VERSION "HNNBNNNYNNNNNNNNNNNNNNNNNNNNNNNNNNNNNNNNNN/4/%%%/4/'%**4NNN///"

NS_ :

BS_:

BU_: ADR_PAG_X2 BAP_Tester GW_App_PAG_PF GW_Routing_PAG_PF Klima_PAG_PF Klimakomp_Dash_PAG_PF Kombi_PAG_PF Miko_PAG_X2 OCU_PAG_PF RDK_High_PAG_PF

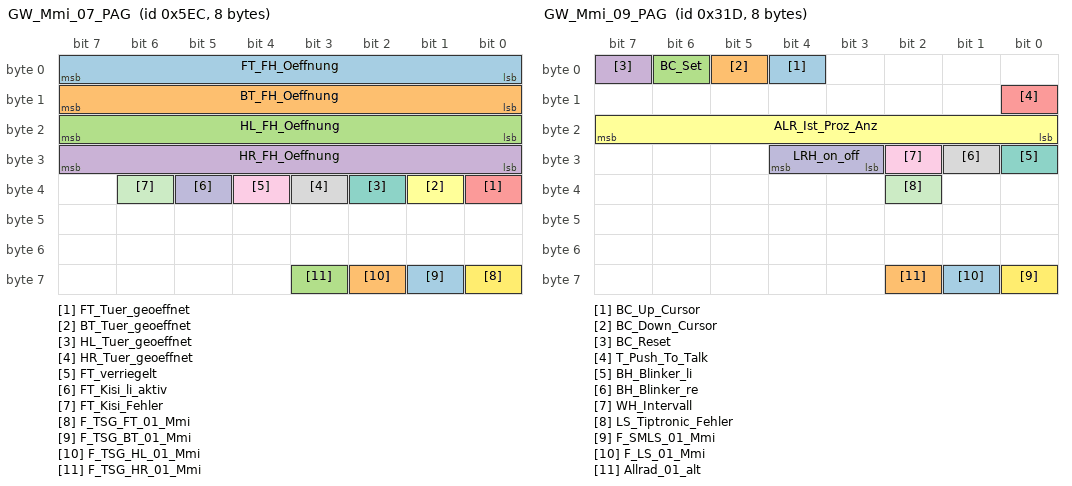
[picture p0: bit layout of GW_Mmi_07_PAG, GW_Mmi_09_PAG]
BO_ 1516 GW_Mmi_07_PAG: 8 GW_Routing_PAG_PF
 SG_ FT_FH_Oeffnung : 0|8@1+ (0.5,0) [0|100] "Unit_PerCent"  Klima_PAG_PF,OCU_PAG_PF
 SG_ BT_FH_Oeffnung : 8|8@1+ (0.5,0) [0|100] "Unit_PerCent"  Klima_PAG_PF,OCU_PAG_PF
 SG_ HL_FH_Oeffnung : 16|8@1+ (0.5,0) [0|100] "Unit_PerCent" Vector__XXX
 SG_ HR_FH_Oeffnung : 24|8@1+ (0.5,0) [0|100] "Unit_PerCent" Vector__XXX
 SG_ FT_Tuer_geoeffnet : 32|1@1+ (1,0) [0|1] ""  ADR_PAG_X2,Klima_PAG_PF,Kombi_PAG_PF
 SG_ BT_Tuer_geoeffnet : 33|1@1+ (1,0) [0|1] ""  Klima_PAG_PF,Kombi_PAG_PF
 SG_ HL_Tuer_geoeffnet : 34|1@1+ (1,0) [0|1] "" Vector__XXX
 SG_ HR_Tuer_geoeffnet : 35|1@1+ (1,0) [0|1] "" Vector__XXX
 SG_ FT_verriegelt : 36|1@1+ (1,0) [0|1] ""  Kombi_PAG_PF
 SG_ FT_Kisi_li_aktiv : 37|1@1+ (1,0) [0|1] ""  Klima_PAG_PF
 SG_ FT_Kisi_Fehler : 38|1@1+ (1,0) [0|1] "" Vector__XXX
 SG_ F_TSG_FT_01_Mmi : 56|1@1+ (1,0) [0|1] ""  ADR_PAG_X2,Klima_PAG_PF,Kombi_PAG_PF,OCU_PAG_PF
 SG_ F_TSG_BT_01_Mmi : 57|1@1+ (1,0) [0|1] ""  Klima_PAG_PF,Kombi_PAG_PF,OCU_PAG_PF
 SG_ F_TSG_HL_01_Mmi : 58|1@1+ (1,0) [0|1] "" Vector__XXX
 SG_ F_TSG_HR_01_Mmi : 59|1@1+ (1,0) [0|1] "" Vector__XXX

BO_ 797 GW_Mmi_09_PAG: 8 GW_Routing_PAG_PF
 SG_ BC_Up_Cursor : 4|1@1+ (1,0) [0|1] ""  Kombi_PAG_PF
 SG_ BC_Down_Cursor : 5|1@1+ (1,0) [0|1] ""  Kombi_PAG_PF
 SG_ BC_Set : 6|1@1+ (1,0) [0|1] ""  Kombi_PAG_PF
 SG_ BC_Reset : 7|1@1+ (1,0) [0|1] ""  Kombi_PAG_PF
 SG_ T_Push_To_Talk : 8|1@1+ (1,0) [0|1] "" Vector__XXX
 SG_ ALR_Ist_Proz_Anz : 16|8@1+ (0.4,0) [0|100] "Unit_PerCent" Vector__XXX
 SG_ BH_Blinker_li : 24|1@1+ (1,0) [0|1] "" Vector__XXX
 SG_ BH_Blinker_re : 25|1@1+ (1,0) [0|1] "" Vector__XXX
 SG_ WH_Intervall : 26|1@1+ (1,0) [0|1] ""  Klima_PAG_PF
 SG_ LRH_on_off : 27|2@1+ (1,0) [0|3] "" Vector__XXX
 SG_ LS_Tiptronic_Fehler : 34|1@1+ (1,0) [0|1] "" Vector__XXX
 SG_ F_SMLS_01_Mmi : 56|1@1+ (1,0) [0|1] ""  Klima_PAG_PF,Kombi_PAG_PF
 SG_ F_LS_01_Mmi : 57|1@1+ (1,0) [0|1] ""  Kombi_PAG_PF
 SG_ Allrad_01_alt : 58|1@1+ (1,0) [0|1] "" Vector__XXX

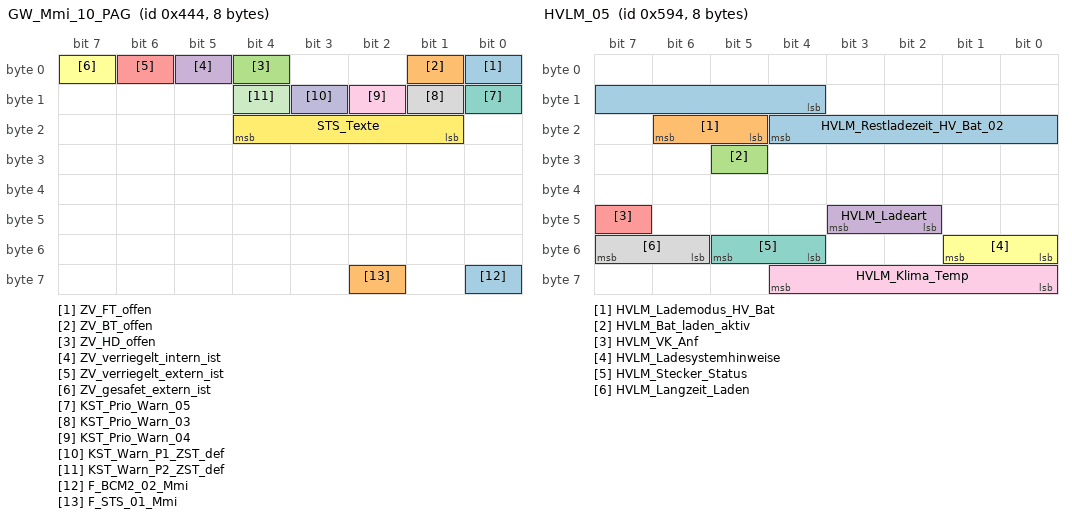
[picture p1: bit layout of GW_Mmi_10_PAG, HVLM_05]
BO_ 1092 GW_Mmi_10_PAG: 8 GW_Routing_PAG_PF
 SG_ ZV_FT_offen : 0|1@1+ (1,0) [0|1] "" Vector__XXX
 SG_ ZV_BT_offen : 1|1@1+ (1,0) [0|1] "" Vector__XXX
 SG_ ZV_HD_offen : 4|1@1+ (1,0) [0|1] ""  Kombi_PAG_PF
 SG_ ZV_verriegelt_intern_ist : 5|1@1+ (1,0) [0|1] ""  Klima_PAG_PF
 SG_ ZV_verriegelt_extern_ist : 6|1@1+ (1,0) [0|1] ""  ADR_PAG_X2
 SG_ ZV_gesafet_extern_ist : 7|1@1+ (1,0) [0|1] "" Vector__XXX
 SG_ KST_Prio_Warn_05 : 8|1@1+ (1,0) [0|1] ""  Kombi_PAG_PF
 SG_ KST_Prio_Warn_03 : 9|1@1+ (1,0) [0|1] ""  Kombi_PAG_PF
 SG_ KST_Prio_Warn_04 : 10|1@1+ (1,0) [0|1] ""  Kombi_PAG_PF
 SG_ KST_Warn_P1_ZST_def : 11|1@1+ (1,0) [0|1] ""  Kombi_PAG_PF
 SG_ KST_Warn_P2_ZST_def : 12|1@1+ (1,0) [0|1] ""  Kombi_PAG_PF
 SG_ STS_Texte : 17|4@1+ (1,0) [0|15] ""  Kombi_PAG_PF
 SG_ F_BCM2_02_Mmi : 56|1@1+ (1,0) [0|1] ""  ADR_PAG_X2,Klima_PAG_PF,Kombi_PAG_PF
 SG_ F_STS_01_Mmi : 58|1@1+ (1,0) [0|1] ""  Kombi_PAG_PF

BO_ 1315 GW_SVB_PAG: 8 GW_App_PAG_PF
 SG_ SVB_MEM_FS : 0|1@1+ (1,0) [0|1] "" Vector__XXX
 SG_ SVB_MEM_BFS : 1|1@1+ (1,0) [0|1] "" Vector__XXX
 SG_ SVB_SMLS : 2|1@1+ (1,0) [0|1] ""  Kombi_PAG_PF
 SG_ SVB_HDSG : 3|1@1+ (1,0) [0|1] "" Vector__XXX
 SG_ SVB_Lift : 4|1@1+ (1,0) [0|1] ""  Kombi_PAG_PF
 SG_ SVB_AAG : 5|1@1+ (1,0) [0|1] "" Vector__XXX
 SG_ SVB_TSG_FT : 6|1@1+ (1,0) [0|1] ""  Kombi_PAG_PF
 SG_ SVB_TSG_BT : 7|1@1+ (1,0) [0|1] ""  Kombi_PAG_PF
 SG_ SVB_RDK : 8|1@1+ (1,0) [0|1] ""  Kombi_PAG_PF
 SG_ SVB_BCM1 : 9|1@1+ (1,0) [0|1] ""  Kombi_PAG_PF
 SG_ SVB_BCM2 : 10|1@1+ (1,0) [0|1] ""  Kombi_PAG_PF
 SG_ SVB_TSG_HL : 11|1@1+ (1,0) [0|1] "" Vector__XXX
 SG_ SVB_TSG_HR : 12|1@1+ (1,0) [0|1] "" Vector__XXX
 SG_ SVB_VSG : 13|1@1+ (1,0) [0|1] "" Vector__XXX
 SG_ SVB_Topview : 14|1@1+ (1,0) [0|1] "" Vector__XXX
 SG_ SVB_Kombi : 16|1@1+ (1,0) [0|1] "" Vector__XXX
 SG_ SVB_BKE : 17|1@1+ (1,0) [0|1] ""  Kombi_PAG_PF
 SG_ SVB_PDC : 18|1@1+ (1,0) [0|1] "" Vector__XXX
 SG_ SVB_STH : 19|1@1+ (1,0) [0|1] "" Vector__XXX
 SG_ SVB_RearView : 20|1@1+ (1,0) [0|1] "" Vector__XXX
 SG_ SVB_Stoppuhr : 21|1@1+ (1,0) [0|1] "" Vector__XXX
 SG_ SVB_PCM : 22|1@1+ (1,0) [0|1] ""  Kombi_PAG_PF
 SG_ SVB_CDR : 23|1@1+ (1,0) [0|1] "" Vector__XXX
 SG_ SVB_Kompass : 24|1@1+ (1,0) [0|1] "" Vector__XXX
 SG_ SVB_ComBox : 25|1@1+ (1,0) [0|1] "" Vector__XXX
 SG_ SVB_LEH_VA : 26|1@1+ (1,0) [0|1] "" Vector__XXX
 SG_ SVB_Ladegeraet : 27|1@1+ (1,0) [0|1] "" Vector__XXX
 SG_ SVB_Motor : 28|1@1+ (1,0) [0|1] ""  Kombi_PAG_PF
 SG_ SVB_QSP : 29|1@1+ (1,0) [0|1] ""  Kombi_PAG_PF
 SG_ SVB_Getriebe : 30|1@1+ (1,0) [0|1] ""  Kombi_PAG_PF
 SG_ SVB_WHL : 31|1@1+ (1,0) [0|1] "" Vector__XXX
 SG_ SVB_Airbag : 32|1@1+ (1,0) [0|1] ""  Kombi_PAG_PF
 SG_ SVB_PSM_Ant : 33|1@1+ (1,0) [0|1] "" Vector__XXX
 SG_ SVB_PSM_Fwk : 34|1@1+ (1,0) [0|1] ""  Kombi_PAG_PF
 SG_ SVB_BMS : 35|1@1+ (1,0) [0|1] "" Vector__XXX
 SG_ SVB_LEH : 36|1@1+ (1,0) [0|1] "" Vector__XXX
 SG_ SVB_SCR : 37|1@1+ (1,0) [0|1] "" Vector__XXX
 SG_ SVB_EPB : 38|1@1+ (1,0) [0|1] ""  Kombi_PAG_PF
 SG_ SVB_SSC : 39|1@1+ (1,0) [0|1] "" Vector__XXX
 SG_ SVB_PDCC : 40|1@1+ (1,0) [0|1] ""  Kombi_PAG_PF
 SG_ SVB_LWS : 41|1@1+ (1,0) [0|1] "" Vector__XXX
 SG_ SVB_PASM_NRA : 42|1@1+ (1,0) [0|1] ""  Kombi_PAG_PF
 SG_ SVB_Allrad : 43|1@1+ (1,0) [0|1] "" Vector__XXX
 SG_ SVB_EPS : 44|1@1+ (1,0) [0|1] ""  Kombi_PAG_PF
 SG_ SVB_HAL : 45|1@1+ (1,0) [0|1] ""  Kombi_PAG_PF
 SG_ SVB_EBKV : 46|1@1+ (1,0) [0|1] "" Vector__XXX
 SG_ SVB_AFS : 47|1@1+ (1,0) [0|1] ""  Kombi_PAG_PF
 SG_ SVB_SWL : 48|1@1+ (1,0) [0|1] "" Vector__XXX
 SG_ SVB_SWR : 49|1@1+ (1,0) [0|1] "" Vector__XXX
 SG_ SVB_ACC : 50|1@1+ (1,0) [0|1] "" Vector__XXX
 SG_ SVB_SWA : 51|1@1+ (1,0) [0|1] "" Vector__XXX
 SG_ SVB_EHPS : 53|1@1+ (1,0) [0|1] "" Vector__XXX
 SG_ SVB_EKK : 54|1@1+ (1,0) [0|1] "" Vector__XXX
 SG_ SVB_Kamera : 55|1@1+ (1,0) [0|1] "" Vector__XXX
 SG_ SVB_AMP : 57|1@1+ (1,0) [0|1] "" Vector__XXX
 SG_ SVB_TV : 58|1@1+ (1,0) [0|1] "" Vector__XXX

BO_ 1428 HVLM_05: 8 GW_Routing_PAG_PF
 SG_ HVLM_Restladezeit_HV_Bat_02 : 12|9@1+ (5,0) [0|2545] "Unit_Minut"  ADR_PAG_X2,Kombi_PAG_PF
 SG_ HVLM_Lademodus_HV_Bat : 21|2@1+ (1,0) [0|3] ""  ADR_PAG_X2,Kombi_PAG_PF
 SG_ HVLM_Bat_laden_aktiv : 29|1@1+ (1,0) [0|1] ""  ADR_PAG_X2,Kombi_PAG_PF
 SG_ HVLM_Ladeart : 42|2@1+ (1,0) [0|3] ""  ADR_PAG_X2,Kombi_PAG_PF
 SG_ HVLM_VK_Anf : 47|1@1+ (1,0) [0|1] ""  Klima_PAG_PF
 SG_ HVLM_Ladesystemhinweise : 48|2@1+ (1,0) [0|3] ""  Kombi_PAG_PF
 SG_ HVLM_Stecker_Status : 52|2@1+ (1,0) [0|3] ""  ADR_PAG_X2,Kombi_PAG_PF
 SG_ HVLM_Langzeit_Laden : 54|2@1+ (1,0) [0|3] "" Vector__XXX
 SG_ HVLM_Klima_Temp : 56|5@1+ (0.5,15.5) [15.5|29.5] "Unit_DegreCelsi" Vector__XXX

BO_ 1397 HVLM_07_PAG: 8 GW_Routing_PAG_PF
 SG_ HVLM_Status_Timer_MUX M : 0|3@1+ (1,0) [0|7] ""  ADR_PAG_X2
 SG_ HVLM_Status_Timer_1_Jahr m1 : 3|7@1+ (1,2000) [2000|2125] "Unit_Year"  ADR_PAG_X2
 SG_ HVLM_Status_Timer_2_Jahr m2 : 3|7@1+ (1,2000) [2000|2125] "Unit_Year"  ADR_PAG_X2
 SG_ HVLM_Status_Timer_3_Jahr m3 : 3|7@1+ (1,2000) [2000|2125] "Unit_Year"  ADR_PAG_X2
 SG_ HVLM_Status_Timer_4_Jahr m4 : 3|7@1+ (1,2000) [2000|2125] "Unit_Year"  ADR_PAG_X2
 SG_ HVLM_Status_Timer_7_Jahr m7 : 3|7@1+ (1,2000) [2000|2125] "Unit_Year"  ADR_PAG_X2
 SG_ HVLM_Status_Timer_1_Minute m1 : 10|6@1+ (1,0) [0|59] "Unit_Minut"  ADR_PAG_X2
 SG_ HVLM_Status_Timer_2_Minute m2 : 10|6@1+ (1,0) [0|59] "Unit_Minut"  ADR_PAG_X2
 SG_ HVLM_Status_Timer_3_Minute m3 : 10|6@1+ (1,0) [0|59] "Unit_Minut"  ADR_PAG_X2
 SG_ HVLM_Status_Timer_4_Minute m4 : 10|6@1+ (1,0) [0|59] "Unit_Minut"  ADR_PAG_X2
 SG_ HVLM_Status_Timer_7_Minute m7 : 10|6@1+ (1,0) [0|59] "Unit_Minut"  ADR_PAG_X2
 SG_ HVLM_Status_Timer_1_Monat m1 : 16|4@1+ (1,0) [1|12] "Unit_Month"  ADR_PAG_X2
 SG_ HVLM_Status_Timer_2_Monat m2 : 16|4@1+ (1,0) [1|12] "Unit_Month"  ADR_PAG_X2
 SG_ HVLM_Status_Timer_3_Monat m3 : 16|4@1+ (1,0) [1|12] "Unit_Month"  ADR_PAG_X2
 SG_ HVLM_Status_Timer_4_Monat m4 : 16|4@1+ (1,0) [1|12] "Unit_Month"  ADR_PAG_X2
 SG_ HVLM_Status_Timer_7_Monat m7 : 16|4@1+ (1,0) [1|12] "Unit_Month"  ADR_PAG_X2
 SG_ HVLM_Status_Timer_1_Stunde m1 : 20|5@1+ (1,0) [0|23] "Unit_Hours"  ADR_PAG_X2
 SG_ HVLM_Status_Timer_2_Stunde m2 : 20|5@1+ (1,0) [0|23] "Unit_Hours"  ADR_PAG_X2
 SG_ HVLM_Status_Timer_3_Stunde m3 : 20|5@1+ (1,0) [0|23] "Unit_Hours"  ADR_PAG_X2
 SG_ HVLM_Status_Timer_4_Stunde m4 : 20|5@1+ (1,0) [0|23] "Unit_Hours"  ADR_PAG_X2
 SG_ HVLM_Status_Timer_7_Stunde m7 : 20|5@1+ (1,0) [0|23] "Unit_Hours"  ADR_PAG_X2
 SG_ HVLM_Status_Timer_1_Tag m1 : 25|5@1+ (1,0) [1|31] "Unit_Day"  ADR_PAG_X2
 SG_ HVLM_Status_Timer_2_Tag m2 : 25|5@1+ (1,0) [1|31] "Unit_Day"  ADR_PAG_X2
 SG_ HVLM_Status_Timer_3_Tag m3 : 25|5@1+ (1,0) [1|31] "Unit_Day"  ADR_PAG_X2
 SG_ HVLM_Status_Timer_4_Tag m4 : 25|5@1+ (1,0) [1|31] "Unit_Day"  ADR_PAG_X2
 SG_ HVLM_Status_Timer_7_Tag m7 : 25|5@1+ (1,0) [1|31] "Unit_Day"  ADR_PAG_X2
 SG_ HVLM_Status_Timer_1_Laden m1 : 30|1@1+ (1,0) [0|1] ""  ADR_PAG_X2
 SG_ HVLM_Status_Timer_2_Laden m2 : 30|1@1+ (1,0) [0|1] ""  ADR_PAG_X2
 SG_ HVLM_Status_Timer_3_Laden m3 : 30|1@1+ (1,0) [0|1] ""  ADR_PAG_X2
 SG_ HVLM_Status_Timer_4_Laden m4 : 30|1@1+ (1,0) [0|1] ""  ADR_PAG_X2
 SG_ HVLM_Status_Timer_1_Vorklima m1 : 31|1@1+ (1,0) [0|1] ""  ADR_PAG_X2
 SG_ HVLM_Status_Timer_2_Vorklima m2 : 31|1@1+ (1,0) [0|1] ""  ADR_PAG_X2
 SG_ HVLM_Status_Timer_3_Vorklima m3 : 31|1@1+ (1,0) [0|1] ""  ADR_PAG_X2
 SG_ HVLM_Status_Timer_4_Vorklima m4 : 31|1@1+ (1,0) [0|1] ""  ADR_PAG_X2
 SG_ HVLM_Status_Timer_1_Zyklus_Mo m1 : 32|1@1+ (1,0) [0|1] ""  ADR_PAG_X2
 SG_ HVLM_Status_Timer_2_Zyklus_Mo m2 : 32|1@1+ (1,0) [0|1] ""  ADR_PAG_X2
 SG_ HVLM_Status_Timer_3_Zyklus_Mo m3 : 32|1@1+ (1,0) [0|1] ""  ADR_PAG_X2
 SG_ HVLM_Status_Timer_4_Zyklus_Mo m4 : 32|1@1+ (1,0) [0|1] ""  ADR_PAG_X2
 SG_ HVLM_Status_Timer_1_Zyklus_Di m1 : 33|1@1+ (1,0) [0|1] ""  ADR_PAG_X2
 SG_ HVLM_Status_Timer_2_Zyklus_Di m2 : 33|1@1+ (1,0) [0|1] ""  ADR_PAG_X2
 SG_ HVLM_Status_Timer_3_Zyklus_Di m3 : 33|1@1+ (1,0) [0|1] ""  ADR_PAG_X2
 SG_ HVLM_Status_Timer_4_Zyklus_Di m4 : 33|1@1+ (1,0) [0|1] ""  ADR_PAG_X2
 SG_ HVLM_Status_Timer_1_Zyklus_Mi m1 : 34|1@1+ (1,0) [0|1] ""  ADR_PAG_X2
 SG_ HVLM_Status_Timer_2_Zyklus_Mi m2 : 34|1@1+ (1,0) [0|1] ""  ADR_PAG_X2
 SG_ HVLM_Status_Timer_3_Zyklus_Mi m3 : 34|1@1+ (1,0) [0|1] ""  ADR_PAG_X2
 SG_ HVLM_Status_Timer_4_Zyklus_Mi m4 : 34|1@1+ (1,0) [0|1] ""  ADR_PAG_X2
 SG_ HVLM_Status_Timer_1_Zyklus_Do m1 : 35|1@1+ (1,0) [0|1] ""  ADR_PAG_X2
 SG_ HVLM_Status_Timer_2_Zyklus_Do m2 : 35|1@1+ (1,0) [0|1] ""  ADR_PAG_X2
 SG_ HVLM_Status_Timer_3_Zyklus_Do m3 : 35|1@1+ (1,0) [0|1] ""  ADR_PAG_X2
 SG_ HVLM_Status_Timer_4_Zyklus_Do m4 : 35|1@1+ (1,0) [0|1] ""  ADR_PAG_X2
 SG_ HVLM_Status_Timer_1_Zyklus_Fr m1 : 36|1@1+ (1,0) [0|1] ""  ADR_PAG_X2
 SG_ HVLM_Status_Timer_2_Zyklus_Fr m2 : 36|1@1+ (1,0) [0|1] ""  ADR_PAG_X2
 SG_ HVLM_Status_Timer_3_Zyklus_Fr m3 : 36|1@1+ (1,0) [0|1] ""  ADR_PAG_X2
 SG_ HVLM_Status_Timer_4_Zyklus_Fr m4 : 36|1@1+ (1,0) [0|1] ""  ADR_PAG_X2
 SG_ HVLM_Status_Timer_1_Zyklus_Sa m1 : 37|1@1+ (1,0) [0|1] ""  ADR_PAG_X2
 SG_ HVLM_Status_Timer_2_Zyklus_Sa m2 : 37|1@1+ (1,0) [0|1] ""  ADR_PAG_X2
 SG_ HVLM_Status_Timer_3_Zyklus_Sa m3 : 37|1@1+ (1,0) [0|1] ""  ADR_PAG_X2
 SG_ HVLM_Status_Timer_4_Zyklus_Sa m4 : 37|1@1+ (1,0) [0|1] ""  ADR_PAG_X2
 SG_ HVLM_Status_Timer_1_Zyklus_So m1 : 38|1@1+ (1,0) [0|1] ""  ADR_PAG_X2
 SG_ HVLM_Status_Timer_2_Zyklus_So m2 : 38|1@1+ (1,0) [0|1] ""  ADR_PAG_X2
 SG_ HVLM_Status_Timer_3_Zyklus_So m3 : 38|1@1+ (1,0) [0|1] ""  ADR_PAG_X2
 SG_ HVLM_Status_Timer_4_Zyklus_So m4 : 38|1@1+ (1,0) [0|1] ""  ADR_PAG_X2
 SG_ HVLM_Status_Timer_1_Zyklus_WH m1 : 39|1@1+ (1,0) [0|1] ""  ADR_PAG_X2
 SG_ HVLM_Status_Timer_2_Zyklus_WH m2 : 39|1@1+ (1,0) [0|1] ""  ADR_PAG_X2
 SG_ HVLM_Status_Timer_3_Zyklus_WH m3 : 39|1@1+ (1,0) [0|1] ""  ADR_PAG_X2
 SG_ HVLM_Status_Timer_4_Zyklus_WH m4 : 39|1@1+ (1,0) [0|1] ""  ADR_PAG_X2
 SG_ HVLM_Status_Nachtstrom_X_Std_Anf : 40|6@1+ (0.5,0) [0|23.5] "Unit_Hours" Vector__XXX
 SG_ HVLM_Status_Nachtstrom_Prof : 46|2@1+ (1,0) [0|3] "" Vector__XXX
 SG_ HVLM_Status_Nachtstrom_X_Std_End : 48|6@1+ (0.5,0) [0|23.5] "Unit_Hours" Vector__XXX
 SG_ HVLM_Status_Nachtstrom_Akt_Prof : 54|2@1+ (1,0) [0|3] "" Vector__XXX
 SG_ HVLM_Status_Laden : 56|3@1+ (1,0) [0|7] "" Vector__XXX

BO_ 1895 ISO_eCall_Req: 8 GW_Routing_PAG_PF
 SG_ ISO_eCall_Req_Data : 0|64@1+ (1,0) [0|1.84467440737096E+019] ""  OCU_PAG_PF

BO_ 2001 ISO_eCall_Resp: 8 OCU_PAG_PF
 SG_ ISO_eCall_Resp_Data : 0|64@1+ (1,0) [0|1.84467440737096E+019] ""  GW_Routing_PAG_PF

BO_ 1792 ISO_Funktionaler_Req_All: 8 GW_Routing_PAG_PF
 SG_ ISO_ALL_01_Req_Data : 0|64@1+ (1,0) [0|1.84467440737096E+019] ""  ADR_PAG_X2,Klima_PAG_PF,Klimakomp_Dash_PAG_PF,Kombi_PAG_PF,Miko_PAG_X2,OCU_PAG_PF,RDK_High_PAG_PF

BO_ 1907 ISO_Info_El_Req: 8 GW_Routing_PAG_PF
 SG_ ISO_Info_El_Req_Data : 0|64@1+ (1,0) [0|1.84467440737096E+019] ""  ADR_PAG_X2

BO_ 2013 ISO_Info_El_Resp: 8 ADR_PAG_X2
 SG_ ISO_Info_El_Resp_Data : 0|64@1+ (1,0) [0|1.84467440737096E+019] ""  GW_Routing_PAG_PF

BO_ 1862 ISO_Klima_Req: 8 GW_Routing_PAG_PF
 SG_ ISO_Klima_Req_Data : 0|64@1+ (1,0) [0|1.84467440737096E+019] ""  Klima_PAG_PF

BO_ 1968 ISO_Klima_Resp: 8 Klima_PAG_PF
 SG_ ISO_Klima_Resp_Data : 0|64@1+ (1,0) [0|1.84467440737096E+019] ""  GW_Routing_PAG_PF

BO_ 1817 ISO_Klimakomp_Req: 8 GW_Routing_PAG_PF
 SG_ ISO_Klimakomp_Req_Data : 0|64@1+ (1,0) [0|1.84467440737096E+019] ""  Klimakomp_Dash_PAG_PF

BO_ 1923 ISO_Klimakomp_Resp: 8 Klimakomp_Dash_PAG_PF
 SG_ ISO_Klimakomp_Resp_Data : 0|64@1+ (1,0) [0|1.84467440737096E+019] ""  GW_Routing_PAG_PF

BO_ 1812 ISO_Kombi_Req: 8 GW_Routing_PAG_PF
 SG_ ISO_Kombi_Req_Data : 0|64@1+ (1,0) [0|1.84467440737096E+019] ""  Kombi_PAG_PF

BO_ 1918 ISO_Kombi_Resp: 8 Kombi_PAG_PF
 SG_ ISO_Kombi_Resp_Data : 0|64@1+ (1,0) [0|1.84467440737096E+019] ""  GW_Routing_PAG_PF

BO_ 1846 ISO_Miko_Req: 8 GW_Routing_PAG_PF
 SG_ ISO_Miko_Req_Data : 0|64@1+ (1,0) [0|1.84467440737096E+019] ""  Miko_PAG_X2

BO_ 1952 ISO_Miko_Resp: 8 Miko_PAG_X2
 SG_ ISO_Miko_Resp_Data : 0|64@1+ (1,0) [0|1.84467440737096E+019] ""  GW_Routing_PAG_PF

BO_ 1803 ISO_RDK_Req: 8 GW_Routing_PAG_PF
 SG_ ISO_RDK_Req_Data : 0|64@1+ (1,0) [0|1.84467440737096E+019] ""  RDK_High_PAG_PF

BO_ 1909 ISO_RDK_Resp: 8 RDK_High_PAG_PF
 SG_ ISO_RDK_Resp_Data : 0|64@1+ (1,0) [0|1.84467440737096E+019] ""  GW_Routing_PAG_PF

BO_ 1424 Kessy_02: 8 GW_Routing_PAG_PF
 SG_ KY_Funkschl_Nr : 0|4@1+ (1,0) [0|15] ""  Klima_PAG_PF,Kombi_PAG_PF
 SG_ KY_ID_Geb_autorisiert : 4|1@1+ (1,0) [0|1] "" Vector__XXX
 SG_ KY_ID_Geb_steckt : 5|1@1+ (1,0) [0|1] "" Vector__XXX
 SG_ KY_FFB_Frequenz : 6|2@1+ (1,0) [0|3] "" Vector__XXX
 SG_ KY_HF_Aktiv : 8|1@1+ (1,0) [0|1] "" Vector__XXX
 SG_ KY_LF_Aktiv : 9|1@1+ (1,0) [0|1] "" Vector__XXX
 SG_ KY_ELV_verr : 10|1@1+ (1,0) [0|1] "" Vector__XXX
 SG_ KY_ELV_entr : 11|1@1+ (1,0) [0|1] "" Vector__XXX
 SG_ KY_ELV_enable_Anforderung : 12|1@1+ (1,0) [0|1] "" Vector__XXX
 SG_ KY_Valet_Parking : 14|1@1+ (1,0) [0|1] "" Vector__XXX
 SG_ KY_Keyless_Verbau : 15|1@1+ (1,0) [0|1] "" Vector__XXX
 SG_ KY_FBS_Fahrer_Hinweise : 16|3@1+ (1,0) [0|7] "" Vector__XXX
 SG_ FBS_Warn_Lenkung_def : 19|1@1+ (1,0) [0|1] ""  Kombi_PAG_PF
 SG_ FBS_Warn_LenkVerriegelung_def : 20|1@1+ (1,0) [0|1] ""  Kombi_PAG_PF
 SG_ FBS_Warn_Schluessel_Batt : 21|1@1+ (1,0) [0|1] ""  Kombi_PAG_PF
 SG_ FBS_Prio_Warn_04 : 22|1@1+ (1,0) [0|1] ""  Kombi_PAG_PF
 SG_ FBS_Prio_Warn_05 : 23|1@1+ (1,0) [0|1] ""  Kombi_PAG_PF
 SG_ KY_KYL_Fahrer_Hinweise : 24|3@1+ (1,0) [0|7] "" Vector__XXX
 SG_ KYL_Warn_kein_Schluessel : 27|1@1+ (1,0) [0|1] "" Vector__XXX
 SG_ KYL_Warn_Kessy_defekt : 28|1@1+ (1,0) [0|1] "" Vector__XXX
 SG_ KY_KYL_Prio_Warn_03 : 29|1@1+ (1,0) [0|1] "" Vector__XXX
 SG_ KY_KYL_Prio_Warn_04 : 30|1@1+ (1,0) [0|1] "" Vector__XXX
 SG_ KY_KYL_Prio_Warn_05 : 31|1@1+ (1,0) [0|1] "" Vector__XXX
 SG_ KY_Schluessel_Soll : 32|4@1+ (1,0) [0|15] ""  Kombi_PAG_PF
 SG_ KY_Schluessel_Ist : 36|4@1+ (1,0) [0|15] ""  Kombi_PAG_PF
 SG_ KY_WFS_Safe : 40|1@1+ (1,0) [0|1] ""  Kombi_PAG_PF
 SG_ KY_WFS_LZ : 41|2@1+ (1,0) [0|3] ""  Kombi_PAG_PF
 SG_ KY_StartStopp_Info : 43|2@1+ (1,0) [0|3] "" Vector__XXX
 SG_ KYL_Notzuendschloss : 45|1@1+ (1,0) [0|1] "" Vector__XXX
 SG_ KYL_Warn_Notzuendschloss : 46|1@1+ (1,0) [0|1] "" Vector__XXX
 SG_ FBS_KD_Fehler : 47|1@1+ (1,0) [0|1] "" Vector__XXX
 SG_ SK_Anf_DTC_Abfrage : 48|1@1+ (1,0) [0|1] "" Vector__XXX
 SG_ SK_Anf_DTC_Abfrage_sofort : 49|1@1+ (1,0) [0|1] "" Vector__XXX

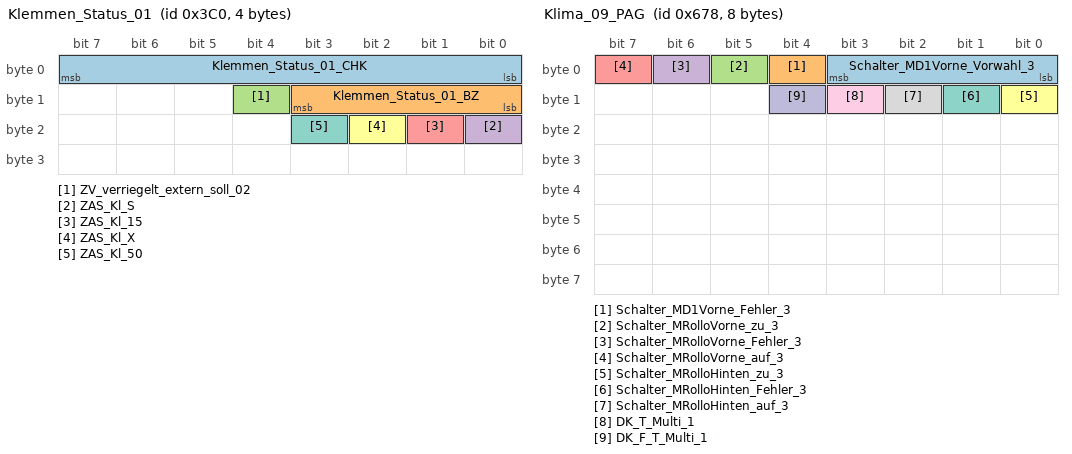
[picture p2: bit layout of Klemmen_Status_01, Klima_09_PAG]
BO_ 960 Klemmen_Status_01: 4 GW_Routing_PAG_PF
 SG_ Klemmen_Status_01_CHK : 0|8@1+ (1,0) [0|255] "" Vector__XXX
 SG_ Klemmen_Status_01_BZ : 8|4@1+ (1,0) [0|15] "" Vector__XXX
 SG_ ZV_verriegelt_extern_soll_02 : 12|1@1+ (1,0) [0|1] "" Vector__XXX
 SG_ ZAS_Kl_S : 16|1@1+ (1,0) [0|1] ""  ADR_PAG_X2,Kombi_PAG_PF,OCU_PAG_PF,RDK_High_PAG_PF
 SG_ ZAS_Kl_15 : 17|1@1+ (1,0) [0|1] ""  ADR_PAG_X2,Klima_PAG_PF,Kombi_PAG_PF,Miko_PAG_X2,OCU_PAG_PF,RDK_High_PAG_PF
 SG_ ZAS_Kl_X : 18|1@1+ (1,0) [0|1] ""  OCU_PAG_PF
 SG_ ZAS_Kl_50 : 19|1@1+ (1,0) [0|1] ""  Klima_PAG_PF,Kombi_PAG_PF,Miko_PAG_X2,RDK_High_PAG_PF

BO_ 959 Klima_01: 8 Klima_PAG_PF
 SG_ KL_Drehz_Anh : 0|1@1+ (1,0) [0|1] ""  GW_Routing_PAG_PF
 SG_ KL_Vorwarn_Komp_ein : 1|1@1+ (1,0) [0|1] ""  GW_Routing_PAG_PF
 SG_ KL_Handshake_BEM : 2|1@1+ (1,0) [0|1] ""  GW_App_PAG_PF,GW_Routing_PAG_PF
 SG_ KL_Komp_Moment_alt : 3|1@1+ (1,0) [0|1] ""  GW_Routing_PAG_PF
 SG_ KL_Vorwarn_HHS_ein : 4|1@1+ (1,0) [0|1] ""  GW_Routing_PAG_PF
 SG_ KL_Vorwarn_HFS_ein : 5|1@1+ (1,0) [0|1] ""  GW_Routing_PAG_PF
 SG_ KL_Vorwarn_Zuheizer_ein : 6|1@1+ (1,0) [0|1] ""  GW_Routing_PAG_PF
 SG_ KL_KD_Fehler : 7|1@1+ (1,0) [0|1] ""  GW_App_PAG_PF,GW_Routing_PAG_PF
 SG_ KL_Comp_rev_rq : 8|8@1+ (50,0) [0|8600] "Unit_MinutInver"  GW_Routing_PAG_PF,Klimakomp_Dash_PAG_PF
 SG_ KL_Charisma_FahrPr : 16|3@1+ (1,0) [0|7] ""  GW_Routing_PAG_PF
 SG_ KL_Charisma_Status : 19|2@1+ (1,0) [0|3] ""  GW_Routing_PAG_PF
 SG_ KL_Charisma_Umschaltung : 21|2@1+ (1,0) [0|3] ""  GW_Routing_PAG_PF
 SG_ KL_Last_Kompr : 24|8@1+ (0.25,0) [0|63.5] "Unit_NewtoMeter"  GW_Routing_PAG_PF
 SG_ KL_Leistung_Hzg_Soll : 32|8@1+ (11,0) [0|2805] "Unit_Watt"  GW_Routing_PAG_PF
 SG_ KL_Anf_KL : 40|8@1+ (0.4,0) [0|101.6] "Unit_PerCent"  GW_Routing_PAG_PF
 SG_ KL_4_Zonen : 48|1@1+ (1,0) [0|1] ""  GW_Routing_PAG_PF
 SG_ KL_AC_Schalter : 49|1@1+ (1,0) [0|1] ""  GW_Routing_PAG_PF
 SG_ KL_Zustand : 50|1@1+ (1,0) [0|1] ""  GW_Routing_PAG_PF
 SG_ KL_Thermomanagement : 51|2@1+ (1,0) [0|3] ""  GW_Routing_PAG_PF
 SG_ KL_Comp_enable : 53|1@1+ (1,0) [0|1] ""  GW_Routing_PAG_PF,Klimakomp_Dash_PAG_PF
 SG_ KL_StartStopp_Info : 54|2@1+ (1,0) [0|3] ""  GW_Routing_PAG_PF
 SG_ KL_el_Zuheizer_Stufe : 56|3@1+ (1,0) [0|7] ""  GW_Routing_PAG_PF
 SG_ KL_Diag_Absperrvent : 59|4@1+ (1,0) [0|15] ""  GW_Routing_PAG_PF

BO_ 1636 Klima_02: 8 Klima_PAG_PF
 SG_ KL_Stromsparmodus : 0|1@1+ (1,0) [0|1] ""  GW_Routing_PAG_PF
 SG_ KL_Spg_Hzg_aus : 1|1@1+ (1,0) [0|1] ""  GW_Routing_PAG_PF
 SG_ KL_AQS_Empfindlichkeit : 2|3@1+ (1,0) [0|7] ""  GW_Routing_PAG_PF
 SG_ KL_SIH_Soll_li : 8|3@1+ (1,0) [0|7] ""  GW_Routing_PAG_PF
 SG_ KL_SIH_Takt_li : 11|1@1+ (1,0) [0|1] ""  GW_Routing_PAG_PF
 SG_ KL_SIL_Soll_li : 12|3@1+ (1,0) [0|7] ""  GW_Routing_PAG_PF
 SG_ KL_LRH_aus : 15|1@1+ (1,0) [0|1] ""  GW_Routing_PAG_PF
 SG_ KL_SIH_Soll_re : 16|3@1+ (1,0) [0|7] ""  GW_Routing_PAG_PF
 SG_ KL_SIH_Takt_re : 19|1@1+ (1,0) [0|1] ""  GW_Routing_PAG_PF
 SG_ KL_SIL_Soll_re : 20|3@1+ (1,0) [0|7] ""  GW_Routing_PAG_PF
 SG_ KL_Beschlagsgefahr : 23|1@1+ (1,0) [0|1] ""  GW_App_PAG_PF,GW_Routing_PAG_PF
 SG_ KL_HSH_ein_Soll : 24|1@1+ (1,0) [0|1] ""  GW_Routing_PAG_PF
 SG_ KL_HSH_Taktung : 25|1@1+ (1,0) [0|1] ""  GW_Routing_PAG_PF
 SG_ KL_Zuheizer_Freigabe : 26|1@1+ (1,0) [0|1] ""  GW_Routing_PAG_PF
 SG_ KL_ZHE_Status : 27|1@1+ (1,0) [0|1] ""  GW_Routing_PAG_PF
 SG_ KL_FSH_Status : 28|2@1+ (1,0) [0|3] ""  GW_Routing_PAG_PF
 SG_ KL_LRH_on_off : 30|1@1+ (1,0) [0|1] ""  GW_Routing_PAG_PF
 SG_ KL_Umluftklappe_Status : 32|4@1+ (1,0) [0|15] ""  GW_Routing_PAG_PF
 SG_ KL_Geblaese_Status : 36|4@1+ (1,0) [0|15] ""  ADR_PAG_X2,GW_App_PAG_PF,GW_Routing_PAG_PF,Kombi_PAG_PF
 SG_ KL_I_Geblaese : 40|8@1+ (0.25,0) [0|63.5] "Unit_Amper"  GW_App_PAG_PF,GW_Routing_PAG_PF
 SG_ KL_Kompressorstrom_soll : 48|10@1+ (1,0) [0|1021] ""  GW_Routing_PAG_PF
 SG_ KL_FSH_P_Soll : 58|6@1+ (20,0) [0|1240] "Unit_Watt"  GW_Routing_PAG_PF

BO_ 1646 Klima_03: 7 Klima_PAG_PF
 SG_ KL_STL_aktiv : 0|1@1+ (1,0) [0|1] ""  GW_Routing_PAG_PF
 SG_ KL_STH_aktiv : 1|1@1+ (1,0) [0|1] ""  GW_Routing_PAG_PF
 SG_ KL_Solarluefter_aktiv : 2|1@1+ (1,0) [0|1] ""  GW_Routing_PAG_PF
 SG_ KL_Umluft_Taste : 3|1@1+ (1,0) [0|1] ""  GW_Routing_PAG_PF
 SG_ KL_Geblaese_Fond_Status : 4|4@1+ (1,0) [0|15] ""  GW_Routing_PAG_PF
 SG_ KL_STH_Ansteuerung : 8|2@1+ (1,0) [0|3] ""  GW_Routing_PAG_PF
 SG_ KL_STH_Betriebsdauer : 10|6@1+ (1,0) [0|60] "Unit_Minut"  GW_Routing_PAG_PF
 SG_ KL_Magnetventil : 16|1@1+ (1,0) [0|1] ""  GW_Routing_PAG_PF
 SG_ KL_WaPu : 17|1@1+ (1,0) [0|1] ""  GW_Routing_PAG_PF
 SG_ KL_Freigabe_KRH_li : 18|3@1+ (1,0) [0|7] ""  GW_Routing_PAG_PF
 SG_ KL_Freigabe_KRH_re : 21|3@1+ (1,0) [0|7] ""  GW_Routing_PAG_PF
 SG_ KL_BCmE_Livetip_Freigabe : 24|1@1+ (1,0) [0|1] ""  GW_Routing_PAG_PF
 SG_ KL_HYB_ASV_hinten_schliessen_Anf : 25|1@1+ (1,0) [0|1] ""  GW_Routing_PAG_PF
 SG_ KL_HYB_ASV_vorne_schliessen_Anf : 26|1@1+ (1,0) [0|1] ""  GW_Routing_PAG_PF
 SG_ KL_HYB_Spuelbetrieb_Freigabe : 27|1@1+ (1,0) [0|1] ""  GW_Routing_PAG_PF
 SG_ KL_Fehler_ElWaPu : 28|1@1+ (1,0) [0|1] ""  GW_Routing_PAG_PF
 SG_ KL_Innen_Temp : 32|8@1+ (0.5,-50) [-50|76] "Unit_DegreCelsi"  GW_Routing_PAG_PF,OCU_PAG_PF
 SG_ KL_Sonnenintensitaet : 40|8@1+ (10,0) [0|1000] "Unit_WattPerMeterSquar"  ADR_PAG_X2,GW_Routing_PAG_PF,Miko_PAG_X2
 SG_ KL_AussenTemp_WK : 48|8@1+ (0.5,-50) [-50|76] "Unit_DegreCelsi"  GW_Routing_PAG_PF

BO_ 1655 Klima_08_PAG: 8 Klima_PAG_PF
 SG_ KL_T_PSM_off : 0|1@1+ (1,0) [0|1] ""  GW_Routing_PAG_PF
 SG_ KL_T_HSpoiler : 1|1@1+ (1,0) [0|1] ""  GW_Routing_PAG_PF
 SG_ KL_T_PASM_1 : 2|1@1+ (1,0) [0|1] ""  GW_Routing_PAG_PF
 SG_ KL_T_PASM_2 : 3|1@1+ (1,0) [0|1] ""  GW_Routing_PAG_PF
 SG_ KL_T_FSH : 4|1@1+ (1,0) [0|1] ""  GW_Routing_PAG_PF
 SG_ KL_T_ZV : 6|1@1+ (1,0) [0|1] ""  GW_Routing_PAG_PF
 SG_ KL_T_Abgasklappe : 7|1@1+ (1,0) [0|1] ""  GW_Routing_PAG_PF
 SG_ KL_T_Rollo_kurz : 8|1@1+ (1,0) [0|1] ""  GW_Routing_PAG_PF
 SG_ KL_T_Rollo_lang : 9|1@1+ (1,0) [0|1] ""  GW_Routing_PAG_PF
 SG_ KL_T_STH : 11|1@1+ (1,0) [0|1] ""  GW_App_PAG_PF,GW_Routing_PAG_PF
 SG_ KL_Sportmodus : 13|3@1+ (1,0) [0|7] ""  GW_Routing_PAG_PF
 SG_ KL_T_TC_off : 16|1@1+ (1,0) [0|1] ""  GW_Routing_PAG_PF
 SG_ KL_T_LeVerstFond : 17|2@1+ (1,0) [0|3] ""  GW_Routing_PAG_PF
 SG_ KL_T_SitzLVerstFond : 19|2@1+ (1,0) [0|3] ""  GW_Routing_PAG_PF
 SG_ KL_Charisma_Anzeige : 21|3@1+ (1,0) [0|7] ""  GW_App_PAG_PF,GW_Routing_PAG_PF,Kombi_PAG_PF
 SG_ KL_Charisma_Anzeige_Umschaltung : 24|1@1+ (1,0) [0|1] ""  GW_Routing_PAG_PF,Kombi_PAG_PF
 SG_ KL_Segeln_Anf_deaktivieren : 25|1@1+ (1,0) [0|1] ""  GW_Routing_PAG_PF
 SG_ KL_T_HDC : 26|1@1+ (1,0) [0|1] ""  GW_Routing_PAG_PF
 SG_ HYB_Anf_E_Mode : 27|1@1+ (1,0) [0|1] ""  GW_Routing_PAG_PF
 SG_ FSM_Status : 28|1@1+ (1,0) [0|1] ""  GW_Routing_PAG_PF
 SG_ KL_Niv_up : 29|1@1+ (1,0) [0|1] ""  GW_Routing_PAG_PF
 SG_ KL_Niv_down : 30|1@1+ (1,0) [0|1] ""  GW_Routing_PAG_PF
 SG_ KL_T_PASM_3 : 31|1@1+ (1,0) [0|1] ""  GW_Routing_PAG_PF
 SG_ KL_T_VD : 36|2@1+ (1,0) [0|3] ""  GW_Routing_PAG_PF
 SG_ KL_T_Windschott : 38|2@1+ (1,0) [0|3] ""  GW_Routing_PAG_PF
 SG_ KL_St_Atemp : 40|3@1+ (1,0) [0|7] ""  GW_Routing_PAG_PF
 SG_ Statusbit_Offroad_aktiv : 43|1@1+ (1,0) [0|1] ""  GW_Routing_PAG_PF
 SG_ KL_T_StSt_deaktiv : 45|1@1+ (1,0) [0|1] ""  GW_Routing_PAG_PF
 SG_ KL_T_LDW : 46|1@1+ (1,0) [0|1] ""  GW_Routing_PAG_PF
 SG_ KL_Atemp_ungef : 48|8@1+ (0.5,-49.5) [-49.5|77] "Unit_DegreCelsi"  GW_Routing_PAG_PF,Kombi_PAG_PF

BO_ 1656 Klima_09_PAG: 8 Klima_PAG_PF
 SG_ Schalter_MD1Vorne_Vorwahl_3 : 0|4@1+ (1,0) [0|15] ""  GW_Routing_PAG_PF
 SG_ Schalter_MD1Vorne_Fehler_3 : 4|1@1+ (1,0) [0|1] ""  GW_Routing_PAG_PF
 SG_ Schalter_MRolloVorne_zu_3 : 5|1@1+ (1,0) [0|1] ""  GW_Routing_PAG_PF
 SG_ Schalter_MRolloVorne_Fehler_3 : 6|1@1+ (1,0) [0|1] ""  GW_Routing_PAG_PF
 SG_ Schalter_MRolloVorne_auf_3 : 7|1@1+ (1,0) [0|1] ""  GW_Routing_PAG_PF
 SG_ Schalter_MRolloHinten_zu_3 : 8|1@1+ (1,0) [0|1] ""  GW_Routing_PAG_PF
 SG_ Schalter_MRolloHinten_Fehler_3 : 9|1@1+ (1,0) [0|1] ""  GW_Routing_PAG_PF
 SG_ Schalter_MRolloHinten_auf_3 : 10|1@1+ (1,0) [0|1] ""  GW_Routing_PAG_PF
 SG_ DK_T_Multi_1 : 11|1@1+ (1,0) [0|1] ""  GW_Routing_PAG_PF
 SG_ DK_F_T_Multi_1 : 12|1@1+ (1,0) [0|1] ""  GW_Routing_PAG_PF

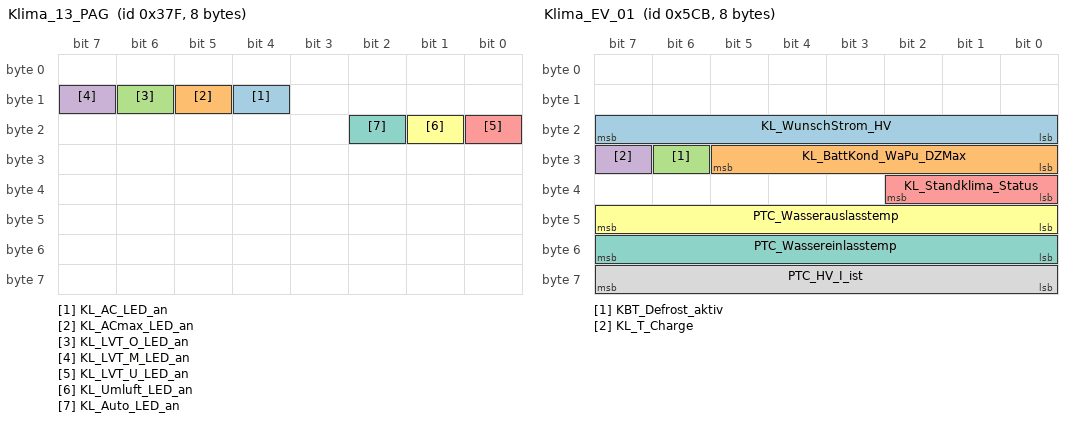
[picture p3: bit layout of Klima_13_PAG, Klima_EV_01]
BO_ 895 Klima_13_PAG: 8 Klima_PAG_PF
 SG_ KL_AC_LED_an : 12|1@1+ (1,0) [0|1] ""  Miko_PAG_X2
 SG_ KL_ACmax_LED_an : 13|1@1+ (1,0) [0|1] ""  Miko_PAG_X2
 SG_ KL_LVT_O_LED_an : 14|1@1+ (1,0) [0|1] ""  ADR_PAG_X2
 SG_ KL_LVT_M_LED_an : 15|1@1+ (1,0) [0|1] ""  ADR_PAG_X2
 SG_ KL_LVT_U_LED_an : 16|1@1+ (1,0) [0|1] ""  ADR_PAG_X2
 SG_ KL_Umluft_LED_an : 17|1@1+ (1,0) [0|1] ""  Miko_PAG_X2
 SG_ KL_Auto_LED_an : 18|1@1+ (1,0) [0|1] ""  Miko_PAG_X2

BO_ 1483 Klima_EV_01: 8 Klima_PAG_PF
 SG_ KL_WunschStrom_HV : 16|8@1+ (0.25,0) [0|63.25] "Unit_Amper"  GW_App_PAG_PF,GW_Routing_PAG_PF
 SG_ KL_BattKond_WaPu_DZMax : 24|6@1+ (2,0) [0|100] "Unit_PerCent"  GW_Routing_PAG_PF
 SG_ KBT_Defrost_aktiv : 30|1@1+ (1,0) [0|1] ""  GW_App_PAG_PF,GW_Routing_PAG_PF,Miko_PAG_X2
 SG_ KL_T_Charge : 31|1@1+ (1,0) [0|1] ""  GW_Routing_PAG_PF
 SG_ KL_Standklima_Status : 32|3@1+ (1,0) [0|7] ""  GW_App_PAG_PF,GW_Routing_PAG_PF
 SG_ PTC_Wasserauslasstemp : 40|8@1+ (1,-50) [-50|203] "Unit_DegreCelsi"  GW_Routing_PAG_PF
 SG_ PTC_Wassereinlasstemp : 48|8@1+ (1,-50) [-50|203] "Unit_DegreCelsi"  GW_Routing_PAG_PF
 SG_ PTC_HV_I_ist : 56|8@1+ (0.25,0) [0|63.25] "Unit_Amper"  GW_App_PAG_PF,GW_Routing_PAG_PF

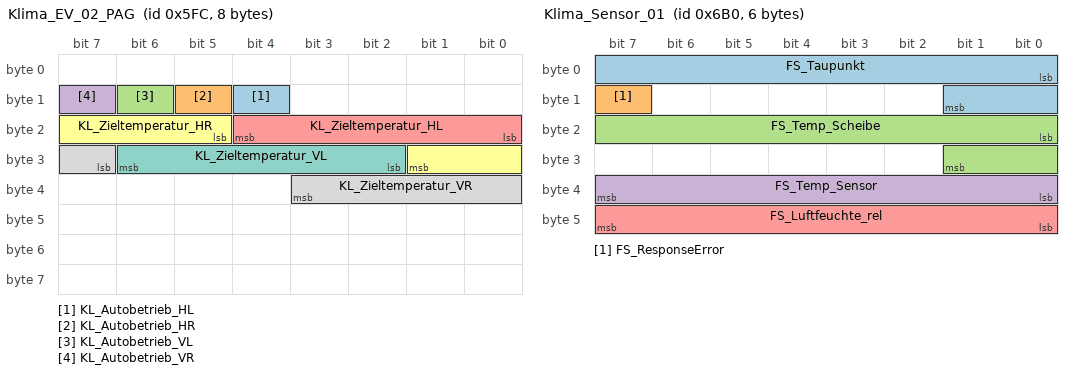
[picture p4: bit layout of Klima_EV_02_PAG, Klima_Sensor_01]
BO_ 1532 Klima_EV_02_PAG: 8 Klima_PAG_PF
 SG_ KL_Autobetrieb_HL : 12|1@1+ (1,0) [0|1] ""  GW_Routing_PAG_PF
 SG_ KL_Autobetrieb_HR : 13|1@1+ (1,0) [0|1] ""  GW_Routing_PAG_PF
 SG_ KL_Autobetrieb_VL : 14|1@1+ (1,0) [0|1] ""  GW_Routing_PAG_PF
 SG_ KL_Autobetrieb_VR : 15|1@1+ (1,0) [0|1] ""  GW_Routing_PAG_PF
 SG_ KL_Zieltemperatur_HL : 16|5@1+ (0.5,15.5) [16|29.5] "Unit_DegreCelsi"  GW_Routing_PAG_PF
 SG_ KL_Zieltemperatur_HR : 21|5@1+ (0.5,15.5) [16|29.5] "Unit_DegreCelsi"  GW_Routing_PAG_PF
 SG_ KL_Zieltemperatur_VL : 26|5@1+ (0.5,15.5) [16|29.5] "Unit_DegreCelsi"  GW_Routing_PAG_PF
 SG_ KL_Zieltemperatur_VR : 31|5@1+ (0.5,15.5) [16|29.5] "Unit_DegreCelsi"  GW_Routing_PAG_PF

BO_ 1712 Klima_Sensor_01: 6 GW_Routing_PAG_PF
 SG_ FS_Taupunkt : 0|10@1+ (0.1,-39.6) [-39.5|60.4] "Unit_DegreCelsi"  Klima_PAG_PF
 SG_ FS_ResponseError : 15|1@1+ (1,0) [0|1] "" Vector__XXX
 SG_ FS_Temp_Scheibe : 16|10@1+ (0.1,-39.6) [-39.5|60.4] "Unit_DegreCelsi"  Klima_PAG_PF
 SG_ FS_Temp_Sensor : 32|8@1+ (0.5,-40) [-39.5|87] "Unit_DegreCelsi"  Klima_PAG_PF
 SG_ FS_Luftfeuchte_rel : 40|8@1+ (0.5,-0.5) [0|100] "Unit_PerCent"  Klima_PAG_PF

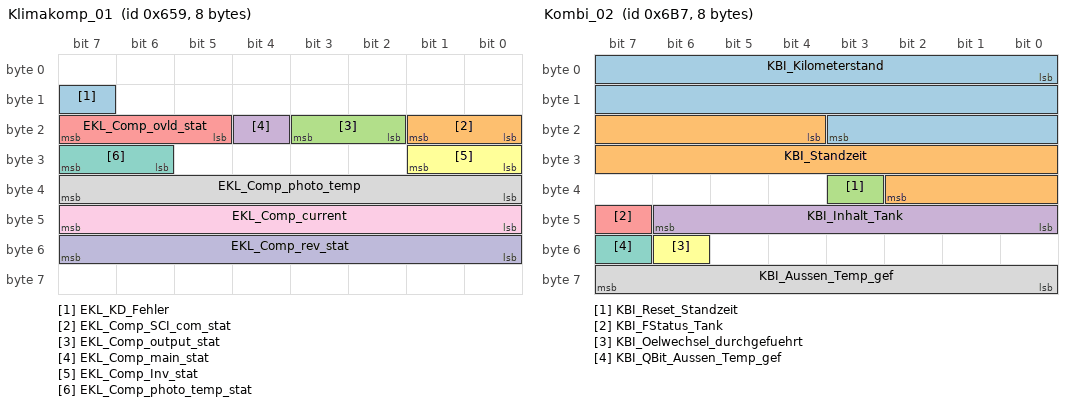
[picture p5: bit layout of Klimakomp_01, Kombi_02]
BO_ 1625 Klimakomp_01: 8 Klimakomp_Dash_PAG_PF
 SG_ EKL_KD_Fehler : 15|1@1+ (1,0) [0|1] ""  GW_Routing_PAG_PF,Klima_PAG_PF
 SG_ EKL_Comp_SCI_com_stat : 16|2@1+ (1,0) [0|3] ""  GW_Routing_PAG_PF,Klima_PAG_PF
 SG_ EKL_Comp_output_stat : 18|2@1+ (1,0) [0|3] ""  GW_Routing_PAG_PF,Klima_PAG_PF
 SG_ EKL_Comp_main_stat : 20|1@1+ (1,0) [0|1] ""  GW_Routing_PAG_PF,Klima_PAG_PF
 SG_ EKL_Comp_ovld_stat : 21|3@1+ (1,0) [0|7] ""  GW_Routing_PAG_PF,Klima_PAG_PF
 SG_ EKL_Comp_Inv_stat : 24|2@1+ (1,0) [0|3] ""  GW_Routing_PAG_PF,Klima_PAG_PF
 SG_ EKL_Comp_photo_temp_stat : 30|2@1+ (1,0) [0|3] ""  GW_Routing_PAG_PF,Klima_PAG_PF
 SG_ EKL_Comp_photo_temp : 32|8@1+ (1,0) [0|254] "Unit_DegreCelsi"  GW_Routing_PAG_PF,Klima_PAG_PF
 SG_ EKL_Comp_current : 40|8@1+ (0.1,0) [0|25.4] "Unit_Amper"  GW_App_PAG_PF,GW_Routing_PAG_PF,Klima_PAG_PF
 SG_ EKL_Comp_rev_stat : 48|8@1+ (50,0) [0|8600] "Unit_MinutInver"  GW_Routing_PAG_PF,Klima_PAG_PF

BO_ 779 Kombi_01: 8 Kombi_PAG_PF
 SG_ KBI_ABS_Lampe : 0|1@1+ (1,0) [0|1] ""  GW_Routing_PAG_PF
 SG_ KBI_ESP_Lampe : 1|1@1+ (1,0) [0|1] ""  GW_Routing_PAG_PF
 SG_ KBI_BKL_Lampe : 2|1@1+ (1,0) [0|1] ""  GW_Routing_PAG_PF
 SG_ KBI_Airbag_Lampe : 3|1@1+ (1,0) [0|1] ""  GW_Routing_PAG_PF
 SG_ KBI_SILA_gueltig : 4|1@1+ (1,0) [0|1] ""  GW_Routing_PAG_PF
 SG_ KBI_Lenkung_Lampe : 5|1@1+ (1,0) [0|1] ""  GW_Routing_PAG_PF
 SG_ KBI_Vorglueh_System_Lampe : 6|1@1+ (1,0) [0|1] ""  GW_Routing_PAG_PF
 SG_ KBI_NV_in_Anzeige : 7|1@1+ (1,0) [0|1] ""  GW_Routing_PAG_PF
 SG_ Kombi_01_BZ : 8|4@1+ (1,0) [0|15] ""  GW_Routing_PAG_PF
 SG_ KBI_Anzeigestatus_ACC : 12|1@1+ (1,0) [0|1] ""  GW_Routing_PAG_PF
 SG_ KBI_Oeldruck_Schalter : 15|1@1+ (1,0) [0|1] ""  GW_Routing_PAG_PF
 SG_ KBI_Tankwarnung : 16|1@1+ (1,0) [0|1] ""  GW_Routing_PAG_PF
 SG_ KBI_MFA_v_Einheit_01 : 17|1@1+ (1,0) [0|1] ""  GW_Routing_PAG_PF,OCU_PAG_PF,RDK_High_PAG_PF
 SG_ KBI_im_Stellgliedtest : 18|1@1+ (1,0) [0|1] ""  GW_Routing_PAG_PF
 SG_ KBI_Anzeigefehler_LDW : 19|2@1+ (1,0) [0|3] ""  GW_Routing_PAG_PF
 SG_ KBI_Variante_USA : 21|1@1+ (1,0) [0|1] ""  GW_Routing_PAG_PF
 SG_ KBI_Oeldruckwarnung : 22|1@1+ (1,0) [0|1] ""  GW_Routing_PAG_PF
 SG_ KBI_Handbremse : 23|1@1+ (1,0) [0|1] ""  GW_Routing_PAG_PF
 SG_ KBI_V_Digital : 24|9@1+ (1,0) [0|511] ""  GW_Routing_PAG_PF,RDK_High_PAG_PF
 SG_ KBI_PLA_in_Anzeige : 33|1@1+ (1,0) [0|1] ""  GW_Routing_PAG_PF
 SG_ KBI_Anzeigefehler_NV : 34|1@1+ (1,0) [0|1] ""  GW_Routing_PAG_PF
 SG_ KBI_angez_Geschw : 48|10@1+ (0.32,0) [0|325.12] "Unit_KiloMeterPerHour"  GW_Routing_PAG_PF
 SG_ KBI_Einheit_Tacho : 58|1@1+ (1,0) [0|1] ""  GW_Routing_PAG_PF,OCU_PAG_PF
 SG_ KBI_Konsistenz_ACC : 59|1@1+ (1,0) [0|1] ""  GW_Routing_PAG_PF
 SG_ KBI_Fehler_Anzeige_ACC : 60|1@1+ (1,0) [0|1] ""  GW_Routing_PAG_PF
 SG_ KBI_Anzeigefehler_SWA : 61|2@1+ (1,0) [0|3] ""  GW_Routing_PAG_PF
 SG_ KBI_KD_Fehler : 63|1@1+ (1,0) [0|1] ""  GW_App_PAG_PF,GW_Routing_PAG_PF

BO_ 1719 Kombi_02: 8 Kombi_PAG_PF
 SG_ KBI_Kilometerstand : 0|20@1+ (1,0) [0|1048573] "Unit_KiloMeter"  GW_App_PAG_PF,GW_Routing_PAG_PF,OCU_PAG_PF
 SG_ KBI_Standzeit : 20|15@1+ (4,0) [0|131068] "Unit_Secon"  GW_Routing_PAG_PF,Klima_PAG_PF
 SG_ KBI_Reset_Standzeit : 35|1@1+ (1,0) [0|1] ""  GW_Routing_PAG_PF
 SG_ KBI_Inhalt_Tank : 40|7@1+ (1,0) [0|126] "Unit_Liter"  GW_Routing_PAG_PF,OCU_PAG_PF
 SG_ KBI_FStatus_Tank : 47|1@1+ (1,0) [0|1] ""  GW_Routing_PAG_PF
 SG_ KBI_Oelwechsel_durchgefuehrt : 54|1@1+ (1,0) [0|1] ""  GW_Routing_PAG_PF
 SG_ KBI_QBit_Aussen_Temp_gef : 55|1@1+ (1,0) [0|1] ""  GW_Routing_PAG_PF
 SG_ KBI_Aussen_Temp_gef : 56|8@1+ (0.5,-50) [-50|75] "Unit_DegreCelsi"  ADR_PAG_X2,GW_App_PAG_PF,GW_Routing_PAG_PF,Klima_PAG_PF,OCU_PAG_PF

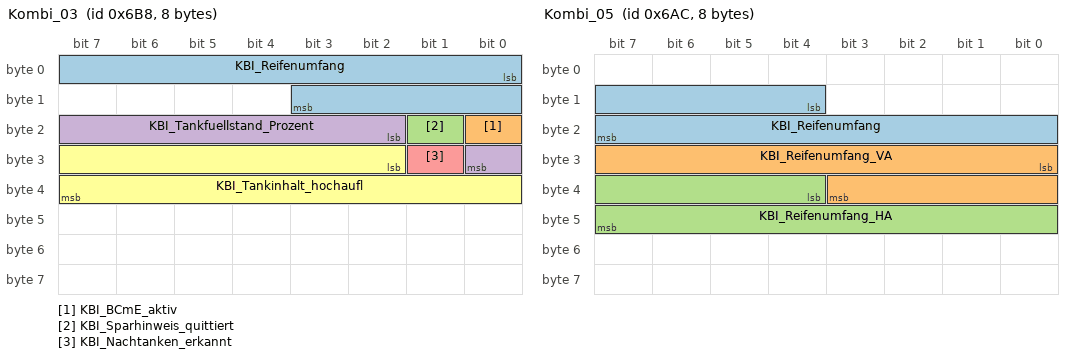
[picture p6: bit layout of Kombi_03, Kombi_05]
BO_ 1720 Kombi_03: 8 Kombi_PAG_PF
 SG_ KBI_Reifenumfang : 0|12@1+ (1,0) [0|4095] "Unit_MilliMeter"  GW_Routing_PAG_PF
 SG_ KBI_BCmE_aktiv : 16|1@1+ (1,0) [0|1] ""  GW_Routing_PAG_PF
 SG_ KBI_Sparhinweis_quittiert : 17|1@1+ (1,0) [0|1] ""  GW_Routing_PAG_PF
 SG_ KBI_Tankfuellstand_Prozent : 18|7@1+ (1,0) [0|100] "Unit_PerCent"  GW_Routing_PAG_PF
 SG_ KBI_Nachtanken_erkannt : 25|1@1+ (1,0) [0|1] ""  GW_Routing_PAG_PF
 SG_ KBI_Tankinhalt_hochaufl : 26|14@1+ (0.01,0) [0|163.81] "Unit_Liter"  GW_Routing_PAG_PF

BO_ 1708 Kombi_05: 8 Kombi_PAG_PF
 SG_ KBI_Reifenumfang : 12|12@1+ (1,0) [0|4095] "Unit_MilliMeter"  GW_Routing_PAG_PF
 SG_ KBI_Reifenumfang_VA : 24|12@1+ (1,0) [0|4095] "Unit_MilliMeter"  GW_Routing_PAG_PF
 SG_ KBI_Reifenumfang_HA : 36|12@1+ (1,0) [0|4095] "Unit_MilliMeter"  GW_Routing_PAG_PF

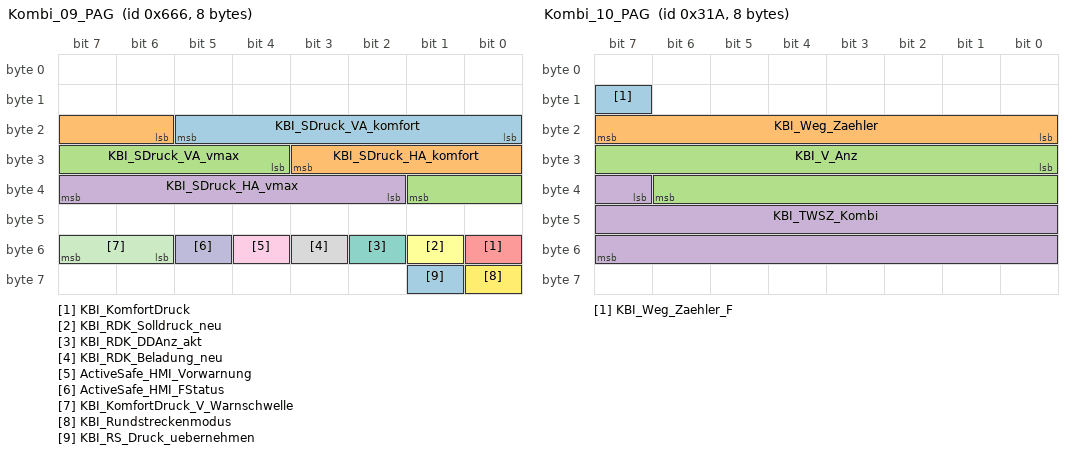
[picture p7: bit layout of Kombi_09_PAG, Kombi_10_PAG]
BO_ 1638 Kombi_09_PAG: 8 ADR_PAG_X2
 SG_ KBI_SDruck_VA_komfort : 16|6@1+ (0.1,0) [0|6.3] "Unit_Bar"  RDK_High_PAG_PF
 SG_ KBI_SDruck_HA_komfort : 22|6@1+ (0.1,0) [0|6.3] ""  RDK_High_PAG_PF
 SG_ KBI_SDruck_VA_vmax : 28|6@1+ (0.1,0) [0|6.3] ""  RDK_High_PAG_PF
 SG_ KBI_SDruck_HA_vmax : 34|6@1+ (0.1,0) [0|6.3] ""  RDK_High_PAG_PF
 SG_ KBI_KomfortDruck : 48|1@1+ (1,0) [0|1] ""  RDK_High_PAG_PF
 SG_ KBI_RDK_Solldruck_neu : 49|1@1+ (1,0) [0|1] ""  RDK_High_PAG_PF
 SG_ KBI_RDK_DDAnz_akt : 50|1@1+ (1,0) [0|1] ""  RDK_High_PAG_PF
 SG_ KBI_RDK_Beladung_neu : 51|1@1+ (1,0) [0|1] ""  RDK_High_PAG_PF
 SG_ ActiveSafe_HMI_Vorwarnung : 52|1@1+ (1,0) [0|1] "" Vector__XXX
 SG_ ActiveSafe_HMI_FStatus : 53|1@1+ (1,0) [0|1] "" Vector__XXX
 SG_ KBI_KomfortDruck_V_Warnschwelle : 54|2@1+ (1,0) [0|3] ""  RDK_High_PAG_PF
 SG_ KBI_Rundstreckenmodus : 56|1@1+ (1,0) [0|1] ""  RDK_High_PAG_PF
 SG_ KBI_RS_Druck_uebernehmen : 57|1@1+ (1,0) [0|1] ""  RDK_High_PAG_PF

BO_ 794 Kombi_10_PAG: 8 Kombi_PAG_PF
 SG_ KBI_Weg_Zaehler_F : 15|1@1+ (1,0) [0|1] "" Vector__XXX
 SG_ KBI_Weg_Zaehler : 16|8@1+ (10,0) [0|2550] "Unit_Meter" Vector__XXX
 SG_ KBI_V_Anz : 24|15@1+ (0.02,0) [0|655.32] "Unit_KiloMeterPerHour"  ADR_PAG_X2
 SG_ KBI_TWSZ_Kombi : 39|17@1+ (0.1,0) [0|9999.9] "Unit_KiloMeter" Vector__XXX

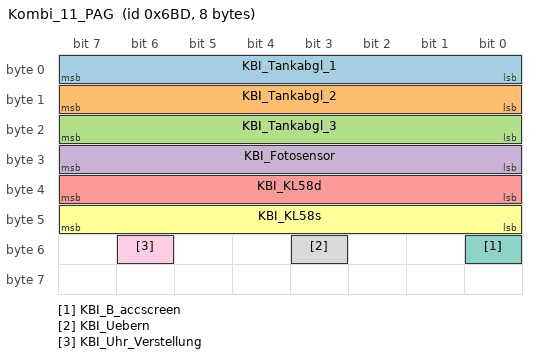
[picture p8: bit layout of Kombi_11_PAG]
BO_ 1725 Kombi_11_PAG: 8 Kombi_PAG_PF
 SG_ KBI_Tankabgl_1 : 0|8@1+ (1,0) [0|255] ""  GW_Routing_PAG_PF
 SG_ KBI_Tankabgl_2 : 8|8@1+ (1,0) [0|255] ""  GW_Routing_PAG_PF
 SG_ KBI_Tankabgl_3 : 16|8@1+ (1,0) [0|255] ""  GW_Routing_PAG_PF
 SG_ KBI_Fotosensor : 24|8@1+ (0.1,0) [0|25.3] "Unit_WattPerMeterSquar"  ADR_PAG_X2,GW_Routing_PAG_PF,Klima_PAG_PF,Miko_PAG_X2
 SG_ KBI_KL58d : 32|8@1+ (0.4,0) [0|100] "Unit_PerCent"  GW_Routing_PAG_PF,Klima_PAG_PF,Miko_PAG_X2
 SG_ KBI_KL58s : 40|8@1+ (1,0) [0|100] "Unit_PerCent"  ADR_PAG_X2,GW_Routing_PAG_PF,Klima_PAG_PF,Miko_PAG_X2
 SG_ KBI_B_accscreen : 48|1@1+ (1,0) [0|1] ""  GW_Routing_PAG_PF
 SG_ KBI_Uebern : 51|1@1+ (1,0) [0|1] ""  GW_App_PAG_PF,GW_Routing_PAG_PF
 SG_ KBI_Uhr_Verstellung : 54|1@1+ (1,0) [0|1] ""  GW_App_PAG_PF,GW_Routing_PAG_PF

CM_ SG_ 1516 FT_FH_Oeffnung "Gibt den Fensteröffnungswert in % an.";
CM_ SG_ 1516 BT_FH_Oeffnung "Gibt den Fensteröffnungswert in % an.";
CM_ SG_ 1516 HL_FH_Oeffnung "Gibt den Fensteröffnungswert in % an.";
CM_ SG_ 1516 HR_FH_Oeffnung "Gibt den Fensteröffnungswert in % an.";
CM_ SG_ 1516 BT_Tuer_geoeffnet "
";
CM_ SG_ 1516 FT_Kisi_li_aktiv "Aktivierungsstatus der Kindersicherung links";
CM_ SG_ 1516 FT_Kisi_Fehler "Fehlerstatus Kindersicherungsfunktion";
CM_ SG_ 1516 F_TSG_FT_01_Mmi "Ungueltige Signale: FT_Tuer_geoeffnet, FT_FH_Oeffnung, FT_verriegelt, FT_Kisi_li_aktiv
";
CM_ SG_ 1516 F_TSG_BT_01_Mmi "Ungueltige Signale: BT_FH_Oeffnung,BT_Tuer_geoeffnet";
CM_ SG_ 1516 F_TSG_HL_01_Mmi "Ungueltige Signale: HL_FH_Oeffnung,HL_Tuer_geoeffnet";
CM_ SG_ 1516 F_TSG_HR_01_Mmi "Ungueltige Signale: HR_FH_Oeffnung,HR_Tuer_geoeffnet";
CM_ SG_ 797 BC_Up_Cursor "Betaetigung Bordcomputer up Taste 
";
CM_ SG_ 797 BC_Down_Cursor "Betaetigung Bordcomputer down Taste ";
CM_ SG_ 797 BC_Set "Bordcomputer Set";
CM_ SG_ 797 BC_Reset "Betaetigung Bordcomputer Reset Taste 
";
CM_ SG_ 797 T_Push_To_Talk "Bedienung Taste 'Push-to-Talk'";
CM_ SG_ 797 ALR_Ist_Proz_Anz "Istsperrgrad der Laengssperre für die Anzeige im Kombiinstrumen";
CM_ SG_ 797 BH_Blinker_li "Blinkerhebel Richtung links
";
CM_ SG_ 797 BH_Blinker_re "Blinkerhebel Richtung rechts
";
CM_ SG_ 797 WH_Intervall "Wischerhebel: Stellung Intervall
";
CM_ SG_ 797 LRH_on_off "Status Lenkradheizung";
CM_ SG_ 797 F_SMLS_01_Mmi "Ungueltige Signale: BC_Down_Cursor, BC_Up_Cursor, BC_Reset,BH_Blinker_li,BH_Blinker_re,WH_Intervall,  LRH_on_off, BC_Set, T_Push_to_Talk

";
CM_ SG_ 797 F_LS_01_Mmi "Ungueltige Signale: LS_Tiptronic_Fehler
";
CM_ SG_ 797 Allrad_01_alt "Veraltet-Bit für das Signal:
ALR_Ist_Proz_Anz";
CM_ SG_ 1092 ZV_FT_offen "gespiegeltes Bit FT_Tuer_geoeffnet TSG_FT_1 Botschaft";
CM_ SG_ 1092 ZV_BT_offen "gespiegeltes Bit BT_Tuer_geoeffnet TSG_BT_1 Botschaft";
CM_ SG_ 1092 ZV_HD_offen "Status Heckdeckel
";
CM_ SG_ 1092 ZV_verriegelt_intern_ist "Istzustand: Verriegelung Fahrzeug innen
";
CM_ SG_ 1092 ZV_verriegelt_extern_ist "Istzustand: Verriegelung Fahrzeug aussen
";
CM_ SG_ 1092 ZV_gesafet_extern_ist "Istzustand: Fahrzeug aussen gesafet
";
CM_ SG_ 1092 KST_Prio_Warn_05 "Kombi Prio Warnung Klemmensteuerung 5";
CM_ SG_ 1092 KST_Prio_Warn_03 "Kombi Prio Warnung";
CM_ SG_ 1092 KST_Prio_Warn_04 "Kombi Prio Warnung ";
CM_ SG_ 1092 KST_Warn_P1_ZST_def "Kombi Prio Warnung Klemmensteuerung 
Zündschloß defekt, Service aufsuchen!";
CM_ SG_ 1092 KST_Warn_P2_ZST_def "Kombi Prio Warnung Klemmensteuerung
Zündschloß defekt!
";
CM_ SG_ 1092 STS_Texte "Nummer des Textes die im Kombi angezeigt werden soll";
CM_ SG_ 1092 F_BCM2_02_Mmi "Ungueltige Signale: KST_Fahrer_Hinweise,KST_Prio_Warn_05,KST_Warn_P1_ZST_def,KST_Warn_P2_ZST_def, ZV_verriegelt_intern_ist,ZV_verriegelt_extern_ist,ZV_gesafet_extern_ist";
CM_ SG_ 1092 F_STS_01_Mmi "Ungueltige Signale: STS_Texte";
CM_ SG_ 1315 SVB_MEM_FS "Sollverbau Sitz Fahrer
";
CM_ SG_ 1315 SVB_MEM_BFS "Sollverbau Sitz Beifahrer
";
CM_ SG_ 1315 SVB_SMLS "Sollverbau Kombilenksaeulenmodul
";
CM_ SG_ 1315 SVB_HDSG "Sollverbau Powerliftgate
";
CM_ SG_ 1315 SVB_Lift "Sollverbau Lift SG
";
CM_ SG_ 1315 SVB_AAG "Sollverbau Anhänger SG
";
CM_ SG_ 1315 SVB_TSG_FT "Sollverbau Tuersteuergeraet Fahrerseite
 ";
CM_ SG_ 1315 SVB_TSG_BT "Sollverbau Tuersteuergeraet Beifahrerseite
";
CM_ SG_ 1315 SVB_RDK "Sollverbau RDK (Reifendruckkontrolle)
";
CM_ SG_ 1315 SVB_BCM1 "Sollverbau BCM vorne
";
CM_ SG_ 1315 SVB_BCM2 "Sollverbau BCM hinten
";
CM_ SG_ 1315 SVB_TSG_HL "Sollverbau Tuersteuergeraet hinten links
";
CM_ SG_ 1315 SVB_TSG_HR "Sollverbau Tuersteuergeraet hinten rechts

";
CM_ SG_ 1315 SVB_VSG "Sollverbau Verdeck SG
";
CM_ SG_ 1315 SVB_Topview "Sollverbau TopView";
CM_ SG_ 1315 SVB_Kombi "Sollverbau Kombiinstrument
";
CM_ SG_ 1315 SVB_BKE "Sollverbau BKE
";
CM_ SG_ 1315 SVB_PDC "Sollverbau Parkassistent (4-Kanal oder 10-Kanal)
";
CM_ SG_ 1315 SVB_STH "Sollverbau Standheizung
";
CM_ SG_ 1315 SVB_RearView "Sollverbau Rückfahrkamera
";
CM_ SG_ 1315 SVB_Stoppuhr "Sollverbau Stoppuhr";
CM_ SG_ 1315 SVB_PCM "Sollverbau Porsche Communication Manager (PCM)
";
CM_ SG_ 1315 SVB_CDR "Sollverbau CD Radio
";
CM_ SG_ 1315 SVB_Kompass "Sollverbau Kompass


";
CM_ SG_ 1315 SVB_ComBox "Sollverbau ComBox
";
CM_ SG_ 1315 SVB_LEH_VA "Sollverbau LEH_VA
";
CM_ SG_ 1315 SVB_Ladegeraet "Sollverbau Ladegerät";
CM_ SG_ 1315 SVB_Motor "Sollverbau Motor SG";
CM_ SG_ 1315 SVB_QSP "Sollverbau Quersperre

";
CM_ SG_ 1315 SVB_Getriebe "Sollverbau Getriebe (PDK oder Wandlerautomat)
";
CM_ SG_ 1315 SVB_WHL "Sollverbau Waehlhebel
";
CM_ SG_ 1315 SVB_Airbag "Sollverbau Airbag
";
CM_ SG_ 1315 SVB_PSM_Ant "Sollverbau PSM
";
CM_ SG_ 1315 SVB_PSM_Fwk "Sollverbau PSM Fahrwerk (Porsche Stability Management)
";
CM_ SG_ 1315 SVB_BMS "Sollverbau Batteriemanagementsystem

";
CM_ SG_ 1315 SVB_LEH "Sollverbau Leistungselektronik

";
CM_ SG_ 1315 SVB_SCR "Sollverbau SCR";
CM_ SG_ 1315 SVB_EPB "Sollverbau Elektrische Parkbremse
";
CM_ SG_ 1315 SVB_SSC "Sollverbau SSC (Sensorcluster)
";
CM_ SG_ 1315 SVB_PDCC "Sollverbau Porsche Dynamic Chassis Control, AAK
";
CM_ SG_ 1315 SVB_LWS "Sollverbau Kombilenksaeulenmodul
";
CM_ SG_ 1315 SVB_PASM_NRA "Sollverbau PASM_Niveauregulierung (Porsche Active Suspension Management)
";
CM_ SG_ 1315 SVB_Allrad "Sollverbau Allrad SG
";
CM_ SG_ 1315 SVB_EPS "Sollverbau EPS

";
CM_ SG_ 1315 SVB_HAL "Sollverbau HAL
";
CM_ SG_ 1315 SVB_EBKV "Sollverbau EBKV";
CM_ SG_ 1315 SVB_AFS "Sollverbau AFS
";
CM_ SG_ 1315 SVB_SWL "Sollverbau Scheinwerfersteuergeraet links
";
CM_ SG_ 1315 SVB_SWR "Sollverbau Scheinwerfersteuergeraet rechts
";
CM_ SG_ 1315 SVB_ACC "Sollverbau Adaptive Cruise Control
";
CM_ SG_ 1315 SVB_SWA "Sollverbau Spurwechselassistent

";
CM_ SG_ 1315 SVB_EHPS "Sollverbau Elektrohydraulische Servolenkung


";
CM_ SG_ 1315 SVB_EKK "Sollverbau elektrischer Klimakompressor



";
CM_ SG_ 1315 SVB_Kamera "Sollverbau Kamerasystem";
CM_ SG_ 1315 SVB_AMP "Sollverbau Verstaerker
";
CM_ SG_ 1315 SVB_TV "Sollverbau TV-Tuner
";
CM_ SG_ 1428 HVLM_Restladezeit_HV_Bat_02 "Zeit, bis HV-Batterie vollständig geladen ist. Angabe in 5 Minuten Schritten. Maximum 42h 25Min";
CM_ SG_ 1428 HVLM_Lademodus_HV_Bat "Gibt den aktuell eingestellten Lademodus an.";
CM_ SG_ 1428 HVLM_Bat_laden_aktiv "Anzeige ob die HV-Batterie geladen wird.";
CM_ SG_ 1428 HVLM_Ladeart "Anzeige, ob Strom in das Fzg. fließt und wofür er verwendet wird.";
CM_ SG_ 1428 HVLM_VK_Anf "Anforderung des Konditionierungsmanagers (im Lademanager) zur Aktivierung der Vorkonditionierung Innenraum";
CM_ SG_ 1428 HVLM_Ladesystemhinweise "Anzeigen von Hinweisen zum Ladesystem.
Anzeigen, dass das Ladesystem defekt ist.";
CM_ SG_ 1428 HVLM_Stecker_Status "Status der Steckererkennung unabhängig vom Lademodus (AC oder DC)";
CM_ SG_ 1428 HVLM_Langzeit_Laden "Anforderung den Ladezustand der HV-Batterie bis langen Standzeiten zu reduzieren";
CM_ SG_ 1428 HVLM_Klima_Temp "MLBevo: Gewünschte Innenraumtemperatur, auf die bei der Standklimatisierung geregelt werden soll.
MQB: Temperatur die vom Nutzer vorgewählt wurde (VW: low=15,5 °C/ high=30,0°C)";
CM_ BO_ 1397 "nur für PAG - Mobile Online Dienste";
CM_ SG_ 1397 HVLM_Status_Timer_MUX "Multiplexor zur Anzeige des aktuell übertragenden Timer-Status (0x1-0x3) und Wecktimer (0x7)";
CM_ SG_ 1397 HVLM_Status_Timer_1_Jahr "Status Timer 1 gesetztes Datum -> Jahr";
CM_ SG_ 1397 HVLM_Status_Timer_2_Jahr "Status Timer 2 gesetztes Datum -> Jahr";
CM_ SG_ 1397 HVLM_Status_Timer_3_Jahr "Status Timer 3 gesetztes Datum -> Jahr";
CM_ SG_ 1397 HVLM_Status_Timer_4_Jahr "Status Timer 4 gesetztes Datum -> Jahr";
CM_ SG_ 1397 HVLM_Status_Timer_7_Jahr "Status Timer 7 gesetztes Datum -> Jahr";
CM_ SG_ 1397 HVLM_Status_Timer_1_Minute "Status Timer 1 gesetztes Datum -> Minute";
CM_ SG_ 1397 HVLM_Status_Timer_2_Minute "Status Timer 2 gesetztes Datum -> Minute";
CM_ SG_ 1397 HVLM_Status_Timer_3_Minute "Status Timer 3 gesetztes Datum -> Minute";
CM_ SG_ 1397 HVLM_Status_Timer_4_Minute "Status Timer 4 gesetztes Datum -> Minute";
CM_ SG_ 1397 HVLM_Status_Timer_7_Minute "Status Timer 7 gesetztes Datum -> Minute";
CM_ SG_ 1397 HVLM_Status_Timer_1_Monat "Status Timer 1 gesetztes Datum -> Monat";
CM_ SG_ 1397 HVLM_Status_Timer_2_Monat "Status Timer 2 gesetztes Datum -> Monat";
CM_ SG_ 1397 HVLM_Status_Timer_3_Monat "Status Timer 3 gesetztes Datum -> Monat";
CM_ SG_ 1397 HVLM_Status_Timer_4_Monat "Status Timer 4 gesetztes Datum -> Monat";
CM_ SG_ 1397 HVLM_Status_Timer_7_Monat "Status Timer 7 gesetztes Datum -> Monat";
CM_ SG_ 1397 HVLM_Status_Timer_1_Stunde "Status Timer 1 gesetztes Datum -> Stunde";
CM_ SG_ 1397 HVLM_Status_Timer_2_Stunde "Status Timer 2 gesetztes Datum -> Stunde";
CM_ SG_ 1397 HVLM_Status_Timer_3_Stunde "Status Timer 3 gesetztes Datum -> Stunde";
CM_ SG_ 1397 HVLM_Status_Timer_4_Stunde "Status Timer 4 gesetztes Datum -> Stunde";
CM_ SG_ 1397 HVLM_Status_Timer_7_Stunde "Status Timer 7 gesetztes Datum -> Stunde";
CM_ SG_ 1397 HVLM_Status_Timer_1_Tag "Status Timer 1 gesetztes Datum -> Tag";
CM_ SG_ 1397 HVLM_Status_Timer_2_Tag "Status Timer 2 gesetztes Datum -> Tag";
CM_ SG_ 1397 HVLM_Status_Timer_3_Tag "Status Timer 3 gesetztes Datum -> Tag";
CM_ SG_ 1397 HVLM_Status_Timer_4_Tag "Status Timer 4 gesetztes Datum -> Tag";
CM_ SG_ 1397 HVLM_Status_Timer_7_Tag "Status Timer 1 gesetztes Datum -> Tag";
CM_ SG_ 1397 HVLM_Status_Timer_1_Laden "Status des Ladetimers 1";
CM_ SG_ 1397 HVLM_Status_Timer_2_Laden "Status des Ladetimers 2";
CM_ SG_ 1397 HVLM_Status_Timer_3_Laden "Status des Ladetimers 3";
CM_ SG_ 1397 HVLM_Status_Timer_4_Laden "Status des Ladetimers 4";
CM_ SG_ 1397 HVLM_Status_Timer_1_Vorklima "Status des Vorklimatisierungs-Timers 1";
CM_ SG_ 1397 HVLM_Status_Timer_2_Vorklima "Status des Vorklimatisierungs-Timers 2";
CM_ SG_ 1397 HVLM_Status_Timer_3_Vorklima "Status des Vorklimatisierungs-Timers 3";
CM_ SG_ 1397 HVLM_Status_Timer_4_Vorklima "Status des Vorklimatisierungs-Timers 4";
CM_ SG_ 1397 HVLM_Status_Timer_1_Zyklus_Mo "Timer 1 für Wochentag gesetzt";
CM_ SG_ 1397 HVLM_Status_Timer_2_Zyklus_Mo "Timer 2 für Wochentag gesetzt";
CM_ SG_ 1397 HVLM_Status_Timer_3_Zyklus_Mo "Timer 3 für Wochentag gesetzt";
CM_ SG_ 1397 HVLM_Status_Timer_4_Zyklus_Mo "Timer 4 für Wochentag gesetzt";
CM_ SG_ 1397 HVLM_Status_Timer_1_Zyklus_Di "Timer 1 für Wochentag gesetzt";
CM_ SG_ 1397 HVLM_Status_Timer_2_Zyklus_Di "Timer 2 für Wochentag gesetzt";
CM_ SG_ 1397 HVLM_Status_Timer_3_Zyklus_Di "Timer 3 für Wochentag gesetzt";
CM_ SG_ 1397 HVLM_Status_Timer_4_Zyklus_Di "Timer 4 für Wochentag gesetzt";
CM_ SG_ 1397 HVLM_Status_Timer_1_Zyklus_Mi "Timer 1 für Wochentag gesetzt";
CM_ SG_ 1397 HVLM_Status_Timer_2_Zyklus_Mi "Timer 2 für Wochentag gesetzt";
CM_ SG_ 1397 HVLM_Status_Timer_3_Zyklus_Mi "Timer 3 für Wochentag gesetzt";
CM_ SG_ 1397 HVLM_Status_Timer_4_Zyklus_Mi "Timer 4 für Wochentag gesetzt";
CM_ SG_ 1397 HVLM_Status_Timer_1_Zyklus_Do "Timer 1 für Wochentag gesetzt";
CM_ SG_ 1397 HVLM_Status_Timer_2_Zyklus_Do "Timer 2 für Wochentag gesetzt";
CM_ SG_ 1397 HVLM_Status_Timer_3_Zyklus_Do "Timer 3 für Wochentag gesetzt";
CM_ SG_ 1397 HVLM_Status_Timer_4_Zyklus_Do "Timer 4 für Wochentag gesetzt";
CM_ SG_ 1397 HVLM_Status_Timer_1_Zyklus_Fr "Timer 1 für Wochentag gesetzt";
CM_ SG_ 1397 HVLM_Status_Timer_2_Zyklus_Fr "Timer 2 für Wochentag gesetzt";
CM_ SG_ 1397 HVLM_Status_Timer_3_Zyklus_Fr "Timer 3 für Wochentag gesetzt";
CM_ SG_ 1397 HVLM_Status_Timer_4_Zyklus_Fr "Timer 4 für Wochentag gesetzt";
CM_ SG_ 1397 HVLM_Status_Timer_1_Zyklus_Sa "Timer 1 für Wochentag gesetzt";
CM_ SG_ 1397 HVLM_Status_Timer_2_Zyklus_Sa "Timer 2 für Wochentag gesetzt";
CM_ SG_ 1397 HVLM_Status_Timer_3_Zyklus_Sa "Timer 3 für Wochentag gesetzt";
CM_ SG_ 1397 HVLM_Status_Timer_4_Zyklus_Sa "Timer 4 für Wochentag gesetzt";
CM_ SG_ 1397 HVLM_Status_Timer_1_Zyklus_So "Timer 1 für Wochentag gesetzt";
CM_ SG_ 1397 HVLM_Status_Timer_2_Zyklus_So "Timer 2 für Wochentag gesetzt";
CM_ SG_ 1397 HVLM_Status_Timer_3_Zyklus_So "Timer 3 für Wochentag gesetzt";
CM_ SG_ 1397 HVLM_Status_Timer_4_Zyklus_So "Timer 4 für Wochentag gesetzt";
CM_ SG_ 1397 HVLM_Status_Timer_1_Zyklus_WH "Timer 1 ist zur einmaligen Auslösung gestezt oder wiederholt sich";
CM_ SG_ 1397 HVLM_Status_Timer_2_Zyklus_WH "Timer 2 ist zur einmaligen Auslösung gestezt oder wiederholt sich";
CM_ SG_ 1397 HVLM_Status_Timer_3_Zyklus_WH "Timer 3 ist zur einmaligen Auslösung gestezt oder wiederholt sich";
CM_ SG_ 1397 HVLM_Status_Timer_4_Zyklus_WH "Timer 4 ist zur einmaligen Auslösung gestezt oder wiederholt sich";
CM_ SG_ 1397 HVLM_Status_Nachtstrom_X_Std_Anf "Anfangszeit für Setzen der Nachtstromtabelle im Profil X - gibt die volle halbe Stunde an
(Aktuell zu setzendes Profil wird im Signal HVLM_Status_Nachtstrom_Profil angezeigt)";
CM_ SG_ 1397 HVLM_Status_Nachtstrom_Prof "Zusammenfassung Zeitraum 1..3 zu einem Profil für Setzen der Nachtstromtabelle";
CM_ SG_ 1397 HVLM_Status_Nachtstrom_X_Std_End "Endezeit für Setzen der Nachtstromtabelle im Profil X - gibt die volle halbe Stunde an
(Aktuell zu setzendes Profil wird im Signal HVLM_Status_Nachtstrom_Profil angezeigt)";
CM_ SG_ 1397 HVLM_Status_Nachtstrom_Akt_Prof "Status: aktuell eingestelltes Nachtstrom-Profil";
CM_ SG_ 1397 HVLM_Status_Laden "aktueller Status des Ladevorgangs";
CM_ SG_ 1424 KY_Funkschl_Nr "Funkschlüsselnummer gültig für die Fahrerberechtigung
";
CM_ SG_ 1424 KY_ID_Geb_autorisiert "Authorisierung Schluessel (ID-Geber)
";
CM_ SG_ 1424 KY_ID_Geb_steckt "Schluessel (ID-Geber) im Zuendschloss
";
CM_ SG_ 1424 KY_FFB_Frequenz "Frequenz FFB
";
CM_ SG_ 1424 KY_HF_Aktiv "HF Funkempfang
";
CM_ SG_ 1424 KY_LF_Aktiv "LF Schluesselkommunikation
";
CM_ SG_ 1424 KY_ELV_verr "Verriegelungsstatus ELV

";
CM_ SG_ 1424 KY_ELV_entr "Entriegelungsstatus ELV
";
CM_ SG_ 1424 KY_ELV_enable_Anforderung "Anforderung ELV-Freigabe
";
CM_ SG_ 1424 KY_Valet_Parking "Erkennung Schluessel für Valet Parking
";
CM_ SG_ 1424 KY_Keyless_Verbau "Verbauinfo Keyless 
";
CM_ SG_ 1424 KY_FBS_Fahrer_Hinweise "Kombi Fahrer Hinweise FBS
Audi/VW
0x01 Bitte Lenkung entlasten";
CM_ SG_ 1424 FBS_Warn_Lenkung_def "Kombi Prio Warnung Lenkung defekt
'Fahrzeug abstellen, Lenkung defekt!'
";
CM_ SG_ 1424 FBS_Warn_LenkVerriegelung_def "Kombi Prio Warnung Lenkungsverriegelung defekt
'Lenkungsverriegelung, Werkstatt aufsuchen!'";
CM_ SG_ 1424 FBS_Warn_Schluessel_Batt "Kombi Prio Warnung Schluessel Batterie
'Bitte Schlüsselbatterie wechseln!'";
CM_ SG_ 1424 FBS_Prio_Warn_04 "Kombi Prio Warnung FBS 4";
CM_ SG_ 1424 FBS_Prio_Warn_05 "Kombi Prio Warnung FBS 5";
CM_ SG_ 1424 KY_KYL_Fahrer_Hinweise "Kombi Fahrer Hinweise Keyless
Audi/VW
0x04 Kein Schlüssel erkannt";
CM_ SG_ 1424 KYL_Warn_kein_Schluessel "Kombi Prio Warnung Keyless 
'Schlüssel nicht im Fahrzeug!'
";
CM_ SG_ 1424 KYL_Warn_Kessy_defekt "Kombi Prio Warnung Keyless
'Keyless Go defekt, Zündschloß benutzen'";
CM_ SG_ 1424 KY_KYL_Prio_Warn_03 "Kombi Prio Warnung Keyless 3";
CM_ SG_ 1424 KY_KYL_Prio_Warn_04 "Kombi Prio Warnung Keyless 4";
CM_ SG_ 1424 KY_KYL_Prio_Warn_05 "Kombi Prio Warnung Keyless 5";
CM_ SG_ 1424 KY_Schluessel_Soll "Sollwert der zu lernenden Schluessel";
CM_ SG_ 1424 KY_Schluessel_Ist "Istwert der gelernten Schluessel";
CM_ SG_ 1424 KY_WFS_Safe "Status WFS
";
CM_ SG_ 1424 KY_WFS_LZ "Anforderung aus Lastenheft WFS V
";
CM_ SG_ 1424 KY_StartStopp_Info "Stopp-Freigabe und Start-Anforderung an den Start-Stopp-Koordinator";
CM_ SG_ 1424 KYL_Notzuendschloss "Kessy mit Notzuendschloss verbaut
";
CM_ SG_ 1424 KYL_Warn_Notzuendschloss "Aufforderung an den Benutzer, den Schlüsssel an die Notspule zu halten, wenn Kessy den Schlüssel nicht finden kann
'Keyless Go defekt. Zum Starten den Schlüssel vor das Symbol halten!'";
CM_ SG_ 1424 FBS_KD_Fehler "Kundendienstfehlerspeicher FBS
";
CM_ SG_ 1424 SK_Anf_DTC_Abfrage "Anforderung des Service Key Master an den Datensammler Fehlerspeicherteinträge aus den SG's zu lesen
Für die ersten 10 Botschaften nach CAN-Wakeup muss der Initwert gesendet werden. Grund: Flankenerkennung durch den Datensammler

GW führt bei Flankenwe";
CM_ SG_ 1424 SK_Anf_DTC_Abfrage_sofort "Anforderung des Service Key Master an den Datensammler Fehlerspeicherteinträge aus den SG's zu lesen.
Bei dieser Anforderung wird eine positive Authentifikationsrunde des Komponentenschutz durchgeführt. Eine gerade aktive KS Runde wird abgebrochen. Nach ";
CM_ BO_ 960 "B8/D4/C7";
CM_ SG_ 960 Klemmen_Status_01_CHK "Berechnung siehe Lastenheft 'Kommunikationsabsicherung für FlexRay und CAN'
Endwerte siehe 'Kommunikationsabsicherung für FlexRay und CAN / Anhang C: Tabelle S-PDU Kennungen'";
CM_ SG_ 960 Klemmen_Status_01_BZ "4bit Botschaftszaehler; wird in jeder Sendebotschaft inkrementiert";
CM_ SG_ 960 ZV_verriegelt_extern_soll_02 "Sollzustand: Verriegelung Fahrzeug aussen

_02 für senden in der Klemmenstatusbotschaft
";
CM_ SG_ 960 ZAS_Kl_S "Klemme S: S-Kontakt (Schluessel steckt)
";
CM_ SG_ 960 ZAS_Kl_15 "Klemme 15: Zuendung (SW-Kl.15)
";
CM_ SG_ 960 ZAS_Kl_X "Klemme 75
";
CM_ SG_ 960 ZAS_Kl_50 "Klemme 50: Startwunsch Fahrer
";
CM_ SG_ 959 KL_Drehz_Anh "Drehzahlanhebung vom Motor angefordert

";
CM_ SG_ 959 KL_Vorwarn_Komp_ein "Vorwarnung Kompressor ein; 140ms vorher; Information für Motor zum Aufbau Momentenreserve";
CM_ SG_ 959 KL_Handshake_BEM "Handshake Klima / BEM (Heizleistungsänderung)
";
CM_ SG_ 959 KL_Komp_Moment_alt "Veraltet-Bit für Kompressor-Moment
";
CM_ SG_ 959 KL_Vorwarn_HHS_ein "Vorwarnung Heckscheibenheizung ein; Information für Motor zum Aufbau Momentenreserve";
CM_ SG_ 959 KL_Vorwarn_HFS_ein "Vorwarnung Frontscheibenheizung ein (Info für Motor zum Aufbau Momentenreserve), aktuell keine HFS für B8 geplant
";
CM_ SG_ 959 KL_Vorwarn_Zuheizer_ein "Vorwarnung Zuheizerbetrieb
";
CM_ SG_ 959 KL_KD_Fehler "Status Kundendienstfehlerspeichereinträge

";
CM_ SG_ 959 KL_Comp_rev_rq "Requested compressor revolution
over 8600 rpm = compressor stop";
CM_ SG_ 959 KL_Charisma_FahrPr "Aktuelles Fahrprogramm des Charisma-Teilnehmers
";
CM_ SG_ 959 KL_Charisma_Status "Charisma Systemstatus des Charisma-Teilnehmers

Wert 0x3 ist nur für Fahrzeuge ab MQB relevant";
CM_ SG_ 959 KL_Charisma_Umschaltung "Erkennung  Umschaltaufforderung des Charisma-Teilnehmers";
CM_ SG_ 959 KL_Last_Kompr "Aktuelles Verlustmoment der Klimaanlage bezogen auf die Kurbelwelle. Wird der Klimakompressor nicht angesteuert, ist das Schleppmoment bezogen auf die Kurbelwelle zu senden.";
CM_ SG_ 959 KL_Leistung_Hzg_Soll "Ansteuerung intelligentes 1600 W PTC oder Schnellheizung

Nur für D4 relevant
";
CM_ SG_ 959 KL_Anf_KL "Anforderung Kühlerlüfter der Klimaanlage in Prozent

";
CM_ SG_ 959 KL_4_Zonen "Vorhalt für D4:
Information, ob 4-Zonen-Klimaanlage verbaut

";
CM_ SG_ 959 KL_AC_Schalter "AC Schalter
";
CM_ SG_ 959 KL_Zustand "Betrieb Klimaanlage
";
CM_ SG_ 959 KL_Thermomanagement "Stufen des Thermomanagements";
CM_ SG_ 959 KL_Comp_enable "Enable to start for compressor
After 1 second when High-voltage becomes available, turn on '1'";
CM_ SG_ 959 KL_StartStopp_Info "Stopp-Freigabe und Start-Anforderung an den Start-Stopp-Koordinator";
CM_ SG_ 959 KL_el_Zuheizer_Stufe "Vorgabe für Motorsteuergeraet PTC-Stufe; im MLB-B8 und MQB nur Stufe 0...3

";
CM_ SG_ 959 KL_Diag_Absperrvent "Das Klimabedienteil führt eine elektrische Diagnose des  EUVs durch, durch das das Heizungsabsperrventil angesteuert wird. Es übermittelt das Ergebnis an das MSG (Standard-4Bit-Status, nicht alle Zustände müssen genutzt werden; so sind z.B. die Out of Ran";
CM_ SG_ 1636 KL_Stromsparmodus "Stromsparmodus (durch BEM)
";
CM_ SG_ 1636 KL_Spg_Hzg_aus "Anforderung: Spiegelheizung ausschalten
";
CM_ SG_ 1636 KL_AQS_Empfindlichkeit "Vorgabe der Empfinglichkeitsstufe für AQS
";
CM_ SG_ 1636 KL_SIH_Soll_li "Einstellung Sitzheizung Fahrer (0...6)";
CM_ SG_ 1636 KL_SIH_Takt_li "Ein-Aus Taktung Sitzheizung Fahrer";
CM_ SG_ 1636 KL_SIL_Soll_li "Einstellung Sitzlüftung Fahrer (0...6)";
CM_ SG_ 1636 KL_LRH_aus "Heizleistungsfreigabe für Lenkradheizung";
CM_ SG_ 1636 KL_SIH_Soll_re "Einstellung Sitzheizung Beifahrer (0...6)";
CM_ SG_ 1636 KL_SIH_Takt_re "Ein-Aus Taktung Sitzheizung Beifahrer
";
CM_ SG_ 1636 KL_SIL_Soll_re "Einstellung Sitzlüftung Beifahrer (0...6)";
CM_ SG_ 1636 KL_Beschlagsgefahr "Beschlagsgefahr auf der Frontscheibe im Bereich des Spiegelfusses. Dient zur präventiven Ansteuerung der  Kamera-Scheibenheizung, um Kamera-Blindheit zu vermeiden
PHEV: volle Leistungsfreigabe 
HV Heizer und HV EKK bei Scheibenbeschlag ";
CM_ SG_ 1636 KL_HSH_ein_Soll "Fahrerwunsch (Anforderung) Heckscheibenheizung
";
CM_ SG_ 1636 KL_HSH_Taktung "Ein-Aus Taktung der Heckscheibenheizung ";
CM_ SG_ 1636 KL_Zuheizer_Freigabe "Freigabe Zuheizer
";
CM_ SG_ 1636 KL_ZHE_Status "Status elektrischer Zuheizer
";
CM_ SG_ 1636 KL_FSH_Status "Status Frontscheibenheizung
";
CM_ SG_ 1636 KL_LRH_on_off "Das Signal soll den Kundenwunsch zur Aktivierung / Deaktivierung der Lenkradheizung übertragen.

Derzeit nur bei VW verwendet";
CM_ SG_ 1636 KL_Umluftklappe_Status "Status Umluftklappe

";
CM_ SG_ 1636 KL_Geblaese_Status "Status Geblaese









";
CM_ SG_ 1636 KL_I_Geblaese "Stromaufnahme Gebläse";
CM_ SG_ 1636 KL_Kompressorstrom_soll "Sollvorgabe Klima-Kompressorstrom
";
CM_ SG_ 1636 KL_FSH_P_Soll "Sollleistung Frontscheibenheizung";
CM_ SG_ 1646 KL_STL_aktiv "Betriebsstatus Standlueftung
";
CM_ SG_ 1646 KL_STH_aktiv "Betriebsstatus Standheizung
";
CM_ SG_ 1646 KL_Solarluefter_aktiv "Betriebsstatus Solarluefter
";
CM_ SG_ 1646 KL_Umluft_Taste "Betaetigung Umlufttaste
";
CM_ SG_ 1646 KL_Geblaese_Fond_Status "Status Geblaese









";
CM_ SG_ 1646 KL_STH_Ansteuerung "Ansteuerung STH

";
CM_ SG_ 1646 KL_STH_Betriebsdauer "Betriebsdauer STH";
CM_ SG_ 1646 KL_Magnetventil "Anforderung des Bypassventils.";
CM_ SG_ 1646 KL_WaPu "Ansteuerung der Standheizungswasserpumpe";
CM_ SG_ 1646 KL_Freigabe_KRH_li "Freigabe Kopfraumheizung links
(0 wird gesendet bei Motor aus und während des Lastabwurfes, die Stufen 1-3 werden gesendet, wenn KRH-Stufen angefordert werden und das dynamische Energiemanagement genügend Leistung bereitstellt)";
CM_ SG_ 1646 KL_Freigabe_KRH_re "Freigabe Kopfraumheizung rechts
(0 wird gesendet bei Motor aus und während des Lastabwurfes, die Stufen 1-3 werden gesendet, wenn KRH-Stufen angefordert werden und das dynamische Energiemanagement genügend Leistung bereitstellt)";
CM_ SG_ 1646 KL_BCmE_Livetip_Freigabe "Status der Klimaanlage. 
Zeigt an, ob der Livetip 'Fenster schließen wegen Ineffizienz Klimaanlage' sinvollerweise angezeigt werden soll

MQB: nur Audi relevant";
CM_ SG_ 1646 KL_HYB_ASV_hinten_schliessen_Anf "Anforderung der Klima an das BMS, das Absperrventil des Kältemittelkreislaufs zur Batteriekühlung zu schliessen";
CM_ SG_ 1646 KL_HYB_ASV_vorne_schliessen_Anf "Anforderung der Klima an das BMS, das Absperrventil des Kältemittelkreislaufs der Klimaanlage zu schliessen";
CM_ SG_ 1646 KL_HYB_Spuelbetrieb_Freigabe "Status der Klimaanlage. Zeigt dem BMS an, ob der Spülbetrieb möglich ist";
CM_ SG_ 1646 KL_Fehler_ElWaPu "Bei der Diagnose der Heizungspumpe wurde ein Fehler festgestellt.";
CM_ SG_ 1646 KL_Innen_Temp "Innentemperatur

";
CM_ SG_ 1646 KL_Sonnenintensitaet "gemittelte eingestrahlte Leistung in W/m2";
CM_ SG_ 1646 KL_AussenTemp_WK "Aussentemperatur (Vorhalt VW, Nicht im Audi B8/D4/C7)
";
CM_ SG_ 1655 KL_T_PSM_off "PSM-Off Taster (Anforderung ESP passiv schalten)
";
CM_ SG_ 1655 KL_T_HSpoiler "Heckspoiler Taste in der BKE
";
CM_ SG_ 1655 KL_T_PASM_1 "PASM Taste, Dämpfereinstellung 'Normal'";
CM_ SG_ 1655 KL_T_PASM_2 "PASM Taste, Dämpfereinstellung 'Komfort'
";
CM_ SG_ 1655 KL_T_FSH "Nur E2: Frontscheibenheizung";
CM_ SG_ 1655 KL_T_ZV "Taster Zentralverriegelung";
CM_ SG_ 1655 KL_T_Abgasklappe "Taster Sportabgasklappenanlage
";
CM_ SG_ 1655 KL_T_Rollo_kurz "Taster Heckrollo öffnen/schliessen
";
CM_ SG_ 1655 KL_T_Rollo_lang "Taster Heckrollo+Seitenrollo öffnen/schließen
";
CM_ SG_ 1655 KL_T_STH "Taster Standheizung (Wasserzusatzheizung)
";
CM_ SG_ 1655 KL_Sportmodus "Wird nur im G1 befüllt.

";
CM_ SG_ 1655 KL_T_TC_off "Übermittlung Tasterzustand ESC / TC Off (nur Rennsport)
";
CM_ SG_ 1655 KL_T_LeVerstFond "Beifaherersitz Lehnenverstellung (aus dem Fondbereich) 'vor'
";
CM_ SG_ 1655 KL_T_SitzLVerstFond "Beifahrersitz Sitzlaengsverstellung (aus dem Fondbereich)
";
CM_ SG_ 1655 KL_Charisma_Anzeige "Steuerung der Anzeigetexte für Sport, Sport Chrono und Offroad";
CM_ SG_ 1655 KL_Charisma_Anzeige_Umschaltung "Steuerung der Anzeigetexte für Sport, Sport Chrono und Offroad
Umschaltung der Anzeigentabelle in KL_Charisma_Anzeige (siehe Spezifikation PAG-SportChrono)";
CM_ SG_ 1655 KL_Segeln_Anf_deaktivieren "Anforderung das Segeln zu deaktvieren";
CM_ SG_ 1655 KL_T_HDC "Nur E2: Taster HDC (Bergabfahrassistent) ";
CM_ SG_ 1655 HYB_Anf_E_Mode "Zustand des E-Mode Tasters bei Hybrid-Fhz. Es wird der entprellte Betätigungszustand übertragen (betätigt/ nicht betätigt). Die Umwandlung des Tastersignals in ein statisches Schaltersignal erfolgt im MSG.";
CM_ SG_ 1655 FSM_Status "Statusbit Fahrwerkschaltermodul";
CM_ SG_ 1655 KL_Niv_up "Taste für Aufregeln; Verstellung Fahrwerk nach oben
";
CM_ SG_ 1655 KL_Niv_down "Taste für Abregeln; Verstellung Fahrwerk nach unten ";
CM_ SG_ 1655 KL_T_PASM_3 "PASM Taste, Dämpfereinstellung 'Sport' 
";
CM_ SG_ 1655 KL_T_VD "zum Verdeck öffnen oder schließen";
CM_ SG_ 1655 KL_T_Windschott "zum Windschott öffnen oder schließen";
CM_ SG_ 1655 KL_St_Atemp "Status Aussentemperatursensor erfolgt durch elektrische Diagnose des Sensors (OBD1-Prüfung), Übergabe an die DME zur Fehlerplausibilisierung
";
CM_ SG_ 1655 Statusbit_Offroad_aktiv "Anzeige im PAG Kombi 'Geschwindigkeit zu hoch -> Offorad deaktiviert'";
CM_ SG_ 1655 KL_T_StSt_deaktiv "Taster Start/Stopp (Taster aus: Start/Stopp aktiviert, Taster ein: Start/Stopp deaktiviert)
";
CM_ SG_ 1655 KL_T_LDW "Status Taster Lane Departure Warning
";
CM_ SG_ 1655 KL_Atemp_ungef "Aussentemp. ungefiltert (Achtung bei Übernehme SG: der Initialwert der BKE unterscheidet sich vom BCM1-Signal)
";
CM_ SG_ 1656 Schalter_MD1Vorne_Vorwahl_3 "  | Mit Drehschalter:       | Ohne Drehschalter:
  | Schiebeausstelldach MD1 | Schiebeausstelldach MD1   | MD3
-------------------------------------------------------------------------
0 | zu                      | nicht_betaetigt           | nicht_bet";
CM_ SG_ 1656 DK_T_Multi_1 "In Abhängigkeit der Fahrzeugfunktion belegbares Tastensignal.
PAG 918s - Deckelöffnung";
CM_ SG_ 1656 DK_F_T_Multi_1 "Fehler Tastensignal ('Tasterklemmer')";
CM_ BO_ 895 "Verwendung nur im 918";
CM_ SG_ 895 KL_AC_LED_an "Status AC";
CM_ SG_ 895 KL_ACmax_LED_an "Status Acmax";
CM_ SG_ 895 KL_LVT_O_LED_an "Status Luftverteilung oben";
CM_ SG_ 895 KL_LVT_M_LED_an "Status Luftverteilung Mitte";
CM_ SG_ 895 KL_LVT_U_LED_an "Status Luftverteilung unten";
CM_ SG_ 895 KL_Umluft_LED_an "Status Umluft-Funktion";
CM_ SG_ 895 KL_Auto_LED_an "Status Auto LED";
CM_ SG_ 1483 KL_WunschStrom_HV "Von Klima gewünschter HV-Strom, der dann nach Freigabe des HV-eEM auf HV-EKK und HV-PTC aufgeteilt wird";
CM_ SG_ 1483 KL_BattKond_WaPu_DZMax "Maximal-Drehzahl der Wasserpumpe im Batteriekühlkreislauf als Vorgabe für BMS";
CM_ SG_ 1483 KBT_Defrost_aktiv "Defrostmodus im KBT aktiv";
CM_ SG_ 1483 KL_T_Charge "Signal für Tastenbetätigung Charge-Taste (SOC Increasing)";
CM_ SG_ 1483 KL_Standklima_Status "Info, dass Standklimatisierung nicht gestartet werden konnte oder abgebrochen wurde.";
CM_ SG_ 1483 PTC_Wasserauslasstemp "Gemessene Wasserauslasstemperatur";
CM_ SG_ 1483 PTC_Wassereinlasstemp "Gemessene Wassereinlasstemperatur";
CM_ SG_ 1483 PTC_HV_I_ist "PTC Stromverbrauch (max. 120A)";
CM_ SG_ 1532 KL_Autobetrieb_HL "Status, ob Klimatisierung in Autobetrieb in Klimazone hinten links";
CM_ SG_ 1532 KL_Autobetrieb_HR "Status, ob Klimatisierung in Autobetrieb in Klimazone hinten rechts";
CM_ SG_ 1532 KL_Autobetrieb_VL "Status, ob Klimatisierung in Autobetrieb in Klimazone vorne links";
CM_ SG_ 1532 KL_Autobetrieb_VR "Status, ob Klimatisierung in Autobetrieb in Klimazone vorne rechts";
CM_ SG_ 1532 KL_Zieltemperatur_HL "einzuregelnde (d.h. die interne berechnete, nicht die an der BKE eingestellte) Zieltemperatur für die Klimazone hinten links";
CM_ SG_ 1532 KL_Zieltemperatur_HR "einzuregelnde (d.h. die interne berechnete, nicht die an der BKE eingestellte) Zieltemperatur für die Klimazone hinten rechts";
CM_ SG_ 1532 KL_Zieltemperatur_VL "einzuregelnde (d.h. die interne berechnete, nicht die an der BKE eingestellte) Zieltemperatur für die Klimazone vorne links";
CM_ SG_ 1532 KL_Zieltemperatur_VR "einzuregelnde (d.h. die interne berechnete, nicht die an der BKE eingestellte) Zieltemperatur für die Klimazone vorne rechts";
CM_ BO_ 1712 "D4 und B8-PA

1:1 LIN-CAN Botschaft, nur bei Kl.15 EIN gesendet";
CM_ SG_ 1712 FS_ResponseError "siehe LIN2.0-Specification
(Darf nicht über ein Fehlergueltigkeitsbit abgesichtert werden!)";
CM_ SG_ 1625 EKL_KD_Fehler "Bei gesetztem Bit ist mindestens ein Kundendienstfehler eingetragen";
CM_ SG_ 1625 EKL_Comp_SCI_com_stat "'00' normal
'x1' CAN_error (abnormal)
'1x' Inverter_error";
CM_ SG_ 1625 EKL_Comp_output_stat "Diagnosis series 1 'Output'
'0' normal
'1' output line short
'2' output line cut out
'3' abnormal current detection";
CM_ SG_ 1625 EKL_Comp_main_stat "Real compressor status not CAN board status";
CM_ SG_ 1625 EKL_Comp_ovld_stat "Diagnosis series 1 'Over load'
0 normal
1 voltage restriction
2 current restriction
3 software over current
4 over load
6 over input current";
CM_ SG_ 1625 EKL_Comp_Inv_stat "Diagnosis series 2 'Startability'
'0' normal
'1' start fail
'2' temperature protection
'3' system abnormal stop";
CM_ SG_ 1625 EKL_Comp_photo_temp_stat "Diagnosis series 2 'Inverter temp.'
'0' normal
'1' over heat L
'2' over heat S
'3' sermister abnormal";
CM_ SG_ 1625 EKL_Comp_photo_temp "IGBT temp. measured by inverter.
Photo coupler temp. is not  measured in compressor temp. of IGBT (same as EK1_Comp_Inv_temp) will be sent";
CM_ SG_ 1625 EKL_Comp_current "Compressor input current";
CM_ SG_ 1625 EKL_Comp_rev_stat "compressor real revolution
0-8624 rpm is outputted
'output = (actual speed + 25) / 50'   speed over 8625rpm: '172'";
CM_ BO_ 779 "MLB";
CM_ SG_ 779 KBI_ABS_Lampe "ABS-Sicherheits-Lampe wurde eingeschaltet.";
CM_ SG_ 779 KBI_ESP_Lampe "ESP-Sicherheits-Lampe wurde eingeschaltet ";
CM_ SG_ 779 KBI_BKL_Lampe "Sicherheits-Lampe Bremskontrolle wurde eingeschaltet;
";
CM_ SG_ 779 KBI_Airbag_Lampe "Airbag Sicherheits-Lampe wurde eingeschaltet ";
CM_ SG_ 779 KBI_SILA_gueltig "Rückmeldeinformation (Bit 1-6) ist gültig";
CM_ SG_ 779 KBI_Lenkung_Lampe "Sicherheits-Lampe der Lenkung (Lenkhilfe EPS, Audi-Dynamic-Steering ...) wurde eingeschaltet.

0x0 = Lenkungs-Lampe aus
0x1 = Lenkungs-Lampe ein";
CM_ SG_ 779 KBI_Vorglueh_System_Lampe "Rückmeldung der Vorglühlampe bzw. Motor Systemlampe (MO_Systemlampe) an den Motor (bei Diesel und Otto!). Hardwaremässig gleiche LED im Kombi (EPC- oder Glühwendel), Unterscheidung nur über Ziffernblatt.";
CM_ SG_ 779 KBI_NV_in_Anzeige "Das Bit gibt dem NV die Information, ob NV-Bild im Kombi in der Anzeige ist. (Information ist notwendig um Kontrasverstellungen nur dann zuzulassen, wenn der Fahrer das Feedback über das  Kombidisplay bekommt.)";
CM_ SG_ 779 KBI_Anzeigestatus_ACC "Status der ACC-Anzeige im nicht permanenten Displaybereich";
CM_ SG_ 779 KBI_Oeldruck_Schalter "Das Signal bildet den Status des Öldrucks über den am Kombi angeschlossenen Öldruckschalter ab.";
CM_ SG_ 779 KBI_Tankwarnung "Fahrer wird gewarnt, dass er den Reservebereich erreicht hat. Fzg.spezifische Warnschwelle";
CM_ SG_ 779 KBI_MFA_v_Einheit_01 "Einheit der Geschwindigkeit, die vom Fahrer im Car-Menü gewählt wurde. Veränderliche Grösse, im Gegensatz zur Einheit des Tachokranzes.";
CM_ SG_ 779 KBI_im_Stellgliedtest "Kombi im Stellgliedtest, Signal muss eingelesen werden, um Fehlfunktion aufgrund der Bewegung der Stellglieder (Drehzahlmesser, Tacho) des Kombis zu verhindern";
CM_ SG_ 779 KBI_Variante_USA "In diesem Signal wird die HW-Variante des Kombis ausgegeben, ACC plausibilisiert auf dieses Signal hin seine US-Codierung";
CM_ SG_ 779 KBI_Oeldruckwarnung "Öldruckwarnung im Kombi aktiv";
CM_ SG_ 779 KBI_Handbremse "Handbremsen-Information vom Kombi.
Das Signal bezieht sich ausschließlich auf den Zustand der konventionellen Handbremse.";
CM_ SG_ 779 KBI_V_Digital "Ausgabe der im Kombi angezeigten digitalen Geschwindigkeit.

Einheit ist im KBI_MFA_v_Einheit_01 definiert";
CM_ SG_ 779 KBI_PLA_in_Anzeige "Das Signal wird als aktive Rückmeldung genutzt, ob die Info des PLA im Kombi angezeigt wird. Wenn nach Anforderung des Displays das Signal zweimal auf 0 ist, wird der Parkvorgang abgebrochen.
Ein Kombi, dass PLA Anzeige nicht unterstützt, schickt dauerha";
CM_ SG_ 779 KBI_Anzeigefehler_NV "Über dieses Signal teilt das Kombiinstrument dem Nightvision-Steuergerät mit, dass ein Fehler vom Kombiinstrument diagnostiziert wurde, der zur Abschaltung der Nightvision-Funktion führen muss.";
CM_ SG_ 779 KBI_angez_Geschw "Im Tacho angezeigte Geschwindigkeit inklusive der Voreilung

";
CM_ SG_ 779 KBI_Einheit_Tacho "Information, ob es sich um Meilen- oder Kmh-Kombi handelt, Einheit des Tachos entspricht dem Zifferblatt, Grösse ist nicht veränderlich";
CM_ SG_ 779 KBI_Konsistenz_ACC "Rückmeldung an ACC, dass die Botschaften zur Ansteuerung von Anzeigen nicht bzw. nicht konsistent empfangen wurden (Timeout-, BZ-, CHK- und DLC-Fehler)                                                                                                        ";
CM_ SG_ 779 KBI_Fehler_Anzeige_ACC "Rückmeldung an ACC, dass mindestens eine der ACC-relevanten Anzeigen -rote Fahrerübernahme, Mitteldisplay, Gong - fehlerhaft sind.";
CM_ SG_ 779 KBI_Anzeigefehler_SWA "Signal bezieht sich nur auf die SWA-Lampe, Vorhalt für Kombis mit SWA-Lampe. ";
CM_ BO_ 1719 "MLB";
CM_ SG_ 1719 KBI_Kilometerstand "Fehler wird ausgegeben, falls Kilometerstand nicht restaurierbar
";
CM_ SG_ 1719 KBI_Standzeit "Low Byte 4, High Byte 5;
Standzeit in 4 Sekunden Auflösung; mit diesen 15 Bits läßt sich eine Zeit bis 36 Stunden, 24 Minuten und 28 Sekunden darstellen; 
Der Standzeitzähler wird mit KL15_Aus gestartet, er bleibt 2 Minuten vor einem Überlauf stehen, di";
CM_ SG_ 1719 KBI_Inhalt_Tank "Restmenge 2 bzw. 2,5l nicht auflösbar

0x7F = Fehler

";
CM_ SG_ 1719 KBI_FStatus_Tank "Signal wird gesetzt:

a) Während der Fehlerentprellzeit (20 s Entprellung)

b) Bei erkanntem Fehler wird der Tankinhalt während der laufenden KL15-Phase über den 
    Verbrauch zurückgerechnet. In dieser Zeit ist das Bit ebenfalls gesetzt. Nach einem";
CM_ SG_ 1719 KBI_Oelwechsel_durchgefuehrt "Nach einen Ölwechsel (Service) ist die Ethanol Warmfahrwarnung zu unterdrücken.";
CM_ SG_ 1719 KBI_QBit_Aussen_Temp_gef "0x0 = gültiger Wert
0x1 = Ersatz-, Init- oder Fehlerwert";
CM_ SG_ 1720 KBI_Reifenumfang "Mittlerer Radumfang aus der K-Zahl gerechnet in Millimeter.  Byte 2 Bit 5,4 reserviert, Byte 2 Bit 3..0 und Byte 1 Bit 7..0; Wertebereich 0..4096 mm
";
CM_ SG_ 1720 KBI_BCmE_aktiv "Anzeige BCmE aktiv (BCmE-Screen oder Einsparhinweis in der Anzeige)";
CM_ SG_ 1720 KBI_Sparhinweis_quittiert "angezeigter Sparhinweis ist quittiert. Signal wird nach zwei Sendebotschaften wieder auf '0' gesetzt.";
CM_ SG_ 1720 KBI_Tankfuellstand_Prozent "Tankfüllstand in %";
CM_ SG_ 1720 KBI_Nachtanken_erkannt "Statusinformation Nachtankmodus";
CM_ SG_ 1720 KBI_Tankinhalt_hochaufl "angezeigter Tankinhalt hochauflösend zur Restreichweitenberechnung";
CM_ SG_ 1708 KBI_Reifenumfang "Mittlerer Radumfang aus der K-Zahl gerechnet in Millimeter.  Byte 2 Bit 5,4 reserviert, Byte 2 Bit 3..0 und Byte 1 Bit 7..0; Wertebereich 0..4096 mm
";
CM_ SG_ 1708 KBI_Reifenumfang_VA "Reifenumfang Vorderachse
";
CM_ SG_ 1708 KBI_Reifenumfang_HA "Reifenumfang Hinterachse
";
CM_ SG_ 1638 KBI_SDruck_VA_komfort "Solldruck (Komfort) Vorderachse Kombi
";
CM_ SG_ 1638 KBI_SDruck_HA_komfort "Solldruck (Komfort) Hinterachse Kombi
";
CM_ SG_ 1638 KBI_SDruck_VA_vmax "Solldruck (vmax) Vorderachse Kombi
";
CM_ SG_ 1638 KBI_SDruck_HA_vmax "Solldruck (vmax) Hinterachse Kombi
";
CM_ SG_ 1638 KBI_KomfortDruck "Komfortdruck ausgewählt
";
CM_ SG_ 1638 KBI_RDK_Solldruck_neu "RDK Solldruck neu
";
CM_ SG_ 1638 KBI_RDK_DDAnz_akt "Differenzdruckanzeige
";
CM_ SG_ 1638 KBI_RDK_Beladung_neu "RDK Beladung neu
";
CM_ SG_ 1638 ActiveSafe_HMI_Vorwarnung "Über das Signal wird dem ACC-SG die HMI-Einstellung 'Vorwarnung ActiveSafe_Stufe2 ein- oder ausgeschaltet' mitgeteilt.";
CM_ SG_ 1638 ActiveSafe_HMI_FStatus "Über das Signal wird dem ACC-SG die HMI-Einstellung ActiveSafe_Stufe2 mitgeteilt.";
CM_ SG_ 1638 KBI_KomfortDruck_V_Warnschwelle "Sendeinformation V (km/h) Warnschwelle";
CM_ SG_ 1638 KBI_Rundstreckenmodus "Rundstreckenmodus aktiv";
CM_ SG_ 1638 KBI_RS_Druck_uebernehmen "Druck für Rundstreckenmodus übernehmen";
CM_ SG_ 794 KBI_Weg_Zaehler_F "Fehlerbit für den Inkrementalzähler Weg
";
CM_ SG_ 794 KBI_Weg_Zaehler "Inkrementaler Zähler des Kombis
";
CM_ SG_ 794 KBI_V_Anz "Angezeigte Geschwindigkeit
";
CM_ SG_ 794 KBI_TWSZ_Kombi "Tageswegstreckenzähler Kombi
";
CM_ SG_ 1725 KBI_Tankabgl_1 "Tankabgleichswert Kombi (Geber 1)
";
CM_ SG_ 1725 KBI_Tankabgl_2 "Tankabgleichswert Kombi (Geber 2)
";
CM_ SG_ 1725 KBI_Tankabgl_3 "Tankabgleichswert Kombi (Geber 3)
";
CM_ SG_ 1725 KBI_Fotosensor "Sonnenintensität Kombi";
CM_ SG_ 1725 KBI_KL58d "Kombi-Display-Dimmung
";
CM_ SG_ 1725 KBI_KL58s "Auffindbeleuchtung 
Jede Änderung löst OnChange Versand aus!
";
CM_ SG_ 1725 KBI_B_accscreen "ACC_Screen im Kombi aktivieren/deaktivieren
";
CM_ SG_ 1725 KBI_Uebern "Zeit im Gateway übernehmen
";
CM_ SG_ 1725 KBI_Uhr_Verstellung "Eine Uhrzeitverstellung im Kombi erfordert eine sofortige Übernahme der Zeit im Gateway (ausserhalb der Synchronisation beim Übergang von 29 nach 30 Sek.) ";
BA_DEF_ BO_  "DiagRequest" ENUM  "No","Yes";
BA_DEF_ BO_  "DiagResponse" ENUM  "No","Yes";
BA_DEF_ BO_  "DiagState" ENUM  "No","Yes";
BA_DEF_ BO_  "GenMsgChkConstant" HEX 0 4095;
BA_DEF_ BO_  "GenMsgCycleTime" INT 0 65535;
BA_DEF_ BO_  "GenMsgCycleTimeFast" INT 0 65535;
BA_DEF_ BO_  "GenMsgDelayTime" INT 0 100000;
BA_DEF_ BO_  "GenMsgILSupport" ENUM  "No","Yes";
BA_DEF_ BO_  "GenMsgNrOfRepetition" INT 0 100;
BA_DEF_ BO_  "GenMsgPDUConstants" STRING ;
BA_DEF_ BO_  "GenMsgSendType" ENUM  "Cyclic","not_used","not_used","not_used","not_used","not_used","not_used","IfActive","NoMsgSendType";
BA_DEF_ BO_  "GenMsgStartDelayTime" INT 0 100000;
BA_DEF_ BO_  "NmMessage" ENUM  "No","Yes";
BA_DEF_ BO_  "NmhMessage" ENUM  "No","Yes";
BA_DEF_ BO_  "MsgType" ENUM  "Application","NM ","NMH","TP2.0","ISO-TP ","BAP","EID";
BA_DEF_ BO_  "VAGTP20_API" HEX 0 255;
BA_DEF_ BO_  "VAGTP20_DynConnection" ENUM  "No","Yes";
BA_DEF_ BO_  "VAGTP20_DynSetup" ENUM  "No","Yes";
BA_DEF_ BO_  "VAGTP20_StatConnection" ENUM  "No","Yes";
BA_DEF_ SG_  "GenSigActiveRepetitions" INT -2147483648 2147483647;
BA_DEF_ SG_  "GenSigInactiveValue" INT -2147483648 2147483647;
BA_DEF_ SG_  "GenSigSendType" ENUM  "Cyclic","OnWrite","OnWriteWithRepetition","OnChange","OnChangeWithRepetition","IfActive","IfActiveWithRepetition","NoSigSendType","OnChangeAndIfActive","OnChangeAndIfActiveWithRepetition";
BA_DEF_ SG_  "GenSigStartValue" INT -2147483648 2147483647;
BA_DEF_ SG_  "NWM-WakeupAllowed" ENUM  "No","Yes";
BA_DEF_ SG_  "GenSigFuncType" ENUM  "NoFunction","MsgCounter","CRC-8","XOR","XOR-2","DatedBit","SW-Kl15","CHK","Constant","Protocol","CRC-8-SAE_J1850";
BA_DEF_ SG_  "GenSigSwitchedByIgnition" ENUM  "No","Yes";
BA_DEF_ SG_  "Fehlerwert" HEX 0 2147483647;
BA_DEF_ SG_  "GenSigMissingSourceValue" HEX 0 2147483647;
BA_DEF_REL_ BU_SG_REL_  "GenSigTimeoutTime" INT 0 65535;
BA_DEF_DEF_REL_ "GenSigTimeoutTime" 0;
BA_DEF_DEF_  "DiagRequest" "No";
BA_DEF_DEF_  "DiagResponse" "No";
BA_DEF_DEF_  "DiagState" "No";
BA_DEF_DEF_  "GenMsgChkConstant" 0;
BA_DEF_DEF_  "GenMsgCycleTime" 0;
BA_DEF_DEF_  "GenMsgCycleTimeFast" 0;
BA_DEF_DEF_  "GenMsgDelayTime" 0;
BA_DEF_DEF_  "GenMsgILSupport" "No";
BA_DEF_DEF_  "GenMsgNrOfRepetition" 0;
BA_DEF_DEF_  "GenMsgPDUConstants" "";
BA_DEF_DEF_  "GenMsgSendType" "NoMsgSendType";
BA_DEF_DEF_  "GenMsgStartDelayTime" 0;
BA_DEF_DEF_  "NmMessage" "No";
BA_DEF_DEF_  "NmhMessage" "No";
BA_DEF_DEF_  "MsgType" "Application";
BA_DEF_DEF_  "VAGTP20_API" 0;
BA_DEF_DEF_  "VAGTP20_DynConnection" "No";
BA_DEF_DEF_  "VAGTP20_DynSetup" "No";
BA_DEF_DEF_  "VAGTP20_StatConnection" "No";
BA_DEF_DEF_  "GenSigActiveRepetitions" 0;
BA_DEF_DEF_  "GenSigInactiveValue" 0;
BA_DEF_DEF_  "GenSigSendType" "NoSigSendType";
BA_DEF_DEF_  "GenSigStartValue" 0;
BA_DEF_DEF_  "NWM-WakeupAllowed" "No";
BA_DEF_DEF_  "GenSigFuncType" "NoFunction";
BA_DEF_DEF_  "GenSigSwitchedByIgnition" "Yes";
BA_DEF_DEF_  "Fehlerwert" 0;
BA_DEF_DEF_  "GenSigMissingSourceValue" 0;
BA_ "GenMsgSendType" BO_ 1516 0;
BA_ "GenMsgILSupport" BO_ 1516 1;
BA_ "GenMsgDelayTime" BO_ 1516 50;
BA_ "GenMsgCycleTime" BO_ 1516 500;
BA_ "GenMsgSendType" BO_ 797 0;
BA_ "GenMsgILSupport" BO_ 797 1;
BA_ "GenMsgDelayTime" BO_ 797 10;
BA_ "GenMsgCycleTime" BO_ 797 50;
BA_ "GenMsgSendType" BO_ 1092 0;
BA_ "GenMsgILSupport" BO_ 1092 1;
BA_ "GenMsgDelayTime" BO_ 1092 10;
BA_ "GenMsgCycleTime" BO_ 1092 50;
BA_ "GenMsgSendType" BO_ 1315 0;
BA_ "GenMsgILSupport" BO_ 1315 1;
BA_ "GenMsgCycleTime" BO_ 1315 250;
BA_ "GenMsgSendType" BO_ 1428 0;
BA_ "GenMsgILSupport" BO_ 1428 1;
BA_ "GenMsgDelayTime" BO_ 1428 50;
BA_ "GenMsgCycleTime" BO_ 1428 500;
BA_ "GenMsgSendType" BO_ 1397 0;
BA_ "GenMsgILSupport" BO_ 1397 1;
BA_ "GenMsgCycleTime" BO_ 1397 800;
BA_ "MsgType" BO_ 1895 4;
BA_ "DiagRequest" BO_ 1895 1;
BA_ "MsgType" BO_ 2001 4;
BA_ "DiagResponse" BO_ 2001 1;
BA_ "MsgType" BO_ 1792 4;
BA_ "DiagState" BO_ 1792 1;
BA_ "MsgType" BO_ 1907 4;
BA_ "DiagRequest" BO_ 1907 1;
BA_ "MsgType" BO_ 2013 4;
BA_ "DiagResponse" BO_ 2013 1;
BA_ "MsgType" BO_ 1862 4;
BA_ "DiagRequest" BO_ 1862 1;
BA_ "MsgType" BO_ 1968 4;
BA_ "DiagResponse" BO_ 1968 1;
BA_ "MsgType" BO_ 1817 4;
BA_ "DiagRequest" BO_ 1817 1;
BA_ "MsgType" BO_ 1923 4;
BA_ "DiagResponse" BO_ 1923 1;
BA_ "MsgType" BO_ 1812 4;
BA_ "DiagRequest" BO_ 1812 1;
BA_ "MsgType" BO_ 1918 4;
BA_ "DiagResponse" BO_ 1918 1;
BA_ "MsgType" BO_ 1846 4;
BA_ "DiagRequest" BO_ 1846 1;
BA_ "MsgType" BO_ 1952 4;
BA_ "DiagResponse" BO_ 1952 1;
BA_ "MsgType" BO_ 1803 4;
BA_ "DiagRequest" BO_ 1803 1;
BA_ "MsgType" BO_ 1909 4;
BA_ "DiagResponse" BO_ 1909 1;
BA_ "GenMsgSendType" BO_ 1424 0;
BA_ "GenMsgILSupport" BO_ 1424 1;
BA_ "GenMsgDelayTime" BO_ 1424 50;
BA_ "GenMsgCycleTime" BO_ 1424 200;
BA_ "GenMsgSendType" BO_ 960 0;
BA_ "GenMsgILSupport" BO_ 960 1;
BA_ "GenMsgDelayTime" BO_ 960 10;
BA_ "GenMsgCycleTime" BO_ 960 100;
BA_ "GenMsgChkConstant" BO_ 960 195;
BA_ "GenMsgSendType" BO_ 959 0;
BA_ "GenMsgILSupport" BO_ 959 1;
BA_ "GenMsgCycleTime" BO_ 959 100;
BA_ "GenMsgSendType" BO_ 1636 0;
BA_ "GenMsgILSupport" BO_ 1636 1;
BA_ "GenMsgDelayTime" BO_ 1636 50;
BA_ "GenMsgCycleTime" BO_ 1636 500;
BA_ "GenMsgSendType" BO_ 1646 0;
BA_ "GenMsgILSupport" BO_ 1646 1;
BA_ "GenMsgDelayTime" BO_ 1646 200;
BA_ "GenMsgCycleTime" BO_ 1646 2000;
BA_ "GenMsgSendType" BO_ 1655 0;
BA_ "GenMsgNrOfRepetition" BO_ 1655 3;
BA_ "GenMsgILSupport" BO_ 1655 1;
BA_ "GenMsgDelayTime" BO_ 1655 50;
BA_ "GenMsgCycleTimeFast" BO_ 1655 100;
BA_ "GenMsgCycleTime" BO_ 1655 500;
BA_ "GenMsgSendType" BO_ 1656 0;
BA_ "GenMsgNrOfRepetition" BO_ 1656 3;
BA_ "GenMsgILSupport" BO_ 1656 1;
BA_ "GenMsgDelayTime" BO_ 1656 50;
BA_ "GenMsgCycleTimeFast" BO_ 1656 100;
BA_ "GenMsgCycleTime" BO_ 1656 500;
BA_ "GenMsgSendType" BO_ 895 0;
BA_ "GenMsgILSupport" BO_ 895 1;
BA_ "GenMsgCycleTime" BO_ 895 100;
BA_ "GenMsgSendType" BO_ 1483 0;
BA_ "GenMsgILSupport" BO_ 1483 1;
BA_ "GenMsgDelayTime" BO_ 1483 100;
BA_ "GenMsgCycleTime" BO_ 1483 500;
BA_ "GenMsgSendType" BO_ 1532 0;
BA_ "GenMsgILSupport" BO_ 1532 1;
BA_ "GenMsgCycleTime" BO_ 1532 500;
BA_ "GenMsgSendType" BO_ 1712 0;
BA_ "GenMsgILSupport" BO_ 1712 1;
BA_ "GenMsgCycleTime" BO_ 1712 500;
BA_ "GenMsgSendType" BO_ 1625 0;
BA_ "GenMsgILSupport" BO_ 1625 1;
BA_ "GenMsgCycleTime" BO_ 1625 500;
BA_ "GenMsgSendType" BO_ 779 0;
BA_ "GenMsgILSupport" BO_ 779 1;
BA_ "GenMsgCycleTime" BO_ 779 50;
BA_ "GenMsgSendType" BO_ 1719 0;
BA_ "GenMsgILSupport" BO_ 1719 1;
BA_ "GenMsgCycleTime" BO_ 1719 1000;
BA_ "GenMsgSendType" BO_ 1720 0;
BA_ "GenMsgILSupport" BO_ 1720 1;
BA_ "GenMsgCycleTime" BO_ 1720 1000;
BA_ "GenMsgSendType" BO_ 1708 0;
BA_ "GenMsgILSupport" BO_ 1708 1;
BA_ "GenMsgCycleTime" BO_ 1708 1000;
BA_ "GenMsgSendType" BO_ 1638 0;
BA_ "GenMsgILSupport" BO_ 1638 1;
BA_ "GenMsgDelayTime" BO_ 1638 100;
BA_ "GenMsgCycleTime" BO_ 1638 1000;
BA_ "GenMsgSendType" BO_ 794 0;
BA_ "GenMsgILSupport" BO_ 794 1;
BA_ "GenMsgCycleTime" BO_ 794 100;
BA_ "GenMsgSendType" BO_ 1725 0;
BA_ "GenMsgILSupport" BO_ 1725 1;
BA_ "GenMsgDelayTime" BO_ 1725 50;
BA_ "GenMsgCycleTime" BO_ 1725 500;
BA_ "GenSigSwitchedByIgnition" SG_ 1516 FT_FH_Oeffnung 0;
BA_ "GenSigSendType" SG_ 1516 FT_FH_Oeffnung 3;
BA_ "GenSigSwitchedByIgnition" SG_ 1516 BT_FH_Oeffnung 0;
BA_ "GenSigSendType" SG_ 1516 BT_FH_Oeffnung 3;
BA_ "GenSigSendType" SG_ 1516 HL_FH_Oeffnung 3;
BA_ "GenSigSendType" SG_ 1516 HR_FH_Oeffnung 3;
BA_ "GenSigSwitchedByIgnition" SG_ 1516 FT_Tuer_geoeffnet 0;
BA_ "GenSigSendType" SG_ 1516 FT_Tuer_geoeffnet 3;
BA_ "GenSigSwitchedByIgnition" SG_ 1516 BT_Tuer_geoeffnet 0;
BA_ "GenSigSendType" SG_ 1516 BT_Tuer_geoeffnet 3;
BA_ "GenSigSendType" SG_ 1516 HL_Tuer_geoeffnet 3;
BA_ "GenSigSendType" SG_ 1516 HR_Tuer_geoeffnet 3;
BA_ "GenSigSwitchedByIgnition" SG_ 1516 FT_verriegelt 0;
BA_ "GenSigSendType" SG_ 1516 FT_verriegelt 3;
BA_ "GenSigSwitchedByIgnition" SG_ 1516 FT_Kisi_li_aktiv 0;
BA_ "GenSigSendType" SG_ 1516 FT_Kisi_li_aktiv 3;
BA_ "GenSigSwitchedByIgnition" SG_ 1516 FT_Kisi_Fehler 0;
BA_ "GenSigSendType" SG_ 1516 FT_Kisi_Fehler 3;
BA_ "GenSigSwitchedByIgnition" SG_ 1516 F_TSG_FT_01_Mmi 0;
BA_ "GenSigStartValue" SG_ 1516 F_TSG_FT_01_Mmi 1;
BA_ "GenSigSendType" SG_ 1516 F_TSG_FT_01_Mmi 0;
BA_ "GenSigSwitchedByIgnition" SG_ 1516 F_TSG_BT_01_Mmi 0;
BA_ "GenSigStartValue" SG_ 1516 F_TSG_BT_01_Mmi 1;
BA_ "GenSigSendType" SG_ 1516 F_TSG_BT_01_Mmi 0;
BA_ "GenSigStartValue" SG_ 1516 F_TSG_HL_01_Mmi 1;
BA_ "GenSigSendType" SG_ 1516 F_TSG_HL_01_Mmi 0;
BA_ "GenSigStartValue" SG_ 1516 F_TSG_HR_01_Mmi 1;
BA_ "GenSigSendType" SG_ 1516 F_TSG_HR_01_Mmi 0;
BA_ "GenSigSwitchedByIgnition" SG_ 797 BC_Up_Cursor 0;
BA_ "GenSigSendType" SG_ 797 BC_Up_Cursor 3;
BA_ "GenSigSwitchedByIgnition" SG_ 797 BC_Down_Cursor 0;
BA_ "GenSigSendType" SG_ 797 BC_Down_Cursor 3;
BA_ "GenSigSendType" SG_ 797 BC_Set 3;
BA_ "GenSigSwitchedByIgnition" SG_ 797 BC_Reset 0;
BA_ "GenSigSendType" SG_ 797 BC_Reset 3;
BA_ "GenSigSwitchedByIgnition" SG_ 797 T_Push_To_Talk 0;
BA_ "GenSigSendType" SG_ 797 T_Push_To_Talk 3;
BA_ "Fehlerwert" SG_ 797 ALR_Ist_Proz_Anz 255;
BA_ "GenSigStartValue" SG_ 797 ALR_Ist_Proz_Anz 254;
BA_ "GenSigSendType" SG_ 797 ALR_Ist_Proz_Anz 0;
BA_ "GenSigSwitchedByIgnition" SG_ 797 BH_Blinker_li 0;
BA_ "GenSigSendType" SG_ 797 BH_Blinker_li 3;
BA_ "GenSigSwitchedByIgnition" SG_ 797 BH_Blinker_re 0;
BA_ "GenSigSendType" SG_ 797 BH_Blinker_re 3;
BA_ "GenSigSwitchedByIgnition" SG_ 797 WH_Intervall 0;
BA_ "GenSigSendType" SG_ 797 WH_Intervall 3;
BA_ "GenSigSwitchedByIgnition" SG_ 797 LRH_on_off 0;
BA_ "GenSigSendType" SG_ 797 LRH_on_off 3;
BA_ "GenSigSendType" SG_ 797 LS_Tiptronic_Fehler 3;
BA_ "GenSigSwitchedByIgnition" SG_ 797 F_SMLS_01_Mmi 0;
BA_ "GenSigStartValue" SG_ 797 F_SMLS_01_Mmi 1;
BA_ "GenSigSendType" SG_ 797 F_SMLS_01_Mmi 0;
BA_ "GenSigSwitchedByIgnition" SG_ 797 F_LS_01_Mmi 0;
BA_ "GenSigStartValue" SG_ 797 F_LS_01_Mmi 1;
BA_ "GenSigSendType" SG_ 797 F_LS_01_Mmi 0;
BA_ "GenSigFuncType" SG_ 797 Allrad_01_alt 5;
BA_ "GenSigStartValue" SG_ 797 Allrad_01_alt 1;
BA_ "GenSigSendType" SG_ 797 Allrad_01_alt 0;
BA_ "GenSigSwitchedByIgnition" SG_ 1092 ZV_FT_offen 0;
BA_ "GenSigSendType" SG_ 1092 ZV_FT_offen 3;
BA_ "GenSigSwitchedByIgnition" SG_ 1092 ZV_BT_offen 0;
BA_ "GenSigSendType" SG_ 1092 ZV_BT_offen 3;
BA_ "GenSigSwitchedByIgnition" SG_ 1092 ZV_HD_offen 0;
BA_ "GenSigSendType" SG_ 1092 ZV_HD_offen 3;
BA_ "GenSigSwitchedByIgnition" SG_ 1092 ZV_verriegelt_intern_ist 0;
BA_ "GenSigSendType" SG_ 1092 ZV_verriegelt_intern_ist 3;
BA_ "GenSigSwitchedByIgnition" SG_ 1092 ZV_verriegelt_extern_ist 0;
BA_ "GenSigSendType" SG_ 1092 ZV_verriegelt_extern_ist 3;
BA_ "GenSigSwitchedByIgnition" SG_ 1092 ZV_gesafet_extern_ist 0;
BA_ "GenSigSendType" SG_ 1092 ZV_gesafet_extern_ist 3;
BA_ "GenSigSwitchedByIgnition" SG_ 1092 KST_Prio_Warn_05 0;
BA_ "GenSigSendType" SG_ 1092 KST_Prio_Warn_05 3;
BA_ "GenSigSwitchedByIgnition" SG_ 1092 KST_Prio_Warn_03 0;
BA_ "GenSigSendType" SG_ 1092 KST_Prio_Warn_03 3;
BA_ "GenSigSwitchedByIgnition" SG_ 1092 KST_Prio_Warn_04 0;
BA_ "GenSigSendType" SG_ 1092 KST_Prio_Warn_04 3;
BA_ "GenSigSwitchedByIgnition" SG_ 1092 KST_Warn_P1_ZST_def 0;
BA_ "GenSigSendType" SG_ 1092 KST_Warn_P1_ZST_def 3;
BA_ "GenSigSwitchedByIgnition" SG_ 1092 KST_Warn_P2_ZST_def 0;
BA_ "GenSigSendType" SG_ 1092 KST_Warn_P2_ZST_def 3;
BA_ "Fehlerwert" SG_ 1092 STS_Texte 15;
BA_ "GenSigSwitchedByIgnition" SG_ 1092 STS_Texte 0;
BA_ "GenSigStartValue" SG_ 1092 STS_Texte 14;
BA_ "GenSigSendType" SG_ 1092 STS_Texte 0;
BA_ "GenSigSwitchedByIgnition" SG_ 1092 F_BCM2_02_Mmi 0;
BA_ "GenSigStartValue" SG_ 1092 F_BCM2_02_Mmi 1;
BA_ "GenSigSendType" SG_ 1092 F_BCM2_02_Mmi 0;
BA_ "GenSigSwitchedByIgnition" SG_ 1092 F_STS_01_Mmi 0;
BA_ "GenSigStartValue" SG_ 1092 F_STS_01_Mmi 1;
BA_ "GenSigSendType" SG_ 1092 F_STS_01_Mmi 0;
BA_ "GenSigSwitchedByIgnition" SG_ 1315 SVB_MEM_FS 0;
BA_ "GenSigSendType" SG_ 1315 SVB_MEM_FS 0;
BA_ "GenSigSwitchedByIgnition" SG_ 1315 SVB_MEM_BFS 0;
BA_ "GenSigSendType" SG_ 1315 SVB_MEM_BFS 0;
BA_ "GenSigSwitchedByIgnition" SG_ 1315 SVB_SMLS 0;
BA_ "GenSigSendType" SG_ 1315 SVB_SMLS 0;
BA_ "GenSigSwitchedByIgnition" SG_ 1315 SVB_HDSG 0;
BA_ "GenSigSendType" SG_ 1315 SVB_HDSG 0;
BA_ "GenSigSwitchedByIgnition" SG_ 1315 SVB_Lift 0;
BA_ "GenSigSendType" SG_ 1315 SVB_Lift 0;
BA_ "GenSigSwitchedByIgnition" SG_ 1315 SVB_AAG 0;
BA_ "GenSigSendType" SG_ 1315 SVB_AAG 0;
BA_ "GenSigSwitchedByIgnition" SG_ 1315 SVB_TSG_FT 0;
BA_ "GenSigSendType" SG_ 1315 SVB_TSG_FT 0;
BA_ "GenSigSwitchedByIgnition" SG_ 1315 SVB_TSG_BT 0;
BA_ "GenSigSendType" SG_ 1315 SVB_TSG_BT 0;
BA_ "GenSigSwitchedByIgnition" SG_ 1315 SVB_RDK 0;
BA_ "GenSigSendType" SG_ 1315 SVB_RDK 0;
BA_ "GenSigSwitchedByIgnition" SG_ 1315 SVB_BCM1 0;
BA_ "GenSigSendType" SG_ 1315 SVB_BCM1 0;
BA_ "GenSigSwitchedByIgnition" SG_ 1315 SVB_BCM2 0;
BA_ "GenSigSendType" SG_ 1315 SVB_BCM2 0;
BA_ "GenSigSwitchedByIgnition" SG_ 1315 SVB_TSG_HL 0;
BA_ "GenSigSendType" SG_ 1315 SVB_TSG_HL 0;
BA_ "GenSigSwitchedByIgnition" SG_ 1315 SVB_TSG_HR 0;
BA_ "GenSigSendType" SG_ 1315 SVB_TSG_HR 0;
BA_ "GenSigSwitchedByIgnition" SG_ 1315 SVB_VSG 0;
BA_ "GenSigSendType" SG_ 1315 SVB_VSG 0;
BA_ "GenSigSwitchedByIgnition" SG_ 1315 SVB_Topview 0;
BA_ "GenSigSendType" SG_ 1315 SVB_Topview 0;
BA_ "GenSigSwitchedByIgnition" SG_ 1315 SVB_Kombi 0;
BA_ "GenSigSendType" SG_ 1315 SVB_Kombi 0;
BA_ "GenSigSwitchedByIgnition" SG_ 1315 SVB_BKE 0;
BA_ "GenSigSendType" SG_ 1315 SVB_BKE 0;
BA_ "GenSigSwitchedByIgnition" SG_ 1315 SVB_PDC 0;
BA_ "GenSigSendType" SG_ 1315 SVB_PDC 0;
BA_ "GenSigSwitchedByIgnition" SG_ 1315 SVB_STH 0;
BA_ "GenSigSendType" SG_ 1315 SVB_STH 0;
BA_ "GenSigSwitchedByIgnition" SG_ 1315 SVB_RearView 0;
BA_ "GenSigSendType" SG_ 1315 SVB_RearView 0;
BA_ "GenSigSwitchedByIgnition" SG_ 1315 SVB_Stoppuhr 0;
BA_ "GenSigSendType" SG_ 1315 SVB_Stoppuhr 0;
BA_ "GenSigSwitchedByIgnition" SG_ 1315 SVB_PCM 0;
BA_ "GenSigSendType" SG_ 1315 SVB_PCM 0;
BA_ "GenSigSwitchedByIgnition" SG_ 1315 SVB_CDR 0;
BA_ "GenSigSendType" SG_ 1315 SVB_CDR 0;
BA_ "GenSigSwitchedByIgnition" SG_ 1315 SVB_Kompass 0;
BA_ "GenSigSendType" SG_ 1315 SVB_Kompass 0;
BA_ "GenSigSwitchedByIgnition" SG_ 1315 SVB_ComBox 0;
BA_ "GenSigSendType" SG_ 1315 SVB_ComBox 0;
BA_ "GenSigSwitchedByIgnition" SG_ 1315 SVB_LEH_VA 0;
BA_ "GenSigSendType" SG_ 1315 SVB_LEH_VA 0;
BA_ "GenSigSwitchedByIgnition" SG_ 1315 SVB_Ladegeraet 0;
BA_ "GenSigSendType" SG_ 1315 SVB_Ladegeraet 0;
BA_ "GenSigSwitchedByIgnition" SG_ 1315 SVB_Motor 0;
BA_ "GenSigSendType" SG_ 1315 SVB_Motor 0;
BA_ "GenSigSwitchedByIgnition" SG_ 1315 SVB_QSP 0;
BA_ "GenSigSendType" SG_ 1315 SVB_QSP 0;
BA_ "GenSigSwitchedByIgnition" SG_ 1315 SVB_Getriebe 0;
BA_ "GenSigSendType" SG_ 1315 SVB_Getriebe 0;
BA_ "GenSigSwitchedByIgnition" SG_ 1315 SVB_WHL 0;
BA_ "GenSigSendType" SG_ 1315 SVB_WHL 0;
BA_ "GenSigSwitchedByIgnition" SG_ 1315 SVB_Airbag 0;
BA_ "GenSigSendType" SG_ 1315 SVB_Airbag 0;
BA_ "GenSigSwitchedByIgnition" SG_ 1315 SVB_PSM_Ant 0;
BA_ "GenSigSendType" SG_ 1315 SVB_PSM_Ant 0;
BA_ "GenSigSwitchedByIgnition" SG_ 1315 SVB_PSM_Fwk 0;
BA_ "GenSigSendType" SG_ 1315 SVB_PSM_Fwk 0;
BA_ "GenSigSwitchedByIgnition" SG_ 1315 SVB_BMS 0;
BA_ "GenSigSendType" SG_ 1315 SVB_BMS 0;
BA_ "GenSigSwitchedByIgnition" SG_ 1315 SVB_LEH 0;
BA_ "GenSigSendType" SG_ 1315 SVB_LEH 0;
BA_ "GenSigSwitchedByIgnition" SG_ 1315 SVB_SCR 0;
BA_ "GenSigSendType" SG_ 1315 SVB_SCR 0;
BA_ "GenSigSwitchedByIgnition" SG_ 1315 SVB_EPB 0;
BA_ "GenSigSendType" SG_ 1315 SVB_EPB 0;
BA_ "GenSigSwitchedByIgnition" SG_ 1315 SVB_SSC 0;
BA_ "GenSigSendType" SG_ 1315 SVB_SSC 0;
BA_ "GenSigSwitchedByIgnition" SG_ 1315 SVB_PDCC 0;
BA_ "GenSigSendType" SG_ 1315 SVB_PDCC 0;
BA_ "GenSigSwitchedByIgnition" SG_ 1315 SVB_LWS 0;
BA_ "GenSigSendType" SG_ 1315 SVB_LWS 0;
BA_ "GenSigSwitchedByIgnition" SG_ 1315 SVB_PASM_NRA 0;
BA_ "GenSigSendType" SG_ 1315 SVB_PASM_NRA 0;
BA_ "GenSigSwitchedByIgnition" SG_ 1315 SVB_Allrad 0;
BA_ "GenSigSendType" SG_ 1315 SVB_Allrad 0;
BA_ "GenSigSwitchedByIgnition" SG_ 1315 SVB_EPS 0;
BA_ "GenSigSendType" SG_ 1315 SVB_EPS 0;
BA_ "GenSigSwitchedByIgnition" SG_ 1315 SVB_HAL 0;
BA_ "GenSigSendType" SG_ 1315 SVB_HAL 0;
BA_ "GenSigSwitchedByIgnition" SG_ 1315 SVB_EBKV 0;
BA_ "GenSigSendType" SG_ 1315 SVB_EBKV 0;
BA_ "GenSigSwitchedByIgnition" SG_ 1315 SVB_AFS 0;
BA_ "GenSigSendType" SG_ 1315 SVB_AFS 0;
BA_ "GenSigSwitchedByIgnition" SG_ 1315 SVB_SWL 0;
BA_ "GenSigSendType" SG_ 1315 SVB_SWL 0;
BA_ "GenSigSwitchedByIgnition" SG_ 1315 SVB_SWR 0;
BA_ "GenSigSendType" SG_ 1315 SVB_SWR 0;
BA_ "GenSigSwitchedByIgnition" SG_ 1315 SVB_ACC 0;
BA_ "GenSigSendType" SG_ 1315 SVB_ACC 0;
BA_ "GenSigSwitchedByIgnition" SG_ 1315 SVB_SWA 0;
BA_ "GenSigSendType" SG_ 1315 SVB_SWA 0;
BA_ "GenSigSwitchedByIgnition" SG_ 1315 SVB_EHPS 0;
BA_ "GenSigSendType" SG_ 1315 SVB_EHPS 0;
BA_ "GenSigSwitchedByIgnition" SG_ 1315 SVB_EKK 0;
BA_ "GenSigSendType" SG_ 1315 SVB_EKK 0;
BA_ "GenSigSwitchedByIgnition" SG_ 1315 SVB_Kamera 0;
BA_ "GenSigSendType" SG_ 1315 SVB_Kamera 0;
BA_ "GenSigSwitchedByIgnition" SG_ 1315 SVB_AMP 0;
BA_ "GenSigSendType" SG_ 1315 SVB_AMP 0;
BA_ "GenSigSwitchedByIgnition" SG_ 1315 SVB_TV 0;
BA_ "GenSigSendType" SG_ 1315 SVB_TV 0;
BA_ "Fehlerwert" SG_ 1428 HVLM_Restladezeit_HV_Bat_02 511;
BA_ "GenSigSwitchedByIgnition" SG_ 1428 HVLM_Restladezeit_HV_Bat_02 0;
BA_ "GenSigStartValue" SG_ 1428 HVLM_Restladezeit_HV_Bat_02 510;
BA_ "GenSigSendType" SG_ 1428 HVLM_Restladezeit_HV_Bat_02 0;
BA_ "GenSigSwitchedByIgnition" SG_ 1428 HVLM_Lademodus_HV_Bat 0;
BA_ "GenSigSendType" SG_ 1428 HVLM_Lademodus_HV_Bat 0;
BA_ "GenSigSwitchedByIgnition" SG_ 1428 HVLM_Bat_laden_aktiv 0;
BA_ "GenSigSendType" SG_ 1428 HVLM_Bat_laden_aktiv 0;
BA_ "GenSigSwitchedByIgnition" SG_ 1428 HVLM_Ladeart 0;
BA_ "GenSigSendType" SG_ 1428 HVLM_Ladeart 0;
BA_ "GenSigSwitchedByIgnition" SG_ 1428 HVLM_VK_Anf 0;
BA_ "GenSigSendType" SG_ 1428 HVLM_VK_Anf 0;
BA_ "GenSigSwitchedByIgnition" SG_ 1428 HVLM_Ladesystemhinweise 0;
BA_ "GenSigSendType" SG_ 1428 HVLM_Ladesystemhinweise 3;
BA_ "GenSigSwitchedByIgnition" SG_ 1428 HVLM_Stecker_Status 0;
BA_ "GenSigSendType" SG_ 1428 HVLM_Stecker_Status 0;
BA_ "Fehlerwert" SG_ 1428 HVLM_Langzeit_Laden 3;
BA_ "GenSigSwitchedByIgnition" SG_ 1428 HVLM_Langzeit_Laden 0;
BA_ "GenSigSendType" SG_ 1428 HVLM_Langzeit_Laden 0;
BA_ "Fehlerwert" SG_ 1428 HVLM_Klima_Temp 31;
BA_ "GenSigSwitchedByIgnition" SG_ 1428 HVLM_Klima_Temp 0;
BA_ "GenSigStartValue" SG_ 1428 HVLM_Klima_Temp 30;
BA_ "GenSigSendType" SG_ 1428 HVLM_Klima_Temp 3;
BA_ "GenSigSwitchedByIgnition" SG_ 1397 HVLM_Status_Timer_MUX 0;
BA_ "GenSigSendType" SG_ 1397 HVLM_Status_Timer_MUX 0;
BA_ "GenSigSwitchedByIgnition" SG_ 1397 HVLM_Status_Timer_1_Jahr 0;
BA_ "GenSigStartValue" SG_ 1397 HVLM_Status_Timer_1_Jahr 126;
BA_ "GenSigSwitchedByIgnition" SG_ 1397 HVLM_Status_Timer_2_Jahr 0;
BA_ "GenSigStartValue" SG_ 1397 HVLM_Status_Timer_2_Jahr 126;
BA_ "GenSigSwitchedByIgnition" SG_ 1397 HVLM_Status_Timer_3_Jahr 0;
BA_ "GenSigStartValue" SG_ 1397 HVLM_Status_Timer_3_Jahr 126;
BA_ "GenSigSwitchedByIgnition" SG_ 1397 HVLM_Status_Timer_4_Jahr 0;
BA_ "GenSigStartValue" SG_ 1397 HVLM_Status_Timer_4_Jahr 126;
BA_ "GenSigSwitchedByIgnition" SG_ 1397 HVLM_Status_Timer_7_Jahr 0;
BA_ "GenSigStartValue" SG_ 1397 HVLM_Status_Timer_7_Jahr 126;
BA_ "Fehlerwert" SG_ 1397 HVLM_Status_Timer_1_Minute 63;
BA_ "GenSigSwitchedByIgnition" SG_ 1397 HVLM_Status_Timer_1_Minute 0;
BA_ "GenSigStartValue" SG_ 1397 HVLM_Status_Timer_1_Minute 62;
BA_ "Fehlerwert" SG_ 1397 HVLM_Status_Timer_2_Minute 63;
BA_ "GenSigSwitchedByIgnition" SG_ 1397 HVLM_Status_Timer_2_Minute 0;
BA_ "GenSigStartValue" SG_ 1397 HVLM_Status_Timer_2_Minute 62;
BA_ "Fehlerwert" SG_ 1397 HVLM_Status_Timer_3_Minute 63;
BA_ "GenSigSwitchedByIgnition" SG_ 1397 HVLM_Status_Timer_3_Minute 0;
BA_ "GenSigStartValue" SG_ 1397 HVLM_Status_Timer_3_Minute 62;
BA_ "Fehlerwert" SG_ 1397 HVLM_Status_Timer_4_Minute 63;
BA_ "GenSigSwitchedByIgnition" SG_ 1397 HVLM_Status_Timer_4_Minute 0;
BA_ "GenSigStartValue" SG_ 1397 HVLM_Status_Timer_4_Minute 62;
BA_ "Fehlerwert" SG_ 1397 HVLM_Status_Timer_7_Minute 63;
BA_ "GenSigSwitchedByIgnition" SG_ 1397 HVLM_Status_Timer_7_Minute 0;
BA_ "GenSigStartValue" SG_ 1397 HVLM_Status_Timer_7_Minute 62;
BA_ "Fehlerwert" SG_ 1397 HVLM_Status_Timer_1_Monat 15;
BA_ "GenSigSwitchedByIgnition" SG_ 1397 HVLM_Status_Timer_1_Monat 0;
BA_ "Fehlerwert" SG_ 1397 HVLM_Status_Timer_2_Monat 15;
BA_ "GenSigSwitchedByIgnition" SG_ 1397 HVLM_Status_Timer_2_Monat 0;
BA_ "Fehlerwert" SG_ 1397 HVLM_Status_Timer_3_Monat 15;
BA_ "GenSigSwitchedByIgnition" SG_ 1397 HVLM_Status_Timer_3_Monat 0;
BA_ "Fehlerwert" SG_ 1397 HVLM_Status_Timer_4_Monat 15;
BA_ "GenSigSwitchedByIgnition" SG_ 1397 HVLM_Status_Timer_4_Monat 0;
BA_ "Fehlerwert" SG_ 1397 HVLM_Status_Timer_7_Monat 15;
BA_ "GenSigSwitchedByIgnition" SG_ 1397 HVLM_Status_Timer_7_Monat 0;
BA_ "Fehlerwert" SG_ 1397 HVLM_Status_Timer_1_Stunde 31;
BA_ "GenSigSwitchedByIgnition" SG_ 1397 HVLM_Status_Timer_1_Stunde 0;
BA_ "GenSigStartValue" SG_ 1397 HVLM_Status_Timer_1_Stunde 30;
BA_ "Fehlerwert" SG_ 1397 HVLM_Status_Timer_2_Stunde 31;
BA_ "GenSigSwitchedByIgnition" SG_ 1397 HVLM_Status_Timer_2_Stunde 0;
BA_ "GenSigStartValue" SG_ 1397 HVLM_Status_Timer_2_Stunde 30;
BA_ "Fehlerwert" SG_ 1397 HVLM_Status_Timer_3_Stunde 31;
BA_ "GenSigSwitchedByIgnition" SG_ 1397 HVLM_Status_Timer_3_Stunde 0;
BA_ "GenSigStartValue" SG_ 1397 HVLM_Status_Timer_3_Stunde 30;
BA_ "Fehlerwert" SG_ 1397 HVLM_Status_Timer_4_Stunde 31;
BA_ "GenSigSwitchedByIgnition" SG_ 1397 HVLM_Status_Timer_4_Stunde 0;
BA_ "GenSigStartValue" SG_ 1397 HVLM_Status_Timer_4_Stunde 30;
BA_ "Fehlerwert" SG_ 1397 HVLM_Status_Timer_7_Stunde 31;
BA_ "GenSigSwitchedByIgnition" SG_ 1397 HVLM_Status_Timer_7_Stunde 0;
BA_ "GenSigStartValue" SG_ 1397 HVLM_Status_Timer_7_Stunde 30;
BA_ "GenSigSwitchedByIgnition" SG_ 1397 HVLM_Status_Timer_1_Tag 0;
BA_ "GenSigSwitchedByIgnition" SG_ 1397 HVLM_Status_Timer_2_Tag 0;
BA_ "GenSigSwitchedByIgnition" SG_ 1397 HVLM_Status_Timer_3_Tag 0;
BA_ "GenSigSwitchedByIgnition" SG_ 1397 HVLM_Status_Timer_4_Tag 0;
BA_ "GenSigSwitchedByIgnition" SG_ 1397 HVLM_Status_Timer_7_Tag 0;
BA_ "GenSigSwitchedByIgnition" SG_ 1397 HVLM_Status_Timer_1_Laden 0;
BA_ "GenSigSwitchedByIgnition" SG_ 1397 HVLM_Status_Timer_2_Laden 0;
BA_ "GenSigSwitchedByIgnition" SG_ 1397 HVLM_Status_Timer_3_Laden 0;
BA_ "GenSigSwitchedByIgnition" SG_ 1397 HVLM_Status_Timer_4_Laden 0;
BA_ "GenSigSwitchedByIgnition" SG_ 1397 HVLM_Status_Timer_1_Vorklima 0;
BA_ "GenSigSwitchedByIgnition" SG_ 1397 HVLM_Status_Timer_2_Vorklima 0;
BA_ "GenSigSwitchedByIgnition" SG_ 1397 HVLM_Status_Timer_3_Vorklima 0;
BA_ "GenSigSwitchedByIgnition" SG_ 1397 HVLM_Status_Timer_4_Vorklima 0;
BA_ "GenSigSwitchedByIgnition" SG_ 1397 HVLM_Status_Timer_1_Zyklus_Mo 0;
BA_ "GenSigSwitchedByIgnition" SG_ 1397 HVLM_Status_Timer_2_Zyklus_Mo 0;
BA_ "GenSigSwitchedByIgnition" SG_ 1397 HVLM_Status_Timer_3_Zyklus_Mo 0;
BA_ "GenSigSwitchedByIgnition" SG_ 1397 HVLM_Status_Timer_4_Zyklus_Mo 0;
BA_ "GenSigSwitchedByIgnition" SG_ 1397 HVLM_Status_Timer_1_Zyklus_Di 0;
BA_ "GenSigSwitchedByIgnition" SG_ 1397 HVLM_Status_Timer_2_Zyklus_Di 0;
BA_ "GenSigSwitchedByIgnition" SG_ 1397 HVLM_Status_Timer_3_Zyklus_Di 0;
BA_ "GenSigSwitchedByIgnition" SG_ 1397 HVLM_Status_Timer_4_Zyklus_Di 0;
BA_ "GenSigSwitchedByIgnition" SG_ 1397 HVLM_Status_Timer_1_Zyklus_Mi 0;
BA_ "GenSigSwitchedByIgnition" SG_ 1397 HVLM_Status_Timer_2_Zyklus_Mi 0;
BA_ "GenSigSwitchedByIgnition" SG_ 1397 HVLM_Status_Timer_3_Zyklus_Mi 0;
BA_ "GenSigSwitchedByIgnition" SG_ 1397 HVLM_Status_Timer_4_Zyklus_Mi 0;
BA_ "GenSigSwitchedByIgnition" SG_ 1397 HVLM_Status_Timer_1_Zyklus_Do 0;
BA_ "GenSigSwitchedByIgnition" SG_ 1397 HVLM_Status_Timer_2_Zyklus_Do 0;
BA_ "GenSigSwitchedByIgnition" SG_ 1397 HVLM_Status_Timer_3_Zyklus_Do 0;
BA_ "GenSigSwitchedByIgnition" SG_ 1397 HVLM_Status_Timer_4_Zyklus_Do 0;
BA_ "GenSigSwitchedByIgnition" SG_ 1397 HVLM_Status_Timer_1_Zyklus_Fr 0;
BA_ "GenSigSwitchedByIgnition" SG_ 1397 HVLM_Status_Timer_2_Zyklus_Fr 0;
BA_ "GenSigSwitchedByIgnition" SG_ 1397 HVLM_Status_Timer_3_Zyklus_Fr 0;
BA_ "GenSigSwitchedByIgnition" SG_ 1397 HVLM_Status_Timer_4_Zyklus_Fr 0;
BA_ "GenSigSwitchedByIgnition" SG_ 1397 HVLM_Status_Timer_1_Zyklus_Sa 0;
BA_ "GenSigSwitchedByIgnition" SG_ 1397 HVLM_Status_Timer_2_Zyklus_Sa 0;
BA_ "GenSigSwitchedByIgnition" SG_ 1397 HVLM_Status_Timer_3_Zyklus_Sa 0;
BA_ "GenSigSwitchedByIgnition" SG_ 1397 HVLM_Status_Timer_4_Zyklus_Sa 0;
BA_ "GenSigSwitchedByIgnition" SG_ 1397 HVLM_Status_Timer_1_Zyklus_So 0;
BA_ "GenSigSwitchedByIgnition" SG_ 1397 HVLM_Status_Timer_2_Zyklus_So 0;
BA_ "GenSigSwitchedByIgnition" SG_ 1397 HVLM_Status_Timer_3_Zyklus_So 0;
BA_ "GenSigSwitchedByIgnition" SG_ 1397 HVLM_Status_Timer_4_Zyklus_So 0;
BA_ "GenSigSwitchedByIgnition" SG_ 1397 HVLM_Status_Timer_1_Zyklus_WH 0;
BA_ "GenSigSwitchedByIgnition" SG_ 1397 HVLM_Status_Timer_2_Zyklus_WH 0;
BA_ "GenSigSwitchedByIgnition" SG_ 1397 HVLM_Status_Timer_3_Zyklus_WH 0;
BA_ "GenSigSwitchedByIgnition" SG_ 1397 HVLM_Status_Timer_4_Zyklus_WH 0;
BA_ "GenSigSwitchedByIgnition" SG_ 1397 HVLM_Status_Nachtstrom_X_Std_Anf 0;
BA_ "GenSigStartValue" SG_ 1397 HVLM_Status_Nachtstrom_X_Std_Anf 62;
BA_ "GenSigSendType" SG_ 1397 HVLM_Status_Nachtstrom_X_Std_Anf 0;
BA_ "GenSigSwitchedByIgnition" SG_ 1397 HVLM_Status_Nachtstrom_Prof 0;
BA_ "GenSigSendType" SG_ 1397 HVLM_Status_Nachtstrom_Prof 0;
BA_ "GenSigSwitchedByIgnition" SG_ 1397 HVLM_Status_Nachtstrom_X_Std_End 0;
BA_ "GenSigStartValue" SG_ 1397 HVLM_Status_Nachtstrom_X_Std_End 62;
BA_ "GenSigSendType" SG_ 1397 HVLM_Status_Nachtstrom_X_Std_End 0;
BA_ "GenSigSwitchedByIgnition" SG_ 1397 HVLM_Status_Nachtstrom_Akt_Prof 0;
BA_ "GenSigSendType" SG_ 1397 HVLM_Status_Nachtstrom_Akt_Prof 0;
BA_ "Fehlerwert" SG_ 1397 HVLM_Status_Laden 7;
BA_ "GenSigSwitchedByIgnition" SG_ 1397 HVLM_Status_Laden 0;
BA_ "GenSigStartValue" SG_ 1397 HVLM_Status_Laden 6;
BA_ "GenSigSwitchedByIgnition" SG_ 1895 ISO_eCall_Req_Data 0;
BA_ "GenSigFuncType" SG_ 1895 ISO_eCall_Req_Data 9;
BA_ "GenSigSendType" SG_ 1895 ISO_eCall_Req_Data 3;
BA_ "GenSigSwitchedByIgnition" SG_ 2001 ISO_eCall_Resp_Data 0;
BA_ "GenSigFuncType" SG_ 2001 ISO_eCall_Resp_Data 9;
BA_ "GenSigSendType" SG_ 2001 ISO_eCall_Resp_Data 3;
BA_ "GenSigSwitchedByIgnition" SG_ 1792 ISO_ALL_01_Req_Data 0;
BA_ "GenSigFuncType" SG_ 1792 ISO_ALL_01_Req_Data 9;
BA_ "GenSigSendType" SG_ 1792 ISO_ALL_01_Req_Data 3;
BA_ "GenSigSwitchedByIgnition" SG_ 1907 ISO_Info_El_Req_Data 0;
BA_ "GenSigFuncType" SG_ 1907 ISO_Info_El_Req_Data 9;
BA_ "GenSigSendType" SG_ 1907 ISO_Info_El_Req_Data 3;
BA_ "GenSigSwitchedByIgnition" SG_ 2013 ISO_Info_El_Resp_Data 0;
BA_ "GenSigFuncType" SG_ 2013 ISO_Info_El_Resp_Data 9;
BA_ "GenSigSendType" SG_ 2013 ISO_Info_El_Resp_Data 3;
BA_ "GenSigSwitchedByIgnition" SG_ 1862 ISO_Klima_Req_Data 0;
BA_ "GenSigFuncType" SG_ 1862 ISO_Klima_Req_Data 9;
BA_ "GenSigSendType" SG_ 1862 ISO_Klima_Req_Data 3;
BA_ "GenSigSwitchedByIgnition" SG_ 1968 ISO_Klima_Resp_Data 0;
BA_ "GenSigFuncType" SG_ 1968 ISO_Klima_Resp_Data 9;
BA_ "GenSigSendType" SG_ 1968 ISO_Klima_Resp_Data 3;
BA_ "GenSigSwitchedByIgnition" SG_ 1817 ISO_Klimakomp_Req_Data 0;
BA_ "GenSigFuncType" SG_ 1817 ISO_Klimakomp_Req_Data 9;
BA_ "GenSigSendType" SG_ 1817 ISO_Klimakomp_Req_Data 3;
BA_ "GenSigSwitchedByIgnition" SG_ 1923 ISO_Klimakomp_Resp_Data 0;
BA_ "GenSigFuncType" SG_ 1923 ISO_Klimakomp_Resp_Data 9;
BA_ "GenSigSendType" SG_ 1923 ISO_Klimakomp_Resp_Data 3;
BA_ "GenSigSwitchedByIgnition" SG_ 1812 ISO_Kombi_Req_Data 0;
BA_ "GenSigFuncType" SG_ 1812 ISO_Kombi_Req_Data 9;
BA_ "GenSigSendType" SG_ 1812 ISO_Kombi_Req_Data 3;
BA_ "GenSigSwitchedByIgnition" SG_ 1918 ISO_Kombi_Resp_Data 0;
BA_ "GenSigFuncType" SG_ 1918 ISO_Kombi_Resp_Data 9;
BA_ "GenSigSendType" SG_ 1918 ISO_Kombi_Resp_Data 3;
BA_ "GenSigSwitchedByIgnition" SG_ 1846 ISO_Miko_Req_Data 0;
BA_ "GenSigSendType" SG_ 1846 ISO_Miko_Req_Data 3;
BA_ "GenSigSwitchedByIgnition" SG_ 1952 ISO_Miko_Resp_Data 0;
BA_ "GenSigSendType" SG_ 1952 ISO_Miko_Resp_Data 3;
BA_ "GenSigSwitchedByIgnition" SG_ 1803 ISO_RDK_Req_Data 0;
BA_ "GenSigFuncType" SG_ 1803 ISO_RDK_Req_Data 9;
BA_ "GenSigSendType" SG_ 1803 ISO_RDK_Req_Data 3;
BA_ "GenSigSwitchedByIgnition" SG_ 1909 ISO_RDK_Resp_Data 0;
BA_ "GenSigFuncType" SG_ 1909 ISO_RDK_Resp_Data 9;
BA_ "GenSigSendType" SG_ 1909 ISO_RDK_Resp_Data 3;
BA_ "GenSigSwitchedByIgnition" SG_ 1424 KY_Funkschl_Nr 0;
BA_ "GenSigSendType" SG_ 1424 KY_Funkschl_Nr 3;
BA_ "GenSigSwitchedByIgnition" SG_ 1424 KY_ID_Geb_autorisiert 0;
BA_ "GenSigSendType" SG_ 1424 KY_ID_Geb_autorisiert 3;
BA_ "GenSigSwitchedByIgnition" SG_ 1424 KY_ID_Geb_steckt 0;
BA_ "GenSigSendType" SG_ 1424 KY_ID_Geb_steckt 3;
BA_ "GenSigSwitchedByIgnition" SG_ 1424 KY_FFB_Frequenz 0;
BA_ "GenSigSendType" SG_ 1424 KY_FFB_Frequenz 3;
BA_ "GenSigSwitchedByIgnition" SG_ 1424 KY_HF_Aktiv 0;
BA_ "GenSigSendType" SG_ 1424 KY_HF_Aktiv 3;
BA_ "GenSigSwitchedByIgnition" SG_ 1424 KY_LF_Aktiv 0;
BA_ "GenSigSendType" SG_ 1424 KY_LF_Aktiv 3;
BA_ "GenSigSwitchedByIgnition" SG_ 1424 KY_ELV_verr 0;
BA_ "GenSigSendType" SG_ 1424 KY_ELV_verr 3;
BA_ "GenSigSwitchedByIgnition" SG_ 1424 KY_ELV_entr 0;
BA_ "GenSigSendType" SG_ 1424 KY_ELV_entr 3;
BA_ "GenSigSwitchedByIgnition" SG_ 1424 KY_ELV_enable_Anforderung 0;
BA_ "GenSigSendType" SG_ 1424 KY_ELV_enable_Anforderung 3;
BA_ "GenSigSwitchedByIgnition" SG_ 1424 KY_Valet_Parking 0;
BA_ "GenSigSendType" SG_ 1424 KY_Valet_Parking 3;
BA_ "GenSigSwitchedByIgnition" SG_ 1424 KY_Keyless_Verbau 0;
BA_ "GenSigSendType" SG_ 1424 KY_Keyless_Verbau 3;
BA_ "GenSigSwitchedByIgnition" SG_ 1424 KY_FBS_Fahrer_Hinweise 0;
BA_ "GenSigSendType" SG_ 1424 KY_FBS_Fahrer_Hinweise 3;
BA_ "GenSigSwitchedByIgnition" SG_ 1424 FBS_Warn_Lenkung_def 0;
BA_ "GenSigSendType" SG_ 1424 FBS_Warn_Lenkung_def 3;
BA_ "GenSigSwitchedByIgnition" SG_ 1424 FBS_Warn_LenkVerriegelung_def 0;
BA_ "GenSigSendType" SG_ 1424 FBS_Warn_LenkVerriegelung_def 3;
BA_ "GenSigSwitchedByIgnition" SG_ 1424 FBS_Warn_Schluessel_Batt 0;
BA_ "GenSigSendType" SG_ 1424 FBS_Warn_Schluessel_Batt 3;
BA_ "GenSigSwitchedByIgnition" SG_ 1424 FBS_Prio_Warn_04 0;
BA_ "GenSigSendType" SG_ 1424 FBS_Prio_Warn_04 3;
BA_ "GenSigSwitchedByIgnition" SG_ 1424 FBS_Prio_Warn_05 0;
BA_ "GenSigSendType" SG_ 1424 FBS_Prio_Warn_05 3;
BA_ "GenSigSwitchedByIgnition" SG_ 1424 KY_KYL_Fahrer_Hinweise 0;
BA_ "GenSigSendType" SG_ 1424 KY_KYL_Fahrer_Hinweise 3;
BA_ "GenSigSwitchedByIgnition" SG_ 1424 KYL_Warn_kein_Schluessel 0;
BA_ "GenSigSendType" SG_ 1424 KYL_Warn_kein_Schluessel 3;
BA_ "GenSigSwitchedByIgnition" SG_ 1424 KYL_Warn_Kessy_defekt 0;
BA_ "GenSigSendType" SG_ 1424 KYL_Warn_Kessy_defekt 3;
BA_ "GenSigSwitchedByIgnition" SG_ 1424 KY_KYL_Prio_Warn_03 0;
BA_ "GenSigSendType" SG_ 1424 KY_KYL_Prio_Warn_03 3;
BA_ "GenSigSwitchedByIgnition" SG_ 1424 KY_KYL_Prio_Warn_04 0;
BA_ "GenSigSendType" SG_ 1424 KY_KYL_Prio_Warn_04 3;
BA_ "GenSigSwitchedByIgnition" SG_ 1424 KY_KYL_Prio_Warn_05 0;
BA_ "GenSigSendType" SG_ 1424 KY_KYL_Prio_Warn_05 3;
BA_ "GenSigSwitchedByIgnition" SG_ 1424 KY_Schluessel_Soll 0;
BA_ "GenSigSendType" SG_ 1424 KY_Schluessel_Soll 3;
BA_ "GenSigSwitchedByIgnition" SG_ 1424 KY_Schluessel_Ist 0;
BA_ "GenSigSendType" SG_ 1424 KY_Schluessel_Ist 3;
BA_ "GenSigSwitchedByIgnition" SG_ 1424 KY_WFS_Safe 0;
BA_ "GenSigSendType" SG_ 1424 KY_WFS_Safe 3;
BA_ "GenSigSwitchedByIgnition" SG_ 1424 KY_WFS_LZ 0;
BA_ "GenSigSendType" SG_ 1424 KY_WFS_LZ 3;
BA_ "GenSigSwitchedByIgnition" SG_ 1424 KY_StartStopp_Info 0;
BA_ "GenSigSendType" SG_ 1424 KY_StartStopp_Info 3;
BA_ "GenSigSwitchedByIgnition" SG_ 1424 KYL_Notzuendschloss 0;
BA_ "GenSigSendType" SG_ 1424 KYL_Notzuendschloss 0;
BA_ "GenSigSwitchedByIgnition" SG_ 1424 KYL_Warn_Notzuendschloss 0;
BA_ "GenSigSendType" SG_ 1424 KYL_Warn_Notzuendschloss 0;
BA_ "GenSigSwitchedByIgnition" SG_ 1424 FBS_KD_Fehler 0;
BA_ "GenSigSendType" SG_ 1424 FBS_KD_Fehler 3;
BA_ "GenSigSwitchedByIgnition" SG_ 1424 SK_Anf_DTC_Abfrage 0;
BA_ "GenSigSendType" SG_ 1424 SK_Anf_DTC_Abfrage 3;
BA_ "GenSigSwitchedByIgnition" SG_ 1424 SK_Anf_DTC_Abfrage_sofort 0;
BA_ "GenSigSendType" SG_ 1424 SK_Anf_DTC_Abfrage_sofort 3;
BA_ "GenSigSwitchedByIgnition" SG_ 960 Klemmen_Status_01_CHK 0;
BA_ "GenSigFuncType" SG_ 960 Klemmen_Status_01_CHK 3;
BA_ "GenSigSendType" SG_ 960 Klemmen_Status_01_CHK 0;
BA_ "GenSigSwitchedByIgnition" SG_ 960 Klemmen_Status_01_BZ 0;
BA_ "GenSigFuncType" SG_ 960 Klemmen_Status_01_BZ 1;
BA_ "GenSigSendType" SG_ 960 Klemmen_Status_01_BZ 0;
BA_ "GenSigSwitchedByIgnition" SG_ 960 ZV_verriegelt_extern_soll_02 0;
BA_ "GenSigSendType" SG_ 960 ZV_verriegelt_extern_soll_02 3;
BA_ "GenSigSwitchedByIgnition" SG_ 960 ZAS_Kl_S 0;
BA_ "GenSigSendType" SG_ 960 ZAS_Kl_S 3;
BA_ "GenSigSwitchedByIgnition" SG_ 960 ZAS_Kl_15 0;
BA_ "GenSigFuncType" SG_ 960 ZAS_Kl_15 6;
BA_ "NWM-WakeupAllowed" SG_ 960 ZAS_Kl_15 1;
BA_ "GenSigSendType" SG_ 960 ZAS_Kl_15 3;
BA_ "GenSigSwitchedByIgnition" SG_ 960 ZAS_Kl_X 0;
BA_ "GenSigSendType" SG_ 960 ZAS_Kl_X 3;
BA_ "GenSigSwitchedByIgnition" SG_ 960 ZAS_Kl_50 0;
BA_ "GenSigSendType" SG_ 960 ZAS_Kl_50 3;
BA_ "GenSigSwitchedByIgnition" SG_ 959 KL_Drehz_Anh 0;
BA_ "GenSigSendType" SG_ 959 KL_Drehz_Anh 0;
BA_ "GenSigSwitchedByIgnition" SG_ 959 KL_Vorwarn_Komp_ein 0;
BA_ "GenSigSendType" SG_ 959 KL_Vorwarn_Komp_ein 0;
BA_ "GenSigSwitchedByIgnition" SG_ 959 KL_Handshake_BEM 0;
BA_ "GenSigSendType" SG_ 959 KL_Handshake_BEM 0;
BA_ "GenSigSwitchedByIgnition" SG_ 959 KL_Komp_Moment_alt 0;
BA_ "GenSigFuncType" SG_ 959 KL_Komp_Moment_alt 5;
BA_ "GenSigSendType" SG_ 959 KL_Komp_Moment_alt 0;
BA_ "GenSigSwitchedByIgnition" SG_ 959 KL_Vorwarn_HHS_ein 0;
BA_ "GenSigSendType" SG_ 959 KL_Vorwarn_HHS_ein 0;
BA_ "GenSigSwitchedByIgnition" SG_ 959 KL_Vorwarn_HFS_ein 0;
BA_ "GenSigSendType" SG_ 959 KL_Vorwarn_HFS_ein 0;
BA_ "GenSigSwitchedByIgnition" SG_ 959 KL_Vorwarn_Zuheizer_ein 0;
BA_ "GenSigSendType" SG_ 959 KL_Vorwarn_Zuheizer_ein 0;
BA_ "GenSigSwitchedByIgnition" SG_ 959 KL_KD_Fehler 0;
BA_ "GenSigSendType" SG_ 959 KL_KD_Fehler 0;
BA_ "Fehlerwert" SG_ 959 KL_Comp_rev_rq 255;
BA_ "GenSigSwitchedByIgnition" SG_ 959 KL_Comp_rev_rq 0;
BA_ "GenSigSendType" SG_ 959 KL_Comp_rev_rq 0;
BA_ "GenSigSwitchedByIgnition" SG_ 959 KL_Charisma_FahrPr 0;
BA_ "GenSigSendType" SG_ 959 KL_Charisma_FahrPr 0;
BA_ "GenSigSwitchedByIgnition" SG_ 959 KL_Charisma_Status 0;
BA_ "GenSigSendType" SG_ 959 KL_Charisma_Status 0;
BA_ "GenSigSwitchedByIgnition" SG_ 959 KL_Charisma_Umschaltung 0;
BA_ "GenSigSendType" SG_ 959 KL_Charisma_Umschaltung 0;
BA_ "Fehlerwert" SG_ 959 KL_Last_Kompr 255;
BA_ "GenSigSwitchedByIgnition" SG_ 959 KL_Last_Kompr 0;
BA_ "GenSigSendType" SG_ 959 KL_Last_Kompr 0;
BA_ "GenSigSwitchedByIgnition" SG_ 959 KL_Leistung_Hzg_Soll 0;
BA_ "GenSigSendType" SG_ 959 KL_Leistung_Hzg_Soll 0;
BA_ "Fehlerwert" SG_ 959 KL_Anf_KL 255;
BA_ "GenSigSwitchedByIgnition" SG_ 959 KL_Anf_KL 0;
BA_ "GenSigSendType" SG_ 959 KL_Anf_KL 0;
BA_ "GenSigSwitchedByIgnition" SG_ 959 KL_4_Zonen 0;
BA_ "GenSigSendType" SG_ 959 KL_4_Zonen 0;
BA_ "GenSigSwitchedByIgnition" SG_ 959 KL_AC_Schalter 0;
BA_ "GenSigSendType" SG_ 959 KL_AC_Schalter 0;
BA_ "GenSigSwitchedByIgnition" SG_ 959 KL_Zustand 0;
BA_ "GenSigSendType" SG_ 959 KL_Zustand 0;
BA_ "GenSigSwitchedByIgnition" SG_ 959 KL_Thermomanagement 0;
BA_ "GenSigSendType" SG_ 959 KL_Thermomanagement 0;
BA_ "GenSigSwitchedByIgnition" SG_ 959 KL_Comp_enable 0;
BA_ "GenSigSendType" SG_ 959 KL_Comp_enable 0;
BA_ "GenSigSwitchedByIgnition" SG_ 959 KL_StartStopp_Info 0;
BA_ "GenSigSendType" SG_ 959 KL_StartStopp_Info 0;
BA_ "GenSigSwitchedByIgnition" SG_ 959 KL_el_Zuheizer_Stufe 0;
BA_ "GenSigSendType" SG_ 959 KL_el_Zuheizer_Stufe 0;
BA_ "GenSigSendType" SG_ 959 KL_Diag_Absperrvent 0;
BA_ "GenSigSwitchedByIgnition" SG_ 1636 KL_Stromsparmodus 0;
BA_ "GenSigSendType" SG_ 1636 KL_Stromsparmodus 3;
BA_ "GenSigSwitchedByIgnition" SG_ 1636 KL_Spg_Hzg_aus 0;
BA_ "GenSigSendType" SG_ 1636 KL_Spg_Hzg_aus 3;
BA_ "GenSigSwitchedByIgnition" SG_ 1636 KL_AQS_Empfindlichkeit 0;
BA_ "GenSigSendType" SG_ 1636 KL_AQS_Empfindlichkeit 3;
BA_ "GenSigSwitchedByIgnition" SG_ 1636 KL_SIH_Soll_li 0;
BA_ "GenSigSendType" SG_ 1636 KL_SIH_Soll_li 3;
BA_ "GenSigSwitchedByIgnition" SG_ 1636 KL_SIH_Takt_li 0;
BA_ "GenSigSendType" SG_ 1636 KL_SIH_Takt_li 3;
BA_ "GenSigSwitchedByIgnition" SG_ 1636 KL_SIL_Soll_li 0;
BA_ "GenSigSendType" SG_ 1636 KL_SIL_Soll_li 3;
BA_ "GenSigSwitchedByIgnition" SG_ 1636 KL_LRH_aus 0;
BA_ "GenSigSendType" SG_ 1636 KL_LRH_aus 3;
BA_ "GenSigSwitchedByIgnition" SG_ 1636 KL_SIH_Soll_re 0;
BA_ "GenSigSendType" SG_ 1636 KL_SIH_Soll_re 3;
BA_ "GenSigSwitchedByIgnition" SG_ 1636 KL_SIH_Takt_re 0;
BA_ "GenSigSendType" SG_ 1636 KL_SIH_Takt_re 3;
BA_ "GenSigSwitchedByIgnition" SG_ 1636 KL_SIL_Soll_re 0;
BA_ "GenSigSendType" SG_ 1636 KL_SIL_Soll_re 3;
BA_ "GenSigSwitchedByIgnition" SG_ 1636 KL_Beschlagsgefahr 0;
BA_ "GenSigSendType" SG_ 1636 KL_Beschlagsgefahr 3;
BA_ "GenSigSwitchedByIgnition" SG_ 1636 KL_HSH_ein_Soll 0;
BA_ "GenSigSendType" SG_ 1636 KL_HSH_ein_Soll 3;
BA_ "GenSigSwitchedByIgnition" SG_ 1636 KL_HSH_Taktung 0;
BA_ "GenSigSendType" SG_ 1636 KL_HSH_Taktung 3;
BA_ "GenSigSwitchedByIgnition" SG_ 1636 KL_Zuheizer_Freigabe 0;
BA_ "GenSigSendType" SG_ 1636 KL_Zuheizer_Freigabe 3;
BA_ "GenSigSwitchedByIgnition" SG_ 1636 KL_ZHE_Status 0;
BA_ "GenSigSendType" SG_ 1636 KL_ZHE_Status 3;
BA_ "GenSigSwitchedByIgnition" SG_ 1636 KL_FSH_Status 0;
BA_ "GenSigSendType" SG_ 1636 KL_FSH_Status 3;
BA_ "GenSigSwitchedByIgnition" SG_ 1636 KL_LRH_on_off 0;
BA_ "GenSigSendType" SG_ 1636 KL_LRH_on_off 3;
BA_ "Fehlerwert" SG_ 1636 KL_Umluftklappe_Status 15;
BA_ "GenSigSwitchedByIgnition" SG_ 1636 KL_Umluftklappe_Status 0;
BA_ "GenSigStartValue" SG_ 1636 KL_Umluftklappe_Status 14;
BA_ "GenSigSendType" SG_ 1636 KL_Umluftklappe_Status 0;
BA_ "Fehlerwert" SG_ 1636 KL_Geblaese_Status 15;
BA_ "GenSigSwitchedByIgnition" SG_ 1636 KL_Geblaese_Status 0;
BA_ "GenSigStartValue" SG_ 1636 KL_Geblaese_Status 14;
BA_ "GenSigSendType" SG_ 1636 KL_Geblaese_Status 0;
BA_ "Fehlerwert" SG_ 1636 KL_I_Geblaese 255;
BA_ "GenSigSwitchedByIgnition" SG_ 1636 KL_I_Geblaese 0;
BA_ "GenSigSendType" SG_ 1636 KL_I_Geblaese 0;
BA_ "Fehlerwert" SG_ 1636 KL_Kompressorstrom_soll 1023;
BA_ "GenSigSwitchedByIgnition" SG_ 1636 KL_Kompressorstrom_soll 0;
BA_ "GenSigStartValue" SG_ 1636 KL_Kompressorstrom_soll 1022;
BA_ "GenSigSendType" SG_ 1636 KL_Kompressorstrom_soll 3;
BA_ "Fehlerwert" SG_ 1636 KL_FSH_P_Soll 63;
BA_ "GenSigSwitchedByIgnition" SG_ 1636 KL_FSH_P_Soll 0;
BA_ "GenSigSendType" SG_ 1636 KL_FSH_P_Soll 3;
BA_ "GenSigSwitchedByIgnition" SG_ 1646 KL_STL_aktiv 0;
BA_ "GenSigSendType" SG_ 1646 KL_STL_aktiv 3;
BA_ "GenSigSwitchedByIgnition" SG_ 1646 KL_STH_aktiv 0;
BA_ "GenSigSendType" SG_ 1646 KL_STH_aktiv 3;
BA_ "GenSigSwitchedByIgnition" SG_ 1646 KL_Solarluefter_aktiv 0;
BA_ "GenSigSendType" SG_ 1646 KL_Solarluefter_aktiv 3;
BA_ "GenSigSwitchedByIgnition" SG_ 1646 KL_Umluft_Taste 0;
BA_ "GenSigSendType" SG_ 1646 KL_Umluft_Taste 3;
BA_ "Fehlerwert" SG_ 1646 KL_Geblaese_Fond_Status 15;
BA_ "GenSigSwitchedByIgnition" SG_ 1646 KL_Geblaese_Fond_Status 0;
BA_ "GenSigStartValue" SG_ 1646 KL_Geblaese_Fond_Status 14;
BA_ "GenSigSendType" SG_ 1646 KL_Geblaese_Fond_Status 0;
BA_ "GenSigSwitchedByIgnition" SG_ 1646 KL_STH_Ansteuerung 0;
BA_ "GenSigSendType" SG_ 1646 KL_STH_Ansteuerung 3;
BA_ "GenSigSwitchedByIgnition" SG_ 1646 KL_STH_Betriebsdauer 0;
BA_ "GenSigSendType" SG_ 1646 KL_STH_Betriebsdauer 3;
BA_ "GenSigSwitchedByIgnition" SG_ 1646 KL_Magnetventil 0;
BA_ "GenSigSendType" SG_ 1646 KL_Magnetventil 3;
BA_ "GenSigSwitchedByIgnition" SG_ 1646 KL_WaPu 0;
BA_ "GenSigSendType" SG_ 1646 KL_WaPu 3;
BA_ "GenSigSwitchedByIgnition" SG_ 1646 KL_Freigabe_KRH_li 0;
BA_ "GenSigSendType" SG_ 1646 KL_Freigabe_KRH_li 3;
BA_ "GenSigSwitchedByIgnition" SG_ 1646 KL_Freigabe_KRH_re 0;
BA_ "GenSigSendType" SG_ 1646 KL_Freigabe_KRH_re 3;
BA_ "GenSigSwitchedByIgnition" SG_ 1646 KL_BCmE_Livetip_Freigabe 0;
BA_ "GenSigSendType" SG_ 1646 KL_BCmE_Livetip_Freigabe 3;
BA_ "GenSigSwitchedByIgnition" SG_ 1646 KL_HYB_ASV_hinten_schliessen_Anf 0;
BA_ "GenSigSendType" SG_ 1646 KL_HYB_ASV_hinten_schliessen_Anf 3;
BA_ "GenSigSwitchedByIgnition" SG_ 1646 KL_HYB_ASV_vorne_schliessen_Anf 0;
BA_ "GenSigSendType" SG_ 1646 KL_HYB_ASV_vorne_schliessen_Anf 3;
BA_ "GenSigSwitchedByIgnition" SG_ 1646 KL_HYB_Spuelbetrieb_Freigabe 0;
BA_ "GenSigSendType" SG_ 1646 KL_HYB_Spuelbetrieb_Freigabe 3;
BA_ "GenSigSendType" SG_ 1646 KL_Fehler_ElWaPu 0;
BA_ "Fehlerwert" SG_ 1646 KL_Innen_Temp 255;
BA_ "GenSigSwitchedByIgnition" SG_ 1646 KL_Innen_Temp 0;
BA_ "GenSigStartValue" SG_ 1646 KL_Innen_Temp 254;
BA_ "GenSigSendType" SG_ 1646 KL_Innen_Temp 0;
BA_ "GenSigSwitchedByIgnition" SG_ 1646 KL_Sonnenintensitaet 0;
BA_ "GenSigSendType" SG_ 1646 KL_Sonnenintensitaet 0;
BA_ "GenSigMissingSourceValue" SG_ 1646 KL_AussenTemp_WK 255;
BA_ "Fehlerwert" SG_ 1646 KL_AussenTemp_WK 255;
BA_ "GenSigSwitchedByIgnition" SG_ 1646 KL_AussenTemp_WK 0;
BA_ "GenSigStartValue" SG_ 1646 KL_AussenTemp_WK 254;
BA_ "GenSigSendType" SG_ 1646 KL_AussenTemp_WK 0;
BA_ "GenSigSwitchedByIgnition" SG_ 1655 KL_T_PSM_off 0;
BA_ "GenSigSendType" SG_ 1655 KL_T_PSM_off 3;
BA_ "GenSigSwitchedByIgnition" SG_ 1655 KL_T_HSpoiler 0;
BA_ "GenSigSendType" SG_ 1655 KL_T_HSpoiler 3;
BA_ "GenSigSwitchedByIgnition" SG_ 1655 KL_T_PASM_1 0;
BA_ "NWM-WakeupAllowed" SG_ 1655 KL_T_PASM_1 1;
BA_ "GenSigSendType" SG_ 1655 KL_T_PASM_1 3;
BA_ "GenSigSwitchedByIgnition" SG_ 1655 KL_T_PASM_2 0;
BA_ "NWM-WakeupAllowed" SG_ 1655 KL_T_PASM_2 1;
BA_ "GenSigSendType" SG_ 1655 KL_T_PASM_2 3;
BA_ "GenSigSwitchedByIgnition" SG_ 1655 KL_T_FSH 0;
BA_ "GenSigSendType" SG_ 1655 KL_T_FSH 3;
BA_ "GenSigSwitchedByIgnition" SG_ 1655 KL_T_ZV 0;
BA_ "GenSigSendType" SG_ 1655 KL_T_ZV 4;
BA_ "GenSigSwitchedByIgnition" SG_ 1655 KL_T_Abgasklappe 0;
BA_ "GenSigSendType" SG_ 1655 KL_T_Abgasklappe 3;
BA_ "GenSigSwitchedByIgnition" SG_ 1655 KL_T_Rollo_kurz 0;
BA_ "GenSigSendType" SG_ 1655 KL_T_Rollo_kurz 3;
BA_ "GenSigSwitchedByIgnition" SG_ 1655 KL_T_Rollo_lang 0;
BA_ "GenSigSendType" SG_ 1655 KL_T_Rollo_lang 3;
BA_ "GenSigSwitchedByIgnition" SG_ 1655 KL_T_STH 0;
BA_ "GenSigSendType" SG_ 1655 KL_T_STH 3;
BA_ "GenSigSwitchedByIgnition" SG_ 1655 KL_Sportmodus 0;
BA_ "NWM-WakeupAllowed" SG_ 1655 KL_Sportmodus 1;
BA_ "GenSigSendType" SG_ 1655 KL_Sportmodus 3;
BA_ "GenSigSwitchedByIgnition" SG_ 1655 KL_T_TC_off 0;
BA_ "GenSigSendType" SG_ 1655 KL_T_TC_off 3;
BA_ "GenSigSwitchedByIgnition" SG_ 1655 KL_T_LeVerstFond 0;
BA_ "GenSigSendType" SG_ 1655 KL_T_LeVerstFond 4;
BA_ "GenSigSwitchedByIgnition" SG_ 1655 KL_T_SitzLVerstFond 0;
BA_ "GenSigSendType" SG_ 1655 KL_T_SitzLVerstFond 4;
BA_ "GenSigSwitchedByIgnition" SG_ 1655 KL_Charisma_Anzeige 0;
BA_ "GenSigSendType" SG_ 1655 KL_Charisma_Anzeige 0;
BA_ "GenSigSwitchedByIgnition" SG_ 1655 KL_Charisma_Anzeige_Umschaltung 0;
BA_ "GenSigSendType" SG_ 1655 KL_Charisma_Anzeige_Umschaltung 0;
BA_ "GenSigSwitchedByIgnition" SG_ 1655 KL_Segeln_Anf_deaktivieren 0;
BA_ "GenSigSendType" SG_ 1655 KL_Segeln_Anf_deaktivieren 3;
BA_ "GenSigSwitchedByIgnition" SG_ 1655 KL_T_HDC 0;
BA_ "GenSigSendType" SG_ 1655 KL_T_HDC 3;
BA_ "GenSigSwitchedByIgnition" SG_ 1655 HYB_Anf_E_Mode 0;
BA_ "GenSigSendType" SG_ 1655 HYB_Anf_E_Mode 3;
BA_ "GenSigSwitchedByIgnition" SG_ 1655 FSM_Status 0;
BA_ "GenSigSendType" SG_ 1655 FSM_Status 3;
BA_ "GenSigSwitchedByIgnition" SG_ 1655 KL_Niv_up 0;
BA_ "GenSigSendType" SG_ 1655 KL_Niv_up 3;
BA_ "GenSigSwitchedByIgnition" SG_ 1655 KL_Niv_down 0;
BA_ "GenSigSendType" SG_ 1655 KL_Niv_down 3;
BA_ "GenSigSwitchedByIgnition" SG_ 1655 KL_T_PASM_3 0;
BA_ "GenSigSendType" SG_ 1655 KL_T_PASM_3 3;
BA_ "GenSigSwitchedByIgnition" SG_ 1655 KL_T_VD 0;
BA_ "GenSigSendType" SG_ 1655 KL_T_VD 3;
BA_ "GenSigSwitchedByIgnition" SG_ 1655 KL_T_Windschott 0;
BA_ "GenSigSendType" SG_ 1655 KL_T_Windschott 3;
BA_ "GenSigSwitchedByIgnition" SG_ 1655 KL_St_Atemp 0;
BA_ "GenSigSendType" SG_ 1655 KL_St_Atemp 0;
BA_ "GenSigSwitchedByIgnition" SG_ 1655 Statusbit_Offroad_aktiv 0;
BA_ "NWM-WakeupAllowed" SG_ 1655 Statusbit_Offroad_aktiv 1;
BA_ "GenSigSendType" SG_ 1655 Statusbit_Offroad_aktiv 0;
BA_ "GenSigSwitchedByIgnition" SG_ 1655 KL_T_StSt_deaktiv 0;
BA_ "GenSigSendType" SG_ 1655 KL_T_StSt_deaktiv 3;
BA_ "GenSigSwitchedByIgnition" SG_ 1655 KL_T_LDW 0;
BA_ "GenSigSendType" SG_ 1655 KL_T_LDW 3;
BA_ "Fehlerwert" SG_ 1655 KL_Atemp_ungef 255;
BA_ "GenSigSwitchedByIgnition" SG_ 1655 KL_Atemp_ungef 0;
BA_ "NWM-WakeupAllowed" SG_ 1655 KL_Atemp_ungef 1;
BA_ "GenSigSendType" SG_ 1655 KL_Atemp_ungef 0;
BA_ "GenSigSwitchedByIgnition" SG_ 1656 Schalter_MD1Vorne_Vorwahl_3 0;
BA_ "GenSigSendType" SG_ 1656 Schalter_MD1Vorne_Vorwahl_3 4;
BA_ "GenSigActiveRepetitions" SG_ 1656 Schalter_MD1Vorne_Vorwahl_3 3;
BA_ "GenSigSwitchedByIgnition" SG_ 1656 Schalter_MD1Vorne_Fehler_3 0;
BA_ "GenSigSendType" SG_ 1656 Schalter_MD1Vorne_Fehler_3 4;
BA_ "GenSigActiveRepetitions" SG_ 1656 Schalter_MD1Vorne_Fehler_3 3;
BA_ "GenSigSwitchedByIgnition" SG_ 1656 Schalter_MRolloVorne_zu_3 0;
BA_ "GenSigSendType" SG_ 1656 Schalter_MRolloVorne_zu_3 4;
BA_ "GenSigActiveRepetitions" SG_ 1656 Schalter_MRolloVorne_zu_3 3;
BA_ "GenSigSwitchedByIgnition" SG_ 1656 Schalter_MRolloVorne_Fehler_3 0;
BA_ "GenSigSendType" SG_ 1656 Schalter_MRolloVorne_Fehler_3 4;
BA_ "GenSigActiveRepetitions" SG_ 1656 Schalter_MRolloVorne_Fehler_3 3;
BA_ "GenSigSwitchedByIgnition" SG_ 1656 Schalter_MRolloVorne_auf_3 0;
BA_ "GenSigSendType" SG_ 1656 Schalter_MRolloVorne_auf_3 4;
BA_ "GenSigActiveRepetitions" SG_ 1656 Schalter_MRolloVorne_auf_3 3;
BA_ "GenSigSwitchedByIgnition" SG_ 1656 Schalter_MRolloHinten_zu_3 0;
BA_ "GenSigSendType" SG_ 1656 Schalter_MRolloHinten_zu_3 4;
BA_ "GenSigActiveRepetitions" SG_ 1656 Schalter_MRolloHinten_zu_3 3;
BA_ "GenSigSwitchedByIgnition" SG_ 1656 Schalter_MRolloHinten_Fehler_3 0;
BA_ "GenSigSendType" SG_ 1656 Schalter_MRolloHinten_Fehler_3 4;
BA_ "GenSigActiveRepetitions" SG_ 1656 Schalter_MRolloHinten_Fehler_3 3;
BA_ "GenSigSwitchedByIgnition" SG_ 1656 Schalter_MRolloHinten_auf_3 0;
BA_ "GenSigSendType" SG_ 1656 Schalter_MRolloHinten_auf_3 4;
BA_ "GenSigActiveRepetitions" SG_ 1656 Schalter_MRolloHinten_auf_3 3;
BA_ "GenSigSwitchedByIgnition" SG_ 1656 DK_T_Multi_1 0;
BA_ "NWM-WakeupAllowed" SG_ 1656 DK_T_Multi_1 1;
BA_ "GenSigSendType" SG_ 1656 DK_T_Multi_1 4;
BA_ "GenSigActiveRepetitions" SG_ 1656 DK_T_Multi_1 3;
BA_ "GenSigMissingSourceValue" SG_ 1656 DK_F_T_Multi_1 1;
BA_ "GenSigSwitchedByIgnition" SG_ 1656 DK_F_T_Multi_1 0;
BA_ "NWM-WakeupAllowed" SG_ 1656 DK_F_T_Multi_1 1;
BA_ "GenSigSendType" SG_ 1656 DK_F_T_Multi_1 4;
BA_ "GenSigActiveRepetitions" SG_ 1656 DK_F_T_Multi_1 3;
BA_ "GenSigSwitchedByIgnition" SG_ 895 KL_AC_LED_an 0;
BA_ "NWM-WakeupAllowed" SG_ 895 KL_AC_LED_an 1;
BA_ "GenSigSendType" SG_ 895 KL_AC_LED_an 0;
BA_ "GenSigSwitchedByIgnition" SG_ 895 KL_ACmax_LED_an 0;
BA_ "NWM-WakeupAllowed" SG_ 895 KL_ACmax_LED_an 1;
BA_ "GenSigSendType" SG_ 895 KL_ACmax_LED_an 0;
BA_ "GenSigSwitchedByIgnition" SG_ 895 KL_LVT_O_LED_an 0;
BA_ "NWM-WakeupAllowed" SG_ 895 KL_LVT_O_LED_an 1;
BA_ "GenSigSendType" SG_ 895 KL_LVT_O_LED_an 0;
BA_ "GenSigSwitchedByIgnition" SG_ 895 KL_LVT_M_LED_an 0;
BA_ "NWM-WakeupAllowed" SG_ 895 KL_LVT_M_LED_an 1;
BA_ "GenSigSendType" SG_ 895 KL_LVT_M_LED_an 0;
BA_ "GenSigSwitchedByIgnition" SG_ 895 KL_LVT_U_LED_an 0;
BA_ "NWM-WakeupAllowed" SG_ 895 KL_LVT_U_LED_an 1;
BA_ "GenSigSendType" SG_ 895 KL_LVT_U_LED_an 0;
BA_ "GenSigSwitchedByIgnition" SG_ 895 KL_Umluft_LED_an 0;
BA_ "NWM-WakeupAllowed" SG_ 895 KL_Umluft_LED_an 1;
BA_ "GenSigSendType" SG_ 895 KL_Umluft_LED_an 0;
BA_ "GenSigSwitchedByIgnition" SG_ 895 KL_Auto_LED_an 0;
BA_ "NWM-WakeupAllowed" SG_ 895 KL_Auto_LED_an 1;
BA_ "Fehlerwert" SG_ 1483 KL_WunschStrom_HV 255;
BA_ "GenSigSwitchedByIgnition" SG_ 1483 KL_WunschStrom_HV 0;
BA_ "GenSigStartValue" SG_ 1483 KL_WunschStrom_HV 254;
BA_ "GenSigSendType" SG_ 1483 KL_WunschStrom_HV 0;
BA_ "Fehlerwert" SG_ 1483 KL_BattKond_WaPu_DZMax 63;
BA_ "GenSigSwitchedByIgnition" SG_ 1483 KL_BattKond_WaPu_DZMax 0;
BA_ "GenSigStartValue" SG_ 1483 KL_BattKond_WaPu_DZMax 62;
BA_ "GenSigSendType" SG_ 1483 KL_BattKond_WaPu_DZMax 0;
BA_ "GenSigSwitchedByIgnition" SG_ 1483 KBT_Defrost_aktiv 0;
BA_ "GenSigSendType" SG_ 1483 KBT_Defrost_aktiv 0;
BA_ "GenSigSwitchedByIgnition" SG_ 1483 KL_T_Charge 0;
BA_ "GenSigSendType" SG_ 1483 KL_T_Charge 3;
BA_ "GenSigSwitchedByIgnition" SG_ 1483 KL_Standklima_Status 0;
BA_ "GenSigSendType" SG_ 1483 KL_Standklima_Status 0;
BA_ "GenSigSwitchedByIgnition" SG_ 1483 PTC_Wasserauslasstemp 0;
BA_ "GenSigStartValue" SG_ 1483 PTC_Wasserauslasstemp 254;
BA_ "GenSigSendType" SG_ 1483 PTC_Wasserauslasstemp 0;
BA_ "GenSigSwitchedByIgnition" SG_ 1483 PTC_Wassereinlasstemp 0;
BA_ "GenSigStartValue" SG_ 1483 PTC_Wassereinlasstemp 254;
BA_ "GenSigSendType" SG_ 1483 PTC_Wassereinlasstemp 0;
BA_ "GenSigSwitchedByIgnition" SG_ 1483 PTC_HV_I_ist 0;
BA_ "GenSigStartValue" SG_ 1483 PTC_HV_I_ist 254;
BA_ "GenSigSendType" SG_ 1483 PTC_HV_I_ist 0;
BA_ "GenSigSwitchedByIgnition" SG_ 1532 KL_Autobetrieb_HL 0;
BA_ "GenSigSendType" SG_ 1532 KL_Autobetrieb_HL 0;
BA_ "GenSigSwitchedByIgnition" SG_ 1532 KL_Autobetrieb_HR 0;
BA_ "GenSigSendType" SG_ 1532 KL_Autobetrieb_HR 0;
BA_ "GenSigSwitchedByIgnition" SG_ 1532 KL_Autobetrieb_VL 0;
BA_ "GenSigSendType" SG_ 1532 KL_Autobetrieb_VL 0;
BA_ "GenSigSwitchedByIgnition" SG_ 1532 KL_Autobetrieb_VR 0;
BA_ "GenSigSendType" SG_ 1532 KL_Autobetrieb_VR 0;
BA_ "Fehlerwert" SG_ 1532 KL_Zieltemperatur_HL 31;
BA_ "GenSigSwitchedByIgnition" SG_ 1532 KL_Zieltemperatur_HL 0;
BA_ "GenSigStartValue" SG_ 1532 KL_Zieltemperatur_HL 30;
BA_ "GenSigSendType" SG_ 1532 KL_Zieltemperatur_HL 0;
BA_ "Fehlerwert" SG_ 1532 KL_Zieltemperatur_HR 31;
BA_ "GenSigSwitchedByIgnition" SG_ 1532 KL_Zieltemperatur_HR 0;
BA_ "GenSigStartValue" SG_ 1532 KL_Zieltemperatur_HR 30;
BA_ "GenSigSendType" SG_ 1532 KL_Zieltemperatur_HR 0;
BA_ "Fehlerwert" SG_ 1532 KL_Zieltemperatur_VL 31;
BA_ "GenSigSwitchedByIgnition" SG_ 1532 KL_Zieltemperatur_VL 0;
BA_ "GenSigStartValue" SG_ 1532 KL_Zieltemperatur_VL 30;
BA_ "GenSigSendType" SG_ 1532 KL_Zieltemperatur_VL 0;
BA_ "Fehlerwert" SG_ 1532 KL_Zieltemperatur_VR 31;
BA_ "GenSigSwitchedByIgnition" SG_ 1532 KL_Zieltemperatur_VR 0;
BA_ "GenSigStartValue" SG_ 1532 KL_Zieltemperatur_VR 30;
BA_ "GenSigSendType" SG_ 1532 KL_Zieltemperatur_VR 0;
BA_ "GenSigMissingSourceValue" SG_ 1712 FS_Taupunkt 1023;
BA_ "Fehlerwert" SG_ 1712 FS_Taupunkt 1023;
BA_ "GenSigSendType" SG_ 1712 FS_Taupunkt 0;
BA_ "GenSigSendType" SG_ 1712 FS_ResponseError 0;
BA_ "GenSigMissingSourceValue" SG_ 1712 FS_Temp_Scheibe 1023;
BA_ "Fehlerwert" SG_ 1712 FS_Temp_Scheibe 1023;
BA_ "GenSigSendType" SG_ 1712 FS_Temp_Scheibe 0;
BA_ "GenSigMissingSourceValue" SG_ 1712 FS_Temp_Sensor 255;
BA_ "Fehlerwert" SG_ 1712 FS_Temp_Sensor 255;
BA_ "GenSigSendType" SG_ 1712 FS_Temp_Sensor 0;
BA_ "GenSigMissingSourceValue" SG_ 1712 FS_Luftfeuchte_rel 255;
BA_ "Fehlerwert" SG_ 1712 FS_Luftfeuchte_rel 255;
BA_ "GenSigSendType" SG_ 1712 FS_Luftfeuchte_rel 0;
BA_ "GenSigSendType" SG_ 1625 EKL_KD_Fehler 0;
BA_ "GenSigSendType" SG_ 1625 EKL_Comp_SCI_com_stat 0;
BA_ "GenSigSendType" SG_ 1625 EKL_Comp_output_stat 0;
BA_ "GenSigSendType" SG_ 1625 EKL_Comp_main_stat 0;
BA_ "GenSigSendType" SG_ 1625 EKL_Comp_ovld_stat 0;
BA_ "GenSigSendType" SG_ 1625 EKL_Comp_Inv_stat 0;
BA_ "GenSigSendType" SG_ 1625 EKL_Comp_photo_temp_stat 0;
BA_ "Fehlerwert" SG_ 1625 EKL_Comp_photo_temp 255;
BA_ "GenSigStartValue" SG_ 1625 EKL_Comp_photo_temp 255;
BA_ "GenSigSendType" SG_ 1625 EKL_Comp_photo_temp 0;
BA_ "GenSigStartValue" SG_ 1625 EKL_Comp_current 255;
BA_ "GenSigSendType" SG_ 1625 EKL_Comp_current 0;
BA_ "Fehlerwert" SG_ 1625 EKL_Comp_rev_stat 255;
BA_ "GenSigSendType" SG_ 1625 EKL_Comp_rev_stat 0;
BA_ "GenSigSwitchedByIgnition" SG_ 779 KBI_ABS_Lampe 0;
BA_ "GenSigSendType" SG_ 779 KBI_ABS_Lampe 0;
BA_ "GenSigSwitchedByIgnition" SG_ 779 KBI_ESP_Lampe 0;
BA_ "GenSigSendType" SG_ 779 KBI_ESP_Lampe 0;
BA_ "GenSigSwitchedByIgnition" SG_ 779 KBI_BKL_Lampe 0;
BA_ "GenSigSendType" SG_ 779 KBI_BKL_Lampe 0;
BA_ "GenSigSwitchedByIgnition" SG_ 779 KBI_Airbag_Lampe 0;
BA_ "GenSigSendType" SG_ 779 KBI_Airbag_Lampe 0;
BA_ "GenSigSwitchedByIgnition" SG_ 779 KBI_SILA_gueltig 0;
BA_ "GenSigSendType" SG_ 779 KBI_SILA_gueltig 0;
BA_ "GenSigSwitchedByIgnition" SG_ 779 KBI_Lenkung_Lampe 0;
BA_ "GenSigSendType" SG_ 779 KBI_Lenkung_Lampe 0;
BA_ "GenSigSwitchedByIgnition" SG_ 779 KBI_Vorglueh_System_Lampe 0;
BA_ "GenSigSendType" SG_ 779 KBI_Vorglueh_System_Lampe 0;
BA_ "GenSigSwitchedByIgnition" SG_ 779 KBI_NV_in_Anzeige 0;
BA_ "GenSigSendType" SG_ 779 KBI_NV_in_Anzeige 0;
BA_ "GenSigSwitchedByIgnition" SG_ 779 Kombi_01_BZ 0;
BA_ "GenSigFuncType" SG_ 779 Kombi_01_BZ 1;
BA_ "GenSigSendType" SG_ 779 Kombi_01_BZ 0;
BA_ "GenSigSwitchedByIgnition" SG_ 779 KBI_Anzeigestatus_ACC 0;
BA_ "GenSigSendType" SG_ 779 KBI_Anzeigestatus_ACC 0;
BA_ "GenSigSwitchedByIgnition" SG_ 779 KBI_Oeldruck_Schalter 0;
BA_ "GenSigSendType" SG_ 779 KBI_Oeldruck_Schalter 0;
BA_ "GenSigSwitchedByIgnition" SG_ 779 KBI_Tankwarnung 0;
BA_ "GenSigSendType" SG_ 779 KBI_Tankwarnung 0;
BA_ "GenSigSwitchedByIgnition" SG_ 779 KBI_MFA_v_Einheit_01 0;
BA_ "GenSigSendType" SG_ 779 KBI_MFA_v_Einheit_01 0;
BA_ "GenSigSwitchedByIgnition" SG_ 779 KBI_im_Stellgliedtest 0;
BA_ "GenSigSendType" SG_ 779 KBI_im_Stellgliedtest 0;
BA_ "GenSigSwitchedByIgnition" SG_ 779 KBI_Anzeigefehler_LDW 0;
BA_ "GenSigSendType" SG_ 779 KBI_Anzeigefehler_LDW 0;
BA_ "GenSigSwitchedByIgnition" SG_ 779 KBI_Variante_USA 0;
BA_ "GenSigSendType" SG_ 779 KBI_Variante_USA 0;
BA_ "GenSigSwitchedByIgnition" SG_ 779 KBI_Oeldruckwarnung 0;
BA_ "GenSigSendType" SG_ 779 KBI_Oeldruckwarnung 0;
BA_ "GenSigSwitchedByIgnition" SG_ 779 KBI_Handbremse 0;
BA_ "GenSigSendType" SG_ 779 KBI_Handbremse 0;
BA_ "GenSigSwitchedByIgnition" SG_ 779 KBI_V_Digital 0;
BA_ "GenSigSendType" SG_ 779 KBI_V_Digital 0;
BA_ "GenSigSwitchedByIgnition" SG_ 779 KBI_PLA_in_Anzeige 0;
BA_ "GenSigSendType" SG_ 779 KBI_PLA_in_Anzeige 0;
BA_ "GenSigSwitchedByIgnition" SG_ 779 KBI_Anzeigefehler_NV 0;
BA_ "GenSigSendType" SG_ 779 KBI_Anzeigefehler_NV 0;
BA_ "GenSigSwitchedByIgnition" SG_ 779 KBI_angez_Geschw 0;
BA_ "GenSigSendType" SG_ 779 KBI_angez_Geschw 0;
BA_ "GenSigSwitchedByIgnition" SG_ 779 KBI_Einheit_Tacho 0;
BA_ "GenSigSendType" SG_ 779 KBI_Einheit_Tacho 0;
BA_ "GenSigSwitchedByIgnition" SG_ 779 KBI_Konsistenz_ACC 0;
BA_ "GenSigSendType" SG_ 779 KBI_Konsistenz_ACC 0;
BA_ "GenSigSwitchedByIgnition" SG_ 779 KBI_Fehler_Anzeige_ACC 0;
BA_ "GenSigSendType" SG_ 779 KBI_Fehler_Anzeige_ACC 0;
BA_ "GenSigSwitchedByIgnition" SG_ 779 KBI_Anzeigefehler_SWA 0;
BA_ "GenSigSendType" SG_ 779 KBI_Anzeigefehler_SWA 0;
BA_ "GenSigSwitchedByIgnition" SG_ 779 KBI_KD_Fehler 0;
BA_ "GenSigSendType" SG_ 779 KBI_KD_Fehler 0;
BA_ "Fehlerwert" SG_ 1719 KBI_Kilometerstand 1048575;
BA_ "GenSigSwitchedByIgnition" SG_ 1719 KBI_Kilometerstand 0;
BA_ "GenSigStartValue" SG_ 1719 KBI_Kilometerstand 1048574;
BA_ "GenSigSendType" SG_ 1719 KBI_Kilometerstand 0;
BA_ "GenSigSwitchedByIgnition" SG_ 1719 KBI_Standzeit 0;
BA_ "GenSigSendType" SG_ 1719 KBI_Standzeit 0;
BA_ "GenSigSwitchedByIgnition" SG_ 1719 KBI_Reset_Standzeit 0;
BA_ "GenSigSendType" SG_ 1719 KBI_Reset_Standzeit 0;
BA_ "Fehlerwert" SG_ 1719 KBI_Inhalt_Tank 127;
BA_ "GenSigSwitchedByIgnition" SG_ 1719 KBI_Inhalt_Tank 0;
BA_ "GenSigSendType" SG_ 1719 KBI_Inhalt_Tank 0;
BA_ "GenSigSwitchedByIgnition" SG_ 1719 KBI_FStatus_Tank 0;
BA_ "GenSigSendType" SG_ 1719 KBI_FStatus_Tank 0;
BA_ "GenSigSwitchedByIgnition" SG_ 1719 KBI_Oelwechsel_durchgefuehrt 0;
BA_ "GenSigSendType" SG_ 1719 KBI_Oelwechsel_durchgefuehrt 0;
BA_ "GenSigSwitchedByIgnition" SG_ 1719 KBI_QBit_Aussen_Temp_gef 0;
BA_ "GenSigStartValue" SG_ 1719 KBI_QBit_Aussen_Temp_gef 1;
BA_ "GenSigSendType" SG_ 1719 KBI_QBit_Aussen_Temp_gef 0;
BA_ "Fehlerwert" SG_ 1719 KBI_Aussen_Temp_gef 255;
BA_ "GenSigSwitchedByIgnition" SG_ 1719 KBI_Aussen_Temp_gef 0;
BA_ "GenSigStartValue" SG_ 1719 KBI_Aussen_Temp_gef 254;
BA_ "GenSigSendType" SG_ 1719 KBI_Aussen_Temp_gef 0;
BA_ "GenSigSwitchedByIgnition" SG_ 1720 KBI_Reifenumfang 0;
BA_ "GenSigFuncType" SG_ 1720 KBI_Reifenumfang 8;
BA_ "GenSigSendType" SG_ 1720 KBI_Reifenumfang 0;
BA_ "GenSigSwitchedByIgnition" SG_ 1720 KBI_BCmE_aktiv 0;
BA_ "GenSigSendType" SG_ 1720 KBI_BCmE_aktiv 0;
BA_ "GenSigSwitchedByIgnition" SG_ 1720 KBI_Sparhinweis_quittiert 0;
BA_ "GenSigSendType" SG_ 1720 KBI_Sparhinweis_quittiert 0;
BA_ "Fehlerwert" SG_ 1720 KBI_Tankfuellstand_Prozent 127;
BA_ "GenSigSwitchedByIgnition" SG_ 1720 KBI_Tankfuellstand_Prozent 0;
BA_ "GenSigStartValue" SG_ 1720 KBI_Tankfuellstand_Prozent 126;
BA_ "GenSigSendType" SG_ 1720 KBI_Tankfuellstand_Prozent 0;
BA_ "GenSigSwitchedByIgnition" SG_ 1720 KBI_Nachtanken_erkannt 0;
BA_ "GenSigSendType" SG_ 1720 KBI_Nachtanken_erkannt 0;
BA_ "Fehlerwert" SG_ 1720 KBI_Tankinhalt_hochaufl 16383;
BA_ "GenSigSwitchedByIgnition" SG_ 1720 KBI_Tankinhalt_hochaufl 0;
BA_ "GenSigStartValue" SG_ 1720 KBI_Tankinhalt_hochaufl 16382;
BA_ "GenSigSendType" SG_ 1720 KBI_Tankinhalt_hochaufl 0;
BA_ "GenSigSwitchedByIgnition" SG_ 1708 KBI_Reifenumfang 0;
BA_ "GenSigFuncType" SG_ 1708 KBI_Reifenumfang 8;
BA_ "GenSigSendType" SG_ 1708 KBI_Reifenumfang 0;
BA_ "GenSigSwitchedByIgnition" SG_ 1708 KBI_Reifenumfang_VA 0;
BA_ "GenSigSendType" SG_ 1708 KBI_Reifenumfang_VA 0;
BA_ "GenSigSwitchedByIgnition" SG_ 1708 KBI_Reifenumfang_HA 0;
BA_ "GenSigSendType" SG_ 1708 KBI_Reifenumfang_HA 0;
BA_ "GenSigSwitchedByIgnition" SG_ 1638 KBI_SDruck_VA_komfort 0;
BA_ "GenSigSendType" SG_ 1638 KBI_SDruck_VA_komfort 0;
BA_ "GenSigSwitchedByIgnition" SG_ 1638 KBI_SDruck_HA_komfort 0;
BA_ "GenSigSendType" SG_ 1638 KBI_SDruck_HA_komfort 0;
BA_ "GenSigSwitchedByIgnition" SG_ 1638 KBI_SDruck_VA_vmax 0;
BA_ "GenSigSendType" SG_ 1638 KBI_SDruck_VA_vmax 0;
BA_ "GenSigSwitchedByIgnition" SG_ 1638 KBI_SDruck_HA_vmax 0;
BA_ "GenSigSendType" SG_ 1638 KBI_SDruck_HA_vmax 0;
BA_ "GenSigSwitchedByIgnition" SG_ 1638 KBI_KomfortDruck 0;
BA_ "GenSigSendType" SG_ 1638 KBI_KomfortDruck 3;
BA_ "GenSigSwitchedByIgnition" SG_ 1638 KBI_RDK_Solldruck_neu 0;
BA_ "GenSigSendType" SG_ 1638 KBI_RDK_Solldruck_neu 3;
BA_ "GenSigSwitchedByIgnition" SG_ 1638 KBI_RDK_DDAnz_akt 0;
BA_ "GenSigSendType" SG_ 1638 KBI_RDK_DDAnz_akt 3;
BA_ "GenSigSwitchedByIgnition" SG_ 1638 KBI_RDK_Beladung_neu 0;
BA_ "GenSigSendType" SG_ 1638 KBI_RDK_Beladung_neu 3;
BA_ "GenSigSwitchedByIgnition" SG_ 1638 ActiveSafe_HMI_Vorwarnung 0;
BA_ "GenSigSendType" SG_ 1638 ActiveSafe_HMI_Vorwarnung 0;
BA_ "GenSigSwitchedByIgnition" SG_ 1638 ActiveSafe_HMI_FStatus 0;
BA_ "GenSigSendType" SG_ 1638 ActiveSafe_HMI_FStatus 0;
BA_ "GenSigSwitchedByIgnition" SG_ 1638 KBI_KomfortDruck_V_Warnschwelle 0;
BA_ "GenSigSendType" SG_ 1638 KBI_KomfortDruck_V_Warnschwelle 0;
BA_ "GenSigSwitchedByIgnition" SG_ 1638 KBI_Rundstreckenmodus 0;
BA_ "GenSigSendType" SG_ 1638 KBI_Rundstreckenmodus 3;
BA_ "GenSigSwitchedByIgnition" SG_ 1638 KBI_RS_Druck_uebernehmen 0;
BA_ "GenSigSendType" SG_ 1638 KBI_RS_Druck_uebernehmen 3;
BA_ "GenSigSwitchedByIgnition" SG_ 794 KBI_Weg_Zaehler_F 0;
BA_ "GenSigSendType" SG_ 794 KBI_Weg_Zaehler_F 0;
BA_ "GenSigSwitchedByIgnition" SG_ 794 KBI_Weg_Zaehler 0;
BA_ "GenSigSendType" SG_ 794 KBI_Weg_Zaehler 0;
BA_ "GenSigSwitchedByIgnition" SG_ 794 KBI_V_Anz 0;
BA_ "NWM-WakeupAllowed" SG_ 794 KBI_V_Anz 1;
BA_ "GenSigSendType" SG_ 794 KBI_V_Anz 0;
BA_ "GenSigSwitchedByIgnition" SG_ 794 KBI_TWSZ_Kombi 0;
BA_ "GenSigSendType" SG_ 794 KBI_TWSZ_Kombi 0;
BA_ "GenSigSwitchedByIgnition" SG_ 1725 KBI_Tankabgl_1 0;
BA_ "GenSigStartValue" SG_ 1725 KBI_Tankabgl_1 128;
BA_ "GenSigSendType" SG_ 1725 KBI_Tankabgl_1 0;
BA_ "GenSigSwitchedByIgnition" SG_ 1725 KBI_Tankabgl_2 0;
BA_ "GenSigStartValue" SG_ 1725 KBI_Tankabgl_2 128;
BA_ "GenSigSendType" SG_ 1725 KBI_Tankabgl_2 0;
BA_ "GenSigSwitchedByIgnition" SG_ 1725 KBI_Tankabgl_3 0;
BA_ "GenSigStartValue" SG_ 1725 KBI_Tankabgl_3 128;
BA_ "GenSigSendType" SG_ 1725 KBI_Tankabgl_3 0;
BA_ "GenSigMissingSourceValue" SG_ 1725 KBI_Fotosensor 255;
BA_ "Fehlerwert" SG_ 1725 KBI_Fotosensor 255;
BA_ "GenSigSwitchedByIgnition" SG_ 1725 KBI_Fotosensor 0;
BA_ "GenSigStartValue" SG_ 1725 KBI_Fotosensor 254;
BA_ "GenSigSendType" SG_ 1725 KBI_Fotosensor 0;
BA_ "Fehlerwert" SG_ 1725 KBI_KL58d 255;
BA_ "GenSigSwitchedByIgnition" SG_ 1725 KBI_KL58d 0;
BA_ "GenSigStartValue" SG_ 1725 KBI_KL58d 254;
BA_ "GenSigSendType" SG_ 1725 KBI_KL58d 0;
BA_ "Fehlerwert" SG_ 1725 KBI_KL58s 127;
BA_ "GenSigSwitchedByIgnition" SG_ 1725 KBI_KL58s 0;
BA_ "GenSigStartValue" SG_ 1725 KBI_KL58s 126;
BA_ "GenSigSendType" SG_ 1725 KBI_KL58s 3;
BA_ "GenSigSwitchedByIgnition" SG_ 1725 KBI_B_accscreen 0;
BA_ "NWM-WakeupAllowed" SG_ 1725 KBI_B_accscreen 1;
BA_ "GenSigSendType" SG_ 1725 KBI_B_accscreen 0;
BA_ "GenSigSwitchedByIgnition" SG_ 1725 KBI_Uebern 0;
BA_ "GenSigSendType" SG_ 1725 KBI_Uebern 0;
BA_ "GenSigSwitchedByIgnition" SG_ 1725 KBI_Uhr_Verstellung 0;
BA_ "GenSigSendType" SG_ 1725 KBI_Uhr_Verstellung 3;
BA_REL_ "GenSigTimeoutTime" BU_SG_REL_ Klima_PAG_PF SG_ 1516 FT_FH_Oeffnung 5000;
BA_REL_ "GenSigTimeoutTime" BU_SG_REL_ OCU_PAG_PF SG_ 1516 FT_FH_Oeffnung 5000;
BA_REL_ "GenSigTimeoutTime" BU_SG_REL_ Klima_PAG_PF SG_ 1516 BT_FH_Oeffnung 5000;
BA_REL_ "GenSigTimeoutTime" BU_SG_REL_ OCU_PAG_PF SG_ 1516 BT_FH_Oeffnung 5000;
BA_REL_ "GenSigTimeoutTime" BU_SG_REL_ ADR_PAG_X2 SG_ 1516 FT_Tuer_geoeffnet 5000;
BA_REL_ "GenSigTimeoutTime" BU_SG_REL_ Klima_PAG_PF SG_ 1516 FT_Tuer_geoeffnet 5000;
BA_REL_ "GenSigTimeoutTime" BU_SG_REL_ Kombi_PAG_PF SG_ 1516 FT_Tuer_geoeffnet 5000;
BA_REL_ "GenSigTimeoutTime" BU_SG_REL_ Klima_PAG_PF SG_ 1516 BT_Tuer_geoeffnet 5000;
BA_REL_ "GenSigTimeoutTime" BU_SG_REL_ Kombi_PAG_PF SG_ 1516 BT_Tuer_geoeffnet 5000;
BA_REL_ "GenSigTimeoutTime" BU_SG_REL_ Kombi_PAG_PF SG_ 1516 FT_verriegelt 5000;
BA_REL_ "GenSigTimeoutTime" BU_SG_REL_ Klima_PAG_PF SG_ 1516 FT_Kisi_li_aktiv 5000;
BA_REL_ "GenSigTimeoutTime" BU_SG_REL_ ADR_PAG_X2 SG_ 1516 F_TSG_FT_01_Mmi 5000;
BA_REL_ "GenSigTimeoutTime" BU_SG_REL_ Klima_PAG_PF SG_ 1516 F_TSG_FT_01_Mmi 5000;
BA_REL_ "GenSigTimeoutTime" BU_SG_REL_ Kombi_PAG_PF SG_ 1516 F_TSG_FT_01_Mmi 5000;
BA_REL_ "GenSigTimeoutTime" BU_SG_REL_ OCU_PAG_PF SG_ 1516 F_TSG_FT_01_Mmi 5000;
BA_REL_ "GenSigTimeoutTime" BU_SG_REL_ Klima_PAG_PF SG_ 1516 F_TSG_BT_01_Mmi 5000;
BA_REL_ "GenSigTimeoutTime" BU_SG_REL_ Kombi_PAG_PF SG_ 1516 F_TSG_BT_01_Mmi 5000;
BA_REL_ "GenSigTimeoutTime" BU_SG_REL_ OCU_PAG_PF SG_ 1516 F_TSG_BT_01_Mmi 5000;
BA_REL_ "GenSigTimeoutTime" BU_SG_REL_ Kombi_PAG_PF SG_ 797 BC_Up_Cursor 500;
BA_REL_ "GenSigTimeoutTime" BU_SG_REL_ Kombi_PAG_PF SG_ 797 BC_Down_Cursor 500;
BA_REL_ "GenSigTimeoutTime" BU_SG_REL_ Kombi_PAG_PF SG_ 797 BC_Set 500;
BA_REL_ "GenSigTimeoutTime" BU_SG_REL_ Kombi_PAG_PF SG_ 797 BC_Reset 500;
BA_REL_ "GenSigTimeoutTime" BU_SG_REL_ Klima_PAG_PF SG_ 797 WH_Intervall 500;
BA_REL_ "GenSigTimeoutTime" BU_SG_REL_ Klima_PAG_PF SG_ 797 F_SMLS_01_Mmi 500;
BA_REL_ "GenSigTimeoutTime" BU_SG_REL_ Kombi_PAG_PF SG_ 797 F_SMLS_01_Mmi 500;
BA_REL_ "GenSigTimeoutTime" BU_SG_REL_ Kombi_PAG_PF SG_ 797 F_LS_01_Mmi 500;
BA_REL_ "GenSigTimeoutTime" BU_SG_REL_ Kombi_PAG_PF SG_ 1092 ZV_HD_offen 500;
BA_REL_ "GenSigTimeoutTime" BU_SG_REL_ Klima_PAG_PF SG_ 1092 ZV_verriegelt_intern_ist 500;
BA_REL_ "GenSigTimeoutTime" BU_SG_REL_ ADR_PAG_X2 SG_ 1092 ZV_verriegelt_extern_ist 500;
BA_REL_ "GenSigTimeoutTime" BU_SG_REL_ Kombi_PAG_PF SG_ 1092 KST_Prio_Warn_05 500;
BA_REL_ "GenSigTimeoutTime" BU_SG_REL_ Kombi_PAG_PF SG_ 1092 KST_Prio_Warn_03 500;
BA_REL_ "GenSigTimeoutTime" BU_SG_REL_ Kombi_PAG_PF SG_ 1092 KST_Prio_Warn_04 500;
BA_REL_ "GenSigTimeoutTime" BU_SG_REL_ Kombi_PAG_PF SG_ 1092 KST_Warn_P1_ZST_def 500;
BA_REL_ "GenSigTimeoutTime" BU_SG_REL_ Kombi_PAG_PF SG_ 1092 KST_Warn_P2_ZST_def 500;
BA_REL_ "GenSigTimeoutTime" BU_SG_REL_ Kombi_PAG_PF SG_ 1092 STS_Texte 500;
BA_REL_ "GenSigTimeoutTime" BU_SG_REL_ ADR_PAG_X2 SG_ 1092 F_BCM2_02_Mmi 500;
BA_REL_ "GenSigTimeoutTime" BU_SG_REL_ Klima_PAG_PF SG_ 1092 F_BCM2_02_Mmi 500;
BA_REL_ "GenSigTimeoutTime" BU_SG_REL_ Kombi_PAG_PF SG_ 1092 F_BCM2_02_Mmi 500;
BA_REL_ "GenSigTimeoutTime" BU_SG_REL_ Kombi_PAG_PF SG_ 1092 F_STS_01_Mmi 500;
BA_REL_ "GenSigTimeoutTime" BU_SG_REL_ Kombi_PAG_PF SG_ 1315 SVB_SMLS 2500;
BA_REL_ "GenSigTimeoutTime" BU_SG_REL_ Kombi_PAG_PF SG_ 1315 SVB_Lift 2500;
BA_REL_ "GenSigTimeoutTime" BU_SG_REL_ Kombi_PAG_PF SG_ 1315 SVB_TSG_FT 2500;
BA_REL_ "GenSigTimeoutTime" BU_SG_REL_ Kombi_PAG_PF SG_ 1315 SVB_TSG_BT 2500;
BA_REL_ "GenSigTimeoutTime" BU_SG_REL_ Kombi_PAG_PF SG_ 1315 SVB_RDK 2500;
BA_REL_ "GenSigTimeoutTime" BU_SG_REL_ Kombi_PAG_PF SG_ 1315 SVB_BCM1 2500;
BA_REL_ "GenSigTimeoutTime" BU_SG_REL_ Kombi_PAG_PF SG_ 1315 SVB_BCM2 2500;
BA_REL_ "GenSigTimeoutTime" BU_SG_REL_ Kombi_PAG_PF SG_ 1315 SVB_BKE 2500;
BA_REL_ "GenSigTimeoutTime" BU_SG_REL_ Kombi_PAG_PF SG_ 1315 SVB_PCM 2500;
BA_REL_ "GenSigTimeoutTime" BU_SG_REL_ Kombi_PAG_PF SG_ 1315 SVB_Motor 2500;
BA_REL_ "GenSigTimeoutTime" BU_SG_REL_ Kombi_PAG_PF SG_ 1315 SVB_QSP 2500;
BA_REL_ "GenSigTimeoutTime" BU_SG_REL_ Kombi_PAG_PF SG_ 1315 SVB_Getriebe 2500;
BA_REL_ "GenSigTimeoutTime" BU_SG_REL_ Kombi_PAG_PF SG_ 1315 SVB_Airbag 2500;
BA_REL_ "GenSigTimeoutTime" BU_SG_REL_ Kombi_PAG_PF SG_ 1315 SVB_PSM_Fwk 2500;
BA_REL_ "GenSigTimeoutTime" BU_SG_REL_ Kombi_PAG_PF SG_ 1315 SVB_EPB 2500;
BA_REL_ "GenSigTimeoutTime" BU_SG_REL_ Kombi_PAG_PF SG_ 1315 SVB_PDCC 2500;
BA_REL_ "GenSigTimeoutTime" BU_SG_REL_ Kombi_PAG_PF SG_ 1315 SVB_PASM_NRA 2500;
BA_REL_ "GenSigTimeoutTime" BU_SG_REL_ Kombi_PAG_PF SG_ 1315 SVB_EPS 2500;
BA_REL_ "GenSigTimeoutTime" BU_SG_REL_ Kombi_PAG_PF SG_ 1315 SVB_HAL 2500;
BA_REL_ "GenSigTimeoutTime" BU_SG_REL_ Kombi_PAG_PF SG_ 1315 SVB_AFS 2500;
BA_REL_ "GenSigTimeoutTime" BU_SG_REL_ ADR_PAG_X2 SG_ 1428 HVLM_Restladezeit_HV_Bat_02 5000;
BA_REL_ "GenSigTimeoutTime" BU_SG_REL_ Kombi_PAG_PF SG_ 1428 HVLM_Restladezeit_HV_Bat_02 5000;
BA_REL_ "GenSigTimeoutTime" BU_SG_REL_ ADR_PAG_X2 SG_ 1428 HVLM_Lademodus_HV_Bat 5000;
BA_REL_ "GenSigTimeoutTime" BU_SG_REL_ Kombi_PAG_PF SG_ 1428 HVLM_Lademodus_HV_Bat 5000;
BA_REL_ "GenSigTimeoutTime" BU_SG_REL_ ADR_PAG_X2 SG_ 1428 HVLM_Bat_laden_aktiv 5000;
BA_REL_ "GenSigTimeoutTime" BU_SG_REL_ Kombi_PAG_PF SG_ 1428 HVLM_Bat_laden_aktiv 5000;
BA_REL_ "GenSigTimeoutTime" BU_SG_REL_ ADR_PAG_X2 SG_ 1428 HVLM_Ladeart 5000;
BA_REL_ "GenSigTimeoutTime" BU_SG_REL_ Kombi_PAG_PF SG_ 1428 HVLM_Ladeart 5000;
BA_REL_ "GenSigTimeoutTime" BU_SG_REL_ Klima_PAG_PF SG_ 1428 HVLM_VK_Anf 5000;
BA_REL_ "GenSigTimeoutTime" BU_SG_REL_ Kombi_PAG_PF SG_ 1428 HVLM_Ladesystemhinweise 5000;
BA_REL_ "GenSigTimeoutTime" BU_SG_REL_ ADR_PAG_X2 SG_ 1428 HVLM_Stecker_Status 5000;
BA_REL_ "GenSigTimeoutTime" BU_SG_REL_ Kombi_PAG_PF SG_ 1428 HVLM_Stecker_Status 5000;
BA_REL_ "GenSigTimeoutTime" BU_SG_REL_ ADR_PAG_X2 SG_ 1397 HVLM_Status_Timer_MUX 5000;
BA_REL_ "GenSigTimeoutTime" BU_SG_REL_ ADR_PAG_X2 SG_ 1397 HVLM_Status_Timer_1_Jahr 5000;
BA_REL_ "GenSigTimeoutTime" BU_SG_REL_ ADR_PAG_X2 SG_ 1397 HVLM_Status_Timer_2_Jahr 5000;
BA_REL_ "GenSigTimeoutTime" BU_SG_REL_ ADR_PAG_X2 SG_ 1397 HVLM_Status_Timer_3_Jahr 5000;
BA_REL_ "GenSigTimeoutTime" BU_SG_REL_ ADR_PAG_X2 SG_ 1397 HVLM_Status_Timer_4_Jahr 5000;
BA_REL_ "GenSigTimeoutTime" BU_SG_REL_ ADR_PAG_X2 SG_ 1397 HVLM_Status_Timer_7_Jahr 5000;
BA_REL_ "GenSigTimeoutTime" BU_SG_REL_ ADR_PAG_X2 SG_ 1397 HVLM_Status_Timer_1_Minute 5000;
BA_REL_ "GenSigTimeoutTime" BU_SG_REL_ ADR_PAG_X2 SG_ 1397 HVLM_Status_Timer_2_Minute 5000;
BA_REL_ "GenSigTimeoutTime" BU_SG_REL_ ADR_PAG_X2 SG_ 1397 HVLM_Status_Timer_3_Minute 5000;
BA_REL_ "GenSigTimeoutTime" BU_SG_REL_ ADR_PAG_X2 SG_ 1397 HVLM_Status_Timer_4_Minute 5000;
BA_REL_ "GenSigTimeoutTime" BU_SG_REL_ ADR_PAG_X2 SG_ 1397 HVLM_Status_Timer_7_Minute 5000;
BA_REL_ "GenSigTimeoutTime" BU_SG_REL_ ADR_PAG_X2 SG_ 1397 HVLM_Status_Timer_1_Monat 5000;
BA_REL_ "GenSigTimeoutTime" BU_SG_REL_ ADR_PAG_X2 SG_ 1397 HVLM_Status_Timer_2_Monat 5000;
BA_REL_ "GenSigTimeoutTime" BU_SG_REL_ ADR_PAG_X2 SG_ 1397 HVLM_Status_Timer_3_Monat 5000;
BA_REL_ "GenSigTimeoutTime" BU_SG_REL_ ADR_PAG_X2 SG_ 1397 HVLM_Status_Timer_4_Monat 5000;
BA_REL_ "GenSigTimeoutTime" BU_SG_REL_ ADR_PAG_X2 SG_ 1397 HVLM_Status_Timer_7_Monat 5000;
BA_REL_ "GenSigTimeoutTime" BU_SG_REL_ ADR_PAG_X2 SG_ 1397 HVLM_Status_Timer_1_Stunde 5000;
BA_REL_ "GenSigTimeoutTime" BU_SG_REL_ ADR_PAG_X2 SG_ 1397 HVLM_Status_Timer_2_Stunde 5000;
BA_REL_ "GenSigTimeoutTime" BU_SG_REL_ ADR_PAG_X2 SG_ 1397 HVLM_Status_Timer_3_Stunde 5000;
BA_REL_ "GenSigTimeoutTime" BU_SG_REL_ ADR_PAG_X2 SG_ 1397 HVLM_Status_Timer_4_Stunde 5000;
BA_REL_ "GenSigTimeoutTime" BU_SG_REL_ ADR_PAG_X2 SG_ 1397 HVLM_Status_Timer_7_Stunde 5000;
BA_REL_ "GenSigTimeoutTime" BU_SG_REL_ ADR_PAG_X2 SG_ 1397 HVLM_Status_Timer_1_Tag 5000;
BA_REL_ "GenSigTimeoutTime" BU_SG_REL_ ADR_PAG_X2 SG_ 1397 HVLM_Status_Timer_2_Tag 5000;
BA_REL_ "GenSigTimeoutTime" BU_SG_REL_ ADR_PAG_X2 SG_ 1397 HVLM_Status_Timer_3_Tag 5000;
BA_REL_ "GenSigTimeoutTime" BU_SG_REL_ ADR_PAG_X2 SG_ 1397 HVLM_Status_Timer_4_Tag 5000;
BA_REL_ "GenSigTimeoutTime" BU_SG_REL_ ADR_PAG_X2 SG_ 1397 HVLM_Status_Timer_7_Tag 5000;
BA_REL_ "GenSigTimeoutTime" BU_SG_REL_ ADR_PAG_X2 SG_ 1397 HVLM_Status_Timer_1_Laden 5000;
BA_REL_ "GenSigTimeoutTime" BU_SG_REL_ ADR_PAG_X2 SG_ 1397 HVLM_Status_Timer_2_Laden 5000;
BA_REL_ "GenSigTimeoutTime" BU_SG_REL_ ADR_PAG_X2 SG_ 1397 HVLM_Status_Timer_3_Laden 5000;
BA_REL_ "GenSigTimeoutTime" BU_SG_REL_ ADR_PAG_X2 SG_ 1397 HVLM_Status_Timer_4_Laden 5000;
BA_REL_ "GenSigTimeoutTime" BU_SG_REL_ ADR_PAG_X2 SG_ 1397 HVLM_Status_Timer_1_Vorklima 5000;
BA_REL_ "GenSigTimeoutTime" BU_SG_REL_ ADR_PAG_X2 SG_ 1397 HVLM_Status_Timer_2_Vorklima 5000;
BA_REL_ "GenSigTimeoutTime" BU_SG_REL_ ADR_PAG_X2 SG_ 1397 HVLM_Status_Timer_3_Vorklima 5000;
BA_REL_ "GenSigTimeoutTime" BU_SG_REL_ ADR_PAG_X2 SG_ 1397 HVLM_Status_Timer_4_Vorklima 5000;
BA_REL_ "GenSigTimeoutTime" BU_SG_REL_ ADR_PAG_X2 SG_ 1397 HVLM_Status_Timer_1_Zyklus_Mo 5000;
BA_REL_ "GenSigTimeoutTime" BU_SG_REL_ ADR_PAG_X2 SG_ 1397 HVLM_Status_Timer_2_Zyklus_Mo 5000;
BA_REL_ "GenSigTimeoutTime" BU_SG_REL_ ADR_PAG_X2 SG_ 1397 HVLM_Status_Timer_3_Zyklus_Mo 5000;
BA_REL_ "GenSigTimeoutTime" BU_SG_REL_ ADR_PAG_X2 SG_ 1397 HVLM_Status_Timer_4_Zyklus_Mo 5000;
BA_REL_ "GenSigTimeoutTime" BU_SG_REL_ ADR_PAG_X2 SG_ 1397 HVLM_Status_Timer_1_Zyklus_Di 5000;
BA_REL_ "GenSigTimeoutTime" BU_SG_REL_ ADR_PAG_X2 SG_ 1397 HVLM_Status_Timer_2_Zyklus_Di 5000;
BA_REL_ "GenSigTimeoutTime" BU_SG_REL_ ADR_PAG_X2 SG_ 1397 HVLM_Status_Timer_3_Zyklus_Di 5000;
BA_REL_ "GenSigTimeoutTime" BU_SG_REL_ ADR_PAG_X2 SG_ 1397 HVLM_Status_Timer_4_Zyklus_Di 5000;
BA_REL_ "GenSigTimeoutTime" BU_SG_REL_ ADR_PAG_X2 SG_ 1397 HVLM_Status_Timer_1_Zyklus_Mi 5000;
BA_REL_ "GenSigTimeoutTime" BU_SG_REL_ ADR_PAG_X2 SG_ 1397 HVLM_Status_Timer_2_Zyklus_Mi 5000;
BA_REL_ "GenSigTimeoutTime" BU_SG_REL_ ADR_PAG_X2 SG_ 1397 HVLM_Status_Timer_3_Zyklus_Mi 5000;
BA_REL_ "GenSigTimeoutTime" BU_SG_REL_ ADR_PAG_X2 SG_ 1397 HVLM_Status_Timer_4_Zyklus_Mi 5000;
BA_REL_ "GenSigTimeoutTime" BU_SG_REL_ ADR_PAG_X2 SG_ 1397 HVLM_Status_Timer_1_Zyklus_Do 5000;
BA_REL_ "GenSigTimeoutTime" BU_SG_REL_ ADR_PAG_X2 SG_ 1397 HVLM_Status_Timer_2_Zyklus_Do 5000;
BA_REL_ "GenSigTimeoutTime" BU_SG_REL_ ADR_PAG_X2 SG_ 1397 HVLM_Status_Timer_3_Zyklus_Do 5000;
BA_REL_ "GenSigTimeoutTime" BU_SG_REL_ ADR_PAG_X2 SG_ 1397 HVLM_Status_Timer_4_Zyklus_Do 5000;
BA_REL_ "GenSigTimeoutTime" BU_SG_REL_ ADR_PAG_X2 SG_ 1397 HVLM_Status_Timer_1_Zyklus_Fr 5000;
BA_REL_ "GenSigTimeoutTime" BU_SG_REL_ ADR_PAG_X2 SG_ 1397 HVLM_Status_Timer_2_Zyklus_Fr 5000;
BA_REL_ "GenSigTimeoutTime" BU_SG_REL_ ADR_PAG_X2 SG_ 1397 HVLM_Status_Timer_3_Zyklus_Fr 5000;
BA_REL_ "GenSigTimeoutTime" BU_SG_REL_ ADR_PAG_X2 SG_ 1397 HVLM_Status_Timer_4_Zyklus_Fr 5000;
BA_REL_ "GenSigTimeoutTime" BU_SG_REL_ ADR_PAG_X2 SG_ 1397 HVLM_Status_Timer_1_Zyklus_Sa 5000;
BA_REL_ "GenSigTimeoutTime" BU_SG_REL_ ADR_PAG_X2 SG_ 1397 HVLM_Status_Timer_2_Zyklus_Sa 5000;
BA_REL_ "GenSigTimeoutTime" BU_SG_REL_ ADR_PAG_X2 SG_ 1397 HVLM_Status_Timer_3_Zyklus_Sa 5000;
BA_REL_ "GenSigTimeoutTime" BU_SG_REL_ ADR_PAG_X2 SG_ 1397 HVLM_Status_Timer_4_Zyklus_Sa 5000;
BA_REL_ "GenSigTimeoutTime" BU_SG_REL_ ADR_PAG_X2 SG_ 1397 HVLM_Status_Timer_1_Zyklus_So 5000;
BA_REL_ "GenSigTimeoutTime" BU_SG_REL_ ADR_PAG_X2 SG_ 1397 HVLM_Status_Timer_2_Zyklus_So 5000;
BA_REL_ "GenSigTimeoutTime" BU_SG_REL_ ADR_PAG_X2 SG_ 1397 HVLM_Status_Timer_3_Zyklus_So 5000;
BA_REL_ "GenSigTimeoutTime" BU_SG_REL_ ADR_PAG_X2 SG_ 1397 HVLM_Status_Timer_4_Zyklus_So 5000;
BA_REL_ "GenSigTimeoutTime" BU_SG_REL_ ADR_PAG_X2 SG_ 1397 HVLM_Status_Timer_1_Zyklus_WH 5000;
BA_REL_ "GenSigTimeoutTime" BU_SG_REL_ ADR_PAG_X2 SG_ 1397 HVLM_Status_Timer_2_Zyklus_WH 5000;
BA_REL_ "GenSigTimeoutTime" BU_SG_REL_ ADR_PAG_X2 SG_ 1397 HVLM_Status_Timer_3_Zyklus_WH 5000;
BA_REL_ "GenSigTimeoutTime" BU_SG_REL_ ADR_PAG_X2 SG_ 1397 HVLM_Status_Timer_4_Zyklus_WH 5000;
BA_REL_ "GenSigTimeoutTime" BU_SG_REL_ Klima_PAG_PF SG_ 1424 KY_Funkschl_Nr 2000;
BA_REL_ "GenSigTimeoutTime" BU_SG_REL_ Kombi_PAG_PF SG_ 1424 KY_Funkschl_Nr 2000;
BA_REL_ "GenSigTimeoutTime" BU_SG_REL_ Kombi_PAG_PF SG_ 1424 FBS_Warn_Lenkung_def 2000;
BA_REL_ "GenSigTimeoutTime" BU_SG_REL_ Kombi_PAG_PF SG_ 1424 FBS_Warn_LenkVerriegelung_def 2000;
BA_REL_ "GenSigTimeoutTime" BU_SG_REL_ Kombi_PAG_PF SG_ 1424 FBS_Warn_Schluessel_Batt 2000;
BA_REL_ "GenSigTimeoutTime" BU_SG_REL_ Kombi_PAG_PF SG_ 1424 FBS_Prio_Warn_04 2000;
BA_REL_ "GenSigTimeoutTime" BU_SG_REL_ Kombi_PAG_PF SG_ 1424 FBS_Prio_Warn_05 2000;
BA_REL_ "GenSigTimeoutTime" BU_SG_REL_ Kombi_PAG_PF SG_ 1424 KY_Schluessel_Soll 2000;
BA_REL_ "GenSigTimeoutTime" BU_SG_REL_ Kombi_PAG_PF SG_ 1424 KY_Schluessel_Ist 2000;
BA_REL_ "GenSigTimeoutTime" BU_SG_REL_ Kombi_PAG_PF SG_ 1424 KY_WFS_Safe 2000;
BA_REL_ "GenSigTimeoutTime" BU_SG_REL_ Kombi_PAG_PF SG_ 1424 KY_WFS_LZ 2000;
BA_REL_ "GenSigTimeoutTime" BU_SG_REL_ ADR_PAG_X2 SG_ 960 ZAS_Kl_S 1000;
BA_REL_ "GenSigTimeoutTime" BU_SG_REL_ Kombi_PAG_PF SG_ 960 ZAS_Kl_S 1000;
BA_REL_ "GenSigTimeoutTime" BU_SG_REL_ OCU_PAG_PF SG_ 960 ZAS_Kl_S 1000;
BA_REL_ "GenSigTimeoutTime" BU_SG_REL_ RDK_High_PAG_PF SG_ 960 ZAS_Kl_S 1000;
BA_REL_ "GenSigTimeoutTime" BU_SG_REL_ ADR_PAG_X2 SG_ 960 ZAS_Kl_15 1000;
BA_REL_ "GenSigTimeoutTime" BU_SG_REL_ Klima_PAG_PF SG_ 960 ZAS_Kl_15 1000;
BA_REL_ "GenSigTimeoutTime" BU_SG_REL_ Kombi_PAG_PF SG_ 960 ZAS_Kl_15 1000;
BA_REL_ "GenSigTimeoutTime" BU_SG_REL_ Miko_PAG_X2 SG_ 960 ZAS_Kl_15 1000;
BA_REL_ "GenSigTimeoutTime" BU_SG_REL_ OCU_PAG_PF SG_ 960 ZAS_Kl_15 1000;
BA_REL_ "GenSigTimeoutTime" BU_SG_REL_ RDK_High_PAG_PF SG_ 960 ZAS_Kl_15 1000;
BA_REL_ "GenSigTimeoutTime" BU_SG_REL_ OCU_PAG_PF SG_ 960 ZAS_Kl_X 1000;
BA_REL_ "GenSigTimeoutTime" BU_SG_REL_ Klima_PAG_PF SG_ 960 ZAS_Kl_50 1000;
BA_REL_ "GenSigTimeoutTime" BU_SG_REL_ Kombi_PAG_PF SG_ 960 ZAS_Kl_50 1000;
BA_REL_ "GenSigTimeoutTime" BU_SG_REL_ Miko_PAG_X2 SG_ 960 ZAS_Kl_50 1000;
BA_REL_ "GenSigTimeoutTime" BU_SG_REL_ RDK_High_PAG_PF SG_ 960 ZAS_Kl_50 1000;
BA_REL_ "GenSigTimeoutTime" BU_SG_REL_ GW_App_PAG_PF SG_ 959 KL_Handshake_BEM 1000;
BA_REL_ "GenSigTimeoutTime" BU_SG_REL_ GW_App_PAG_PF SG_ 959 KL_KD_Fehler 1000;
BA_REL_ "GenSigTimeoutTime" BU_SG_REL_ Klimakomp_Dash_PAG_PF SG_ 959 KL_Comp_rev_rq 1000;
BA_REL_ "GenSigTimeoutTime" BU_SG_REL_ Klimakomp_Dash_PAG_PF SG_ 959 KL_Comp_enable 1000;
BA_REL_ "GenSigTimeoutTime" BU_SG_REL_ GW_App_PAG_PF SG_ 1636 KL_Beschlagsgefahr 5000;
BA_REL_ "GenSigTimeoutTime" BU_SG_REL_ ADR_PAG_X2 SG_ 1636 KL_Geblaese_Status 5000;
BA_REL_ "GenSigTimeoutTime" BU_SG_REL_ GW_App_PAG_PF SG_ 1636 KL_Geblaese_Status 5000;
BA_REL_ "GenSigTimeoutTime" BU_SG_REL_ Kombi_PAG_PF SG_ 1636 KL_Geblaese_Status 5000;
BA_REL_ "GenSigTimeoutTime" BU_SG_REL_ GW_App_PAG_PF SG_ 1636 KL_I_Geblaese 5000;
BA_REL_ "GenSigTimeoutTime" BU_SG_REL_ OCU_PAG_PF SG_ 1646 KL_Innen_Temp 5000;
BA_REL_ "GenSigTimeoutTime" BU_SG_REL_ ADR_PAG_X2 SG_ 1646 KL_Sonnenintensitaet 5000;
BA_REL_ "GenSigTimeoutTime" BU_SG_REL_ Miko_PAG_X2 SG_ 1646 KL_Sonnenintensitaet 5000;
BA_REL_ "GenSigTimeoutTime" BU_SG_REL_ GW_App_PAG_PF SG_ 1655 KL_T_STH 5000;
BA_REL_ "GenSigTimeoutTime" BU_SG_REL_ GW_App_PAG_PF SG_ 1655 KL_Charisma_Anzeige 5000;
BA_REL_ "GenSigTimeoutTime" BU_SG_REL_ Kombi_PAG_PF SG_ 1655 KL_Charisma_Anzeige 5000;
BA_REL_ "GenSigTimeoutTime" BU_SG_REL_ Kombi_PAG_PF SG_ 1655 KL_Charisma_Anzeige_Umschaltung 5000;
BA_REL_ "GenSigTimeoutTime" BU_SG_REL_ Kombi_PAG_PF SG_ 1655 KL_Atemp_ungef 5000;
BA_REL_ "GenSigTimeoutTime" BU_SG_REL_ Miko_PAG_X2 SG_ 895 KL_AC_LED_an 1000;
BA_REL_ "GenSigTimeoutTime" BU_SG_REL_ Miko_PAG_X2 SG_ 895 KL_ACmax_LED_an 1000;
BA_REL_ "GenSigTimeoutTime" BU_SG_REL_ ADR_PAG_X2 SG_ 895 KL_LVT_O_LED_an 1000;
BA_REL_ "GenSigTimeoutTime" BU_SG_REL_ ADR_PAG_X2 SG_ 895 KL_LVT_M_LED_an 1000;
BA_REL_ "GenSigTimeoutTime" BU_SG_REL_ ADR_PAG_X2 SG_ 895 KL_LVT_U_LED_an 1000;
BA_REL_ "GenSigTimeoutTime" BU_SG_REL_ Miko_PAG_X2 SG_ 895 KL_Umluft_LED_an 1000;
BA_REL_ "GenSigTimeoutTime" BU_SG_REL_ Miko_PAG_X2 SG_ 895 KL_Auto_LED_an 1000;
BA_REL_ "GenSigTimeoutTime" BU_SG_REL_ GW_App_PAG_PF SG_ 1483 KL_WunschStrom_HV 5000;
BA_REL_ "GenSigTimeoutTime" BU_SG_REL_ GW_App_PAG_PF SG_ 1483 KBT_Defrost_aktiv 5000;
BA_REL_ "GenSigTimeoutTime" BU_SG_REL_ Miko_PAG_X2 SG_ 1483 KBT_Defrost_aktiv 5000;
BA_REL_ "GenSigTimeoutTime" BU_SG_REL_ GW_App_PAG_PF SG_ 1483 KL_Standklima_Status 5000;
BA_REL_ "GenSigTimeoutTime" BU_SG_REL_ GW_App_PAG_PF SG_ 1483 PTC_HV_I_ist 5000;
BA_REL_ "GenSigTimeoutTime" BU_SG_REL_ Klima_PAG_PF SG_ 1712 FS_Taupunkt 5000;
BA_REL_ "GenSigTimeoutTime" BU_SG_REL_ Klima_PAG_PF SG_ 1712 FS_Temp_Scheibe 5000;
BA_REL_ "GenSigTimeoutTime" BU_SG_REL_ Klima_PAG_PF SG_ 1712 FS_Temp_Sensor 5000;
BA_REL_ "GenSigTimeoutTime" BU_SG_REL_ Klima_PAG_PF SG_ 1712 FS_Luftfeuchte_rel 5000;
BA_REL_ "GenSigTimeoutTime" BU_SG_REL_ Klima_PAG_PF SG_ 1625 EKL_KD_Fehler 5000;
BA_REL_ "GenSigTimeoutTime" BU_SG_REL_ Klima_PAG_PF SG_ 1625 EKL_Comp_SCI_com_stat 5000;
BA_REL_ "GenSigTimeoutTime" BU_SG_REL_ Klima_PAG_PF SG_ 1625 EKL_Comp_output_stat 5000;
BA_REL_ "GenSigTimeoutTime" BU_SG_REL_ Klima_PAG_PF SG_ 1625 EKL_Comp_main_stat 5000;
BA_REL_ "GenSigTimeoutTime" BU_SG_REL_ Klima_PAG_PF SG_ 1625 EKL_Comp_ovld_stat 5000;
BA_REL_ "GenSigTimeoutTime" BU_SG_REL_ Klima_PAG_PF SG_ 1625 EKL_Comp_Inv_stat 5000;
BA_REL_ "GenSigTimeoutTime" BU_SG_REL_ Klima_PAG_PF SG_ 1625 EKL_Comp_photo_temp_stat 5000;
BA_REL_ "GenSigTimeoutTime" BU_SG_REL_ Klima_PAG_PF SG_ 1625 EKL_Comp_photo_temp 5000;
BA_REL_ "GenSigTimeoutTime" BU_SG_REL_ GW_App_PAG_PF SG_ 1625 EKL_Comp_current 5000;
BA_REL_ "GenSigTimeoutTime" BU_SG_REL_ Klima_PAG_PF SG_ 1625 EKL_Comp_current 5000;
BA_REL_ "GenSigTimeoutTime" BU_SG_REL_ Klima_PAG_PF SG_ 1625 EKL_Comp_rev_stat 5000;
BA_REL_ "GenSigTimeoutTime" BU_SG_REL_ OCU_PAG_PF SG_ 779 KBI_MFA_v_Einheit_01 500;
BA_REL_ "GenSigTimeoutTime" BU_SG_REL_ RDK_High_PAG_PF SG_ 779 KBI_MFA_v_Einheit_01 500;
BA_REL_ "GenSigTimeoutTime" BU_SG_REL_ RDK_High_PAG_PF SG_ 779 KBI_V_Digital 500;
BA_REL_ "GenSigTimeoutTime" BU_SG_REL_ OCU_PAG_PF SG_ 779 KBI_Einheit_Tacho 500;
BA_REL_ "GenSigTimeoutTime" BU_SG_REL_ GW_App_PAG_PF SG_ 779 KBI_KD_Fehler 500;
BA_REL_ "GenSigTimeoutTime" BU_SG_REL_ GW_App_PAG_PF SG_ 1719 KBI_Kilometerstand 5000;
BA_REL_ "GenSigTimeoutTime" BU_SG_REL_ OCU_PAG_PF SG_ 1719 KBI_Kilometerstand 5000;
BA_REL_ "GenSigTimeoutTime" BU_SG_REL_ Klima_PAG_PF SG_ 1719 KBI_Standzeit 5000;
BA_REL_ "GenSigTimeoutTime" BU_SG_REL_ OCU_PAG_PF SG_ 1719 KBI_Inhalt_Tank 5000;
BA_REL_ "GenSigTimeoutTime" BU_SG_REL_ ADR_PAG_X2 SG_ 1719 KBI_Aussen_Temp_gef 5000;
BA_REL_ "GenSigTimeoutTime" BU_SG_REL_ GW_App_PAG_PF SG_ 1719 KBI_Aussen_Temp_gef 5000;
BA_REL_ "GenSigTimeoutTime" BU_SG_REL_ Klima_PAG_PF SG_ 1719 KBI_Aussen_Temp_gef 5000;
BA_REL_ "GenSigTimeoutTime" BU_SG_REL_ OCU_PAG_PF SG_ 1719 KBI_Aussen_Temp_gef 5000;
BA_REL_ "GenSigTimeoutTime" BU_SG_REL_ RDK_High_PAG_PF SG_ 1638 KBI_SDruck_VA_komfort 5000;
BA_REL_ "GenSigTimeoutTime" BU_SG_REL_ RDK_High_PAG_PF SG_ 1638 KBI_SDruck_HA_komfort 5000;
BA_REL_ "GenSigTimeoutTime" BU_SG_REL_ RDK_High_PAG_PF SG_ 1638 KBI_SDruck_VA_vmax 5000;
BA_REL_ "GenSigTimeoutTime" BU_SG_REL_ RDK_High_PAG_PF SG_ 1638 KBI_SDruck_HA_vmax 5000;
BA_REL_ "GenSigTimeoutTime" BU_SG_REL_ RDK_High_PAG_PF SG_ 1638 KBI_KomfortDruck 5000;
BA_REL_ "GenSigTimeoutTime" BU_SG_REL_ RDK_High_PAG_PF SG_ 1638 KBI_RDK_Solldruck_neu 5000;
BA_REL_ "GenSigTimeoutTime" BU_SG_REL_ RDK_High_PAG_PF SG_ 1638 KBI_RDK_DDAnz_akt 5000;
BA_REL_ "GenSigTimeoutTime" BU_SG_REL_ RDK_High_PAG_PF SG_ 1638 KBI_RDK_Beladung_neu 5000;
BA_REL_ "GenSigTimeoutTime" BU_SG_REL_ RDK_High_PAG_PF SG_ 1638 KBI_KomfortDruck_V_Warnschwelle 5000;
BA_REL_ "GenSigTimeoutTime" BU_SG_REL_ RDK_High_PAG_PF SG_ 1638 KBI_Rundstreckenmodus 5000;
BA_REL_ "GenSigTimeoutTime" BU_SG_REL_ RDK_High_PAG_PF SG_ 1638 KBI_RS_Druck_uebernehmen 5000;
BA_REL_ "GenSigTimeoutTime" BU_SG_REL_ ADR_PAG_X2 SG_ 794 KBI_V_Anz 1000;
BA_REL_ "GenSigTimeoutTime" BU_SG_REL_ ADR_PAG_X2 SG_ 1725 KBI_Fotosensor 5000;
BA_REL_ "GenSigTimeoutTime" BU_SG_REL_ Klima_PAG_PF SG_ 1725 KBI_Fotosensor 5000;
BA_REL_ "GenSigTimeoutTime" BU_SG_REL_ Miko_PAG_X2 SG_ 1725 KBI_Fotosensor 5000;
BA_REL_ "GenSigTimeoutTime" BU_SG_REL_ Klima_PAG_PF SG_ 1725 KBI_KL58d 5000;
BA_REL_ "GenSigTimeoutTime" BU_SG_REL_ Miko_PAG_X2 SG_ 1725 KBI_KL58d 5000;
BA_REL_ "GenSigTimeoutTime" BU_SG_REL_ ADR_PAG_X2 SG_ 1725 KBI_KL58s 5000;
BA_REL_ "GenSigTimeoutTime" BU_SG_REL_ Klima_PAG_PF SG_ 1725 KBI_KL58s 5000;
BA_REL_ "GenSigTimeoutTime" BU_SG_REL_ Miko_PAG_X2 SG_ 1725 KBI_KL58s 5000;
BA_REL_ "GenSigTimeoutTime" BU_SG_REL_ GW_App_PAG_PF SG_ 1725 KBI_Uebern 5000;
BA_REL_ "GenSigTimeoutTime" BU_SG_REL_ GW_App_PAG_PF SG_ 1725 KBI_Uhr_Verstellung 5000;
VAL_ 1516 FT_Tuer_geoeffnet 1 "Tuer offen" ;
VAL_ 1516 BT_Tuer_geoeffnet 1 "Tuer_offen" ;
VAL_ 1516 HL_Tuer_geoeffnet 1 "Tuer geoeffnet" ;
VAL_ 1516 HR_Tuer_geoeffnet 1 "Tuer offen" ;
VAL_ 1516 FT_verriegelt 1 "verriegelt" ;
VAL_ 1516 FT_Kisi_li_aktiv 0 "inaktiv" 1 "aktiv" ;
VAL_ 1516 FT_Kisi_Fehler 0 "kein_Fehler" 1 "Fehler" ;
VAL_ 1516 F_TSG_FT_01_Mmi 0 "aktuell" 1 "veraltet" ;
VAL_ 1516 F_TSG_BT_01_Mmi 0 "aktuell" 1 "veraltet" ;
VAL_ 1516 F_TSG_HL_01_Mmi 0 "aktuell" 1 "veraltet" ;
VAL_ 1516 F_TSG_HR_01_Mmi 0 "aktuell" 1 "veraltet" ;
VAL_ 797 BC_Up_Cursor 0 "nicht_betaetigt" 1 "Bordcomputer up Taste gedrueckt" ;
VAL_ 797 BC_Down_Cursor 0 "nicht_betaetigt" 1 "Bordcomputer down Taste gedrueckt" ;
VAL_ 797 BC_Set 0 "nicht_betaetigt" 1 "betaetigt" ;
VAL_ 797 BC_Reset 0 "nicht_betaetigt" 1 "Bordcomputer Reset Taste gedrueckt" ;
VAL_ 797 T_Push_To_Talk 0 "Taster_nicht_betaetigt" 1 "Taster_betaetigt" ;
VAL_ 797 ALR_Ist_Proz_Anz 251 "res" 252 "res" 253 "keine_Momentenverteilung" 254 "Init" 255 "Fehler" ;
VAL_ 797 BH_Blinker_li 0 "nicht_betaetigt" 1 "Blinkerhebel_Richtung_links_betaetigt" ;
VAL_ 797 BH_Blinker_re 0 "nicht_betaetigt" 1 "Blinkerhebel_Richtung_rechts_betaetigt" ;
VAL_ 797 WH_Intervall 0 "aus" 1 "Wischerhebel in Stellung Intervall" ;
VAL_ 797 LRH_on_off 0 "Keine Anzeige" 1 "Lenradheizung aus" 2 "Lenkradheizung ein" 3 "res" ;
VAL_ 797 LS_Tiptronic_Fehler 0 " i. O." 1 "Fehler erkannt" ;
VAL_ 797 F_SMLS_01_Mmi 0 "aktuell" 1 "veraltet" ;
VAL_ 797 F_LS_01_Mmi 0 "aktuell" 1 "veraltet" ;
VAL_ 797 Allrad_01_alt 0 "aktuell" 1 "veraltet" ;
VAL_ 1092 ZV_FT_offen 1 "FT_geoeffnet" ;
VAL_ 1092 ZV_BT_offen 1 "BT_geoeffnet" ;
VAL_ 1092 ZV_HD_offen 1 "Heckdeckel_auf" ;
VAL_ 1092 ZV_verriegelt_intern_ist 1 "Fahrzeug innen verriegelt; Istzustand" ;
VAL_ 1092 ZV_verriegelt_extern_ist 1 "Fahrzeug_aussen_verriegelt_Istzustand" ;
VAL_ 1092 ZV_gesafet_extern_ist 1 "Fahrzeug aussen gesafet; Istzustand" ;
VAL_ 1092 KST_Warn_P1_ZST_def 0 "nicht_defekt" 1 "defekt" ;
VAL_ 1092 KST_Warn_P2_ZST_def 0 "nicht_defekt" 1 "defekt" ;
VAL_ 1092 STS_Texte 0 "kein_Text" 1 "Text_01" 2 "Text_02" 3 "Text_03" 4 "Text_04" 5 "Text_05" 6 "Text_06" 7 "Text_07" 8 "Text_08" 9 "Text_09" 10 "Text_10" 11 "Text_11" 12 "Text_12" 13 "Text_13" 14 "Init" 15 "Fehler" ;
VAL_ 1092 F_BCM2_02_Mmi 0 "aktuell" 1 "veraltet" ;
VAL_ 1092 F_STS_01_Mmi 0 "aktuell" 1 "veraltet" ;
VAL_ 1315 SVB_MEM_FS 0 "SG_nicht_verbaut" 1 "SG_verbaut" ;
VAL_ 1315 SVB_MEM_BFS 0 "SG_nicht_verbaut" 1 "SG_verbaut" ;
VAL_ 1315 SVB_SMLS 0 "SG_nicht_verbaut" 1 "SG_verbaut" ;
VAL_ 1315 SVB_HDSG 0 "SG_nicht_verbaut" 1 "SG_verbaut" ;
VAL_ 1315 SVB_Lift 0 "SG_nicht_verbaut" 1 "SG_verbaut" ;
VAL_ 1315 SVB_AAG 0 "SG_nicht_verbaut" 1 "SG_verbaut" ;
VAL_ 1315 SVB_TSG_FT 0 "SG_nicht_verbaut" 1 "SG_verbaut" ;
VAL_ 1315 SVB_TSG_BT 0 "SG_nicht_verbaut" 1 "SG_verbaut" ;
VAL_ 1315 SVB_RDK 0 "SG_nicht_verbaut" 1 "SG_verbaut" ;
VAL_ 1315 SVB_BCM1 0 "SG_nicht_verbaut" 1 "SG_verbaut" ;
VAL_ 1315 SVB_BCM2 0 "SG_nicht_verbaut" 1 "SG_verbaut" ;
VAL_ 1315 SVB_TSG_HL 0 "SG_nicht_verbaut" 1 "SG_verbaut" ;
VAL_ 1315 SVB_TSG_HR 0 "SG_nicht_verbaut" 1 "SG_verbaut" ;
VAL_ 1315 SVB_VSG 0 "SG_nicht_verbaut" 1 "SG_verbaut" ;
VAL_ 1315 SVB_Topview 0 "SG_nicht_verbaut" 1 "SG_verbaut" ;
VAL_ 1315 SVB_Kombi 0 "SG_nicht_verbaut" 1 "SG_verbaut" ;
VAL_ 1315 SVB_BKE 0 "SG_nicht_verbaut" 1 "SG_verbaut" ;
VAL_ 1315 SVB_PDC 0 "SG_nicht_verbaut" 1 "SG_verbaut" ;
VAL_ 1315 SVB_STH 0 "SG_nicht_verbaut" 1 "SG_verbaut" ;
VAL_ 1315 SVB_RearView 0 "SG_nicht_verbaut" 1 "SG_verbaut" ;
VAL_ 1315 SVB_Stoppuhr 0 "SG_nicht_verbaut" 1 "SG_verbaut" ;
VAL_ 1315 SVB_PCM 0 "SG_nicht_verbaut" 1 "SG_verbaut" ;
VAL_ 1315 SVB_CDR 0 "SG_nicht_verbaut" 1 "SG_verbaut" ;
VAL_ 1315 SVB_Kompass 0 "SG_nicht_verbaut" 1 "SG_verbaut" ;
VAL_ 1315 SVB_ComBox 0 "SG_nicht_verbaut" 1 "SG_verbaut" ;
VAL_ 1315 SVB_LEH_VA 0 "SG_nicht_verbaut" 1 "SG_verbaut" ;
VAL_ 1315 SVB_Ladegeraet 0 "SG_nicht_verbaut" 1 "SG_verbaut" ;
VAL_ 1315 SVB_Motor 0 "SG_nicht_verbaut" 1 "SG_verbaut" ;
VAL_ 1315 SVB_QSP 0 "SG_nicht_verbaut" 1 "SG_verbaut" ;
VAL_ 1315 SVB_Getriebe 0 "SG_nicht_verbaut" 1 "SG_verbaut" ;
VAL_ 1315 SVB_WHL 0 "SG_nicht_verbaut" 1 "SG_verbaut" ;
VAL_ 1315 SVB_Airbag 0 "SG_nicht_verbaut" 1 "SG_verbaut" ;
VAL_ 1315 SVB_PSM_Ant 0 "SG_nicht_verbaut" 1 "SG_verbaut" ;
VAL_ 1315 SVB_PSM_Fwk 0 "SG_nicht_verbaut" 1 "SG_verbaut" ;
VAL_ 1315 SVB_BMS 0 "SG_nicht_verbaut" 1 "SG_verbaut" ;
VAL_ 1315 SVB_LEH 0 "SG_nicht_verbaut" 1 "SG_verbaut" ;
VAL_ 1315 SVB_SCR 0 "SG_nicht_verbaut" 1 "SG_verbaut" ;
VAL_ 1315 SVB_EPB 0 "SG_nicht_verbaut" 1 "SG_verbaut" ;
VAL_ 1315 SVB_SSC 0 "SG_nicht_verbaut" 1 "SG_verbaut" ;
VAL_ 1315 SVB_PDCC 0 "SG_nicht_verbaut" 1 "SG_verbaut" ;
VAL_ 1315 SVB_LWS 0 "SG_nicht_verbaut" 1 "SG_verbaut" ;
VAL_ 1315 SVB_PASM_NRA 0 "SG_nicht_verbaut" 1 "SG_verbaut" ;
VAL_ 1315 SVB_Allrad 0 "SG_nicht_verbaut" 1 "SG_verbaut" ;
VAL_ 1315 SVB_EPS 0 "SG_nicht_verbaut" 1 "SG_verbaut" ;
VAL_ 1315 SVB_HAL 0 "SG_nicht_verbaut" 1 "SG_verbaut" ;
VAL_ 1315 SVB_EBKV 0 "SG_nicht_verbaut" 1 "SG_verbaut" ;
VAL_ 1315 SVB_AFS 0 "SG_nicht_verbaut" 1 "SG_verbaut" ;
VAL_ 1315 SVB_SWL 0 "SG_nicht_verbaut" 1 "SG_verbaut" ;
VAL_ 1315 SVB_SWR 0 "SG_nicht_verbaut" 1 "SG_verbaut" ;
VAL_ 1315 SVB_ACC 0 "SG_nicht_verbaut" 1 "SG_verbaut" ;
VAL_ 1315 SVB_SWA 0 "SG_nicht_verbaut" 1 "SG_verbaut" ;
VAL_ 1315 SVB_EHPS 0 "SG_nicht_verbaut" 1 "SG_verbaut" ;
VAL_ 1315 SVB_EKK 0 "SG_nicht_verbaut" 1 "SG_verbaut" ;
VAL_ 1315 SVB_Kamera 0 "SG_nicht_verbaut" 1 "SG_verbaut" ;
VAL_ 1315 SVB_AMP 0 "SG_nicht_verbaut" 1 "SG_verbaut" ;
VAL_ 1315 SVB_TV 0 "SG_nicht_verbaut" 1 "SG_verbaut" ;
VAL_ 1428 HVLM_Restladezeit_HV_Bat_02 510 "Init" 511 "Fehler" ;
VAL_ 1428 HVLM_Lademodus_HV_Bat 0 "Sofortlademodus" 1 "zeitversetztes_Laden" ;
VAL_ 1428 HVLM_Bat_laden_aktiv 0 "inaktiv" 1 "aktiv" ;
VAL_ 1428 HVLM_Ladeart 0 "keine_Auswahl" 1 "AC_Laden" 2 "DC_Laden" 3 "Konditionierung" ;
VAL_ 1428 HVLM_VK_Anf 0 "nicht_angefordert" 1 "angefordert" ;
VAL_ 1428 HVLM_Ladesystemhinweise 0 "kein_Hinweis" 1 "Ladesystem_defekt" 2 "Ladesaeule_inkompatibel" 3 "DC_Laden_nicht_moeglich" ;
VAL_ 1428 HVLM_Stecker_Status 0 "Init" 1 "kein_Stecker_gesteckt" 2 "Stecker_erkannt_nicht_verriegelt" 3 "Stecker_erkannt_und_verriegelt" ;
VAL_ 1428 HVLM_Langzeit_Laden 0 "keine_Anforderung" 1 "Anforderung_Reduzierung_Batterie_SOC_auf_Stufe_1" 2 "Anforderung_Reduzierung_Batterie_SOC_auf_Stufe_2" 3 "Fehler" ;
VAL_ 1428 HVLM_Klima_Temp 29 "VW_high_30C" 30 "Init" 31 "Fehler" ;
VAL_ 1397 HVLM_Status_Timer_MUX 0 "leer" 1 "Timer_1" 2 "Timer_2" 3 "Timer_3" 4 "Timer_4" 5 "reserviert" 6 "reserviert" 7 "Timer_7" ;
VAL_ 1397 HVLM_Status_Timer_1_Jahr 126 "Init" 127 "reserviert" ;
VAL_ 1397 HVLM_Status_Timer_2_Jahr 126 "Init" 127 "reserviert" ;
VAL_ 1397 HVLM_Status_Timer_3_Jahr 126 "Init" 127 "reserviert" ;
VAL_ 1397 HVLM_Status_Timer_4_Jahr 126 "Init" 127 "reserviert" ;
VAL_ 1397 HVLM_Status_Timer_7_Jahr 126 "Init" 127 "reserviert" ;
VAL_ 1397 HVLM_Status_Timer_1_Minute 60 "reserviert" 61 "reserviert" 62 "Init" 63 "Fehler" ;
VAL_ 1397 HVLM_Status_Timer_2_Minute 60 "reserviert" 61 "reserviert" 62 "Init" 63 "Fehler" ;
VAL_ 1397 HVLM_Status_Timer_3_Minute 60 "reserviert" 61 "reserviert" 62 "Init" 63 "Fehler" ;
VAL_ 1397 HVLM_Status_Timer_4_Minute 60 "reserviert" 61 "reserviert" 62 "Init" 63 "Fehler" ;
VAL_ 1397 HVLM_Status_Timer_7_Minute 60 "reserviert" 61 "reserviert" 62 "Init" 63 "Fehler" ;
VAL_ 1397 HVLM_Status_Timer_1_Monat 0 "Init" 14 "reserviert" 15 "Fehler" ;
VAL_ 1397 HVLM_Status_Timer_2_Monat 0 "Init" 14 "reserviert" 15 "Fehler" ;
VAL_ 1397 HVLM_Status_Timer_3_Monat 0 "Init" 14 "reserviert" 15 "Fehler" ;
VAL_ 1397 HVLM_Status_Timer_4_Monat 0 "Init" 14 "reserviert" 15 "Fehler" ;
VAL_ 1397 HVLM_Status_Timer_7_Monat 0 "Init" 14 "reserviert" 15 "Fehler" ;
VAL_ 1397 HVLM_Status_Timer_1_Stunde 24 "reserviert" 25 "reserviert" 26 "reserviert" 27 "reserviert" 28 "reserviert" 29 "reserviert" 30 "Init" 31 "Fehler" ;
VAL_ 1397 HVLM_Status_Timer_2_Stunde 24 "reserviert" 25 "reserviert" 26 "reserviert" 27 "reserviert" 28 "reserviert" 29 "reserviert" 30 "Init" 31 "Fehler" ;
VAL_ 1397 HVLM_Status_Timer_3_Stunde 24 "reserviert" 25 "reserviert" 26 "reserviert" 27 "reserviert" 28 "reserviert" 29 "reserviert" 30 "Init" 31 "Fehler" ;
VAL_ 1397 HVLM_Status_Timer_4_Stunde 24 "reserviert" 25 "reserviert" 26 "reserviert" 27 "reserviert" 28 "reserviert" 29 "reserviert" 30 "Init" 31 "Fehler" ;
VAL_ 1397 HVLM_Status_Timer_7_Stunde 24 "reserviert" 25 "reserviert" 26 "reserviert" 27 "reserviert" 28 "reserviert" 29 "reserviert" 30 "Init" 31 "Fehler" ;
VAL_ 1397 HVLM_Status_Timer_1_Tag 0 "Init" ;
VAL_ 1397 HVLM_Status_Timer_2_Tag 0 "Init" ;
VAL_ 1397 HVLM_Status_Timer_3_Tag 0 "Init" ;
VAL_ 1397 HVLM_Status_Timer_4_Tag 0 "Init" ;
VAL_ 1397 HVLM_Status_Timer_7_Tag 0 "Init" ;
VAL_ 1397 HVLM_Status_Timer_1_Laden 0 "Timer_nicht_aktiv" 1 "Timer_aktiv" ;
VAL_ 1397 HVLM_Status_Timer_2_Laden 0 "Timer_nicht_aktiv" 1 "Timer_aktiv" ;
VAL_ 1397 HVLM_Status_Timer_3_Laden 0 "Timer_nicht_aktiv" 1 "Timer_aktiv" ;
VAL_ 1397 HVLM_Status_Timer_4_Laden 0 "Timer_nicht_aktiv" 1 "Timer_aktiv" ;
VAL_ 1397 HVLM_Status_Timer_1_Vorklima 0 "Timer_nicht_aktiv" 1 "Timer_aktiv" ;
VAL_ 1397 HVLM_Status_Timer_2_Vorklima 0 "Timer_nicht_aktiv" 1 "Timer_aktiv" ;
VAL_ 1397 HVLM_Status_Timer_3_Vorklima 0 "Timer_nicht_aktiv" 1 "Timer_aktiv" ;
VAL_ 1397 HVLM_Status_Timer_4_Vorklima 0 "Timer_nicht_aktiv" 1 "Timer_aktiv" ;
VAL_ 1397 HVLM_Status_Timer_1_Zyklus_Mo 0 "Timer_am_Wochentag_nicht_aktiv" 1 "Timer_am_Wochentag_aktiv" ;
VAL_ 1397 HVLM_Status_Timer_2_Zyklus_Mo 0 "Timer_am_Wochentag_nicht_aktiv" 1 "Timer_am_Wochentag_aktiv" ;
VAL_ 1397 HVLM_Status_Timer_3_Zyklus_Mo 0 "Timer_am_Wochentag_nicht_aktiv" 1 "Timer_am_Wochentag_aktiv" ;
VAL_ 1397 HVLM_Status_Timer_4_Zyklus_Mo 0 "Timer_am_Wochentag_nicht_aktiv" 1 "Timer_am_Wochentag_aktiv" ;
VAL_ 1397 HVLM_Status_Timer_1_Zyklus_Di 0 "Timer_am_Wochentag_nicht_aktiv" 1 "Timer_am_Wochentag_aktiv" ;
VAL_ 1397 HVLM_Status_Timer_2_Zyklus_Di 0 "Timer_am_Wochentag_nicht_aktiv" 1 "Timer_am_Wochentag_aktiv" ;
VAL_ 1397 HVLM_Status_Timer_3_Zyklus_Di 0 "Timer_am_Wochentag_nicht_aktiv" 1 "Timer_am_Wochentag_aktiv" ;
VAL_ 1397 HVLM_Status_Timer_4_Zyklus_Di 0 "Timer_am_Wochentag_nicht_aktiv" 1 "Timer_am_Wochentag_aktiv" ;
VAL_ 1397 HVLM_Status_Timer_1_Zyklus_Mi 0 "Timer_am_Wochentag_nicht_aktiv" 1 "Timer_am_Wochentag_aktiv" ;
VAL_ 1397 HVLM_Status_Timer_2_Zyklus_Mi 0 "Timer_am_Wochentag_nicht_aktiv" 1 "Timer_am_Wochentag_aktiv" ;
VAL_ 1397 HVLM_Status_Timer_3_Zyklus_Mi 0 "Timer_am_Wochentag_nicht_aktiv" 1 "Timer_am_Wochentag_aktiv" ;
VAL_ 1397 HVLM_Status_Timer_4_Zyklus_Mi 0 "Timer_am_Wochentag_nicht_aktiv" 1 "Timer_am_Wochentag_aktiv" ;
VAL_ 1397 HVLM_Status_Timer_1_Zyklus_Do 0 "Timer_am_Wochentag_nicht_aktiv" 1 "Timer_am_Wochentag_aktiv" ;
VAL_ 1397 HVLM_Status_Timer_2_Zyklus_Do 0 "Timer_am_Wochentag_nicht_aktiv" 1 "Timer_am_Wochentag_aktiv" ;
VAL_ 1397 HVLM_Status_Timer_3_Zyklus_Do 0 "Timer_am_Wochentag_nicht_aktiv" 1 "Timer_am_Wochentag_aktiv" ;
VAL_ 1397 HVLM_Status_Timer_4_Zyklus_Do 0 "Timer_am_Wochentag_nicht_aktiv" 1 "Timer_am_Wochentag_aktiv" ;
VAL_ 1397 HVLM_Status_Timer_1_Zyklus_Fr 0 "Timer_am_Wochentag_nicht_aktiv" 1 "Timer_am_Wochentag_aktiv" ;
VAL_ 1397 HVLM_Status_Timer_2_Zyklus_Fr 0 "Timer_am_Wochentag_nicht_aktiv" 1 "Timer_am_Wochentag_aktiv" ;
VAL_ 1397 HVLM_Status_Timer_3_Zyklus_Fr 0 "Timer_am_Wochentag_nicht_aktiv" 1 "Timer_am_Wochentag_aktiv" ;
VAL_ 1397 HVLM_Status_Timer_4_Zyklus_Fr 0 "Timer_am_Wochentag_nicht_aktiv" 1 "Timer_am_Wochentag_aktiv" ;
VAL_ 1397 HVLM_Status_Timer_1_Zyklus_Sa 0 "Timer_am_Wochentag_nicht_aktiv" 1 "Timer_am_Wochentag_aktiv" ;
VAL_ 1397 HVLM_Status_Timer_2_Zyklus_Sa 0 "Timer_am_Wochentag_nicht_aktiv" 1 "Timer_am_Wochentag_aktiv" ;
VAL_ 1397 HVLM_Status_Timer_3_Zyklus_Sa 0 "Timer_am_Wochentag_nicht_aktiv" 1 "Timer_am_Wochentag_aktiv" ;
VAL_ 1397 HVLM_Status_Timer_4_Zyklus_Sa 0 "Timer_am_Wochentag_nicht_aktiv" 1 "Timer_am_Wochentag_aktiv" ;
VAL_ 1397 HVLM_Status_Timer_1_Zyklus_So 0 "Timer_am_Wochentag_nicht_aktiv" 1 "Timer_am_Wochentag_aktiv" ;
VAL_ 1397 HVLM_Status_Timer_2_Zyklus_So 0 "Timer_am_Wochentag_nicht_aktiv" 1 "Timer_am_Wochentag_aktiv" ;
VAL_ 1397 HVLM_Status_Timer_3_Zyklus_So 0 "Timer_am_Wochentag_nicht_aktiv" 1 "Timer_am_Wochentag_aktiv" ;
VAL_ 1397 HVLM_Status_Timer_4_Zyklus_So 0 "Timer_am_Wochentag_nicht_aktiv" 1 "Timer_am_Wochentag_aktiv" ;
VAL_ 1397 HVLM_Status_Timer_1_Zyklus_WH 0 "zyklisch" 1 "einmalig" ;
VAL_ 1397 HVLM_Status_Timer_2_Zyklus_WH 0 "zyklisch" 1 "einmalig" ;
VAL_ 1397 HVLM_Status_Timer_3_Zyklus_WH 0 "zyklisch" 1 "einmalig" ;
VAL_ 1397 HVLM_Status_Timer_4_Zyklus_WH 0 "zyklisch" 1 "einmalig" ;
VAL_ 1397 HVLM_Status_Nachtstrom_X_Std_Anf 62 "Init" 63 "ungueltig" ;
VAL_ 1397 HVLM_Status_Nachtstrom_Prof 0 "keine_Aktion" 1 "Profil_1_setzen" 2 "Profil_2_setzen" 3 "Profil_3_setzen" ;
VAL_ 1397 HVLM_Status_Nachtstrom_X_Std_End 62 "Init" 63 "ungueltig" ;
VAL_ 1397 HVLM_Status_Nachtstrom_Akt_Prof 0 "kein_Profil_gesetzt" 1 "Profil_1_aktiv" 2 "Profil_2_aktiv" 3 "Profil_3_aktiv" ;
VAL_ 1397 HVLM_Status_Laden 0 "Ladefehler" 1 "Laden_aktv" 2 "Laden_unterbrochen" 3 "Laden_beendet" 4 "Ladung_extern_unterbrochen" 5 "Ladung_standby" 6 "Init" 7 "Fehler" ;
VAL_ 1424 KY_Funkschl_Nr 0 "kein authorisierter Schluessel erkannt" 1 "aktive_Funkschluessel_Nr_01" 2 "aktive_Funkschluessel_Nr_02" 3 "aktive_Funkschluessel_Nr_03" 4 "aktive_Funkschluessel_Nr_04" 5 "aktive_Funkschluessel_Nr_05" 6 "aktive_Funkschluessel_Nr_06" 7 "aktive_Funkschluessel_Nr_07" 8 "aktive_Funkschluessel_Nr_08" 9 "ungueltig_09" 10 "ungueltig_10" 11 "ungueltig_11" 12 "ungueltig_12" 13 "ungueltig_13" 14 "ungueltig_14" 15 "ungueltig_15" ;
VAL_ 1424 KY_ID_Geb_autorisiert 0 "Schluessel_nicht_authorisiert" 1 "Schluessel authorisiert" ;
VAL_ 1424 KY_ID_Geb_steckt 0 "kein_Schluessel_im_Zuendschloss" 1 " Schluessel steckt im Zuendschloss" ;
VAL_ 1424 KY_FFB_Frequenz 1 "433 MHz" 2 "315 MHz" 3 "868 MHz" ;
VAL_ 1424 KY_HF_Aktiv 0 "Funktempfang_nicht_aktiv" 1 "HF_Funkempfang_aktiv" ;
VAL_ 1424 KY_LF_Aktiv 0 "Funktempfang_nicht_aktiv" 1 "LF_Funkempfang_aktiv" ;
VAL_ 1424 KY_ELV_verr 0 "ELV_nicht_verriegelt" 1 "ELV verriegelt" ;
VAL_ 1424 KY_ELV_entr 0 "ELV_nicht_entriegelt" 1 "ELV entriegelt" ;
VAL_ 1424 KY_ELV_enable_Anforderung 0 "Freigabe_nicht_angefordert" 1 "Freigabe ELV wird angefordert" ;
VAL_ 1424 KY_Valet_Parking 0 "kein_Valet_Schluessel_erkannt" 1 "Valet Schluessel erkannt" ;
VAL_ 1424 KY_Keyless_Verbau 0 "nicht_verbaut" 1 "verbaut" ;
VAL_ 1424 FBS_Warn_Lenkung_def 0 "iO" 1 "defekt" ;
VAL_ 1424 FBS_Warn_LenkVerriegelung_def 0 "i.O." 1 "defekt" ;
VAL_ 1424 FBS_Warn_Schluessel_Batt 0 "i.O." 1 "defekt" ;
VAL_ 1424 FBS_Prio_Warn_04 1 "Kombi Prio Warnung FBS 4" ;
VAL_ 1424 FBS_Prio_Warn_05 1 "Kombi Prio Warnung FBS 5" ;
VAL_ 1424 KYL_Warn_kein_Schluessel 1 "kein Schluessel erkannt" ;
VAL_ 1424 KYL_Warn_Kessy_defekt 0 "Kessy_i.O." 1 "Kessy defekt" ;
VAL_ 1424 KY_KYL_Prio_Warn_03 1 "Kombi Prio Warnung Keyless 3" ;
VAL_ 1424 KY_KYL_Prio_Warn_04 1 "Kombi Prio Warnung Keyless 4" ;
VAL_ 1424 KY_KYL_Prio_Warn_05 1 "Kombi Prio Warnung Keyless 5" ;
VAL_ 1424 KY_WFS_Safe 1 "WFS nicht deaktiviert" ;
VAL_ 1424 KY_WFS_LZ 0 "nicht def." 1 "LZ 1" 2 "LZ 2" 3 "LZ 3" ;
VAL_ 1424 KY_StartStopp_Info 0 "Motorlauf_nicht_notwendig_(Stoppfreigabe)" 1 "Motoranlauf_nicht_zwingend_notwendig_(Stoppverbot,keine_Startanforderung)" 2 "Motoranlauf_zwingend_notwendig_(Startanforderung)" 3 "Systemfehler" ;
VAL_ 1424 KYL_Notzuendschloss 0 "nicht_verbaut" 1 "verbaut" ;
VAL_ 1424 KYL_Warn_Notzuendschloss 0 "Aus" 1 "Ein" ;
VAL_ 1424 FBS_KD_Fehler 0 "kein_KD_Fehler" 1 "KD_Fehler" ;
VAL_ 1424 SK_Anf_DTC_Abfrage 1 "DTC_Abfrage" ;
VAL_ 1424 SK_Anf_DTC_Abfrage_sofort 1 "DTC_Abfrage_sofort" ;
VAL_ 960 ZV_verriegelt_extern_soll_02 1 "Fahrzeug verriegelt extern; Sollzusstand" ;
VAL_ 960 ZAS_Kl_S 0 "aus" 1 "S_Kontakt_ein" ;
VAL_ 960 ZAS_Kl_15 0 "aus" 1 "ein" ;
VAL_ 960 ZAS_Kl_X 0 "aus" 1 "ein" ;
VAL_ 960 ZAS_Kl_50 0 "aus" 1 "KL50_ein_Startwunsch_Fahrer" ;
VAL_ 959 KL_Drehz_Anh 0 "keine_Anhebung" 1 "Drehzahlanhebung_vom_Motor_angefordert" ;
VAL_ 959 KL_Vorwarn_Komp_ein 0 "Init" 1 "Vorwarnung_Kompressor_ein" ;
VAL_ 959 KL_Handshake_BEM 0 "keine_Leistungsaenderung_in_den_Heizsystemen_aktiv" 1 "Heizleistungsaenderung_wird_gerade_durchgefuehrt" ;
VAL_ 959 KL_Komp_Moment_alt 1 "veraltet_bzw_Ermittlung_des_Moments_nicht_moeglich__zB_keine_Drehzahl_kein_Kaeltemitteldruck" ;
VAL_ 959 KL_Vorwarn_HHS_ein 1 "Vorwarnung_Heckscheibenheizung_ein" ;
VAL_ 959 KL_Vorwarn_HFS_ein 1 "Vorwarnung_Frontscheibenheizung_ein" ;
VAL_ 959 KL_Vorwarn_Zuheizer_ein 0 "keine_Vorwarnung" 1 "Vorwarnung_Zuheizer_ein" ;
VAL_ 959 KL_KD_Fehler 0 "kein_KD_Fehler" 1 "KD_Fehler" ;
VAL_ 959 KL_Comp_rev_rq 255 "Fehler" ;
VAL_ 959 KL_Charisma_FahrPr 0 "nicht_belegt" 1 "Programm_1" 2 "Programm_2" 3 "Programm_3" 4 "Programm_4" 5 "Programm_5" 6 "Programm_6" 7 "Programm_7" ;
VAL_ 959 KL_Charisma_Status 0 "Init" 1 "verfuegbar" 2 "nicht_verfuegbar" 3 "asynchron_durch_Fahrerwunsch" ;
VAL_ 959 KL_Charisma_Umschaltung 0 "Idle" 1 "Erkennung_Umschaltaufforderung" 2 "Steuerbotschaft_nicht_definiert" 3 "Umschaltung_verzoegert" ;
VAL_ 959 KL_Last_Kompr 255 "Fehler" ;
VAL_ 959 KL_Anf_KL 255 "Fehler" ;
VAL_ 959 KL_4_Zonen 0 "2_Zonen_Klimaanlage" 1 "4_Zonen_Klimaanlage" ;
VAL_ 959 KL_AC_Schalter 0 "aus" 1 "ein" ;
VAL_ 959 KL_Zustand 0 "aus" 1 "ein" ;
VAL_ 959 KL_Thermomanagement 0 "keine_Freigabe_TMM__max_Heizbedarf" 1 "kleine_Freigabe_TMM" 2 "mittlere_Freigabe_TMM" 3 "volle_Freigabe_TMM__kein_Heizbedarf" ;
VAL_ 959 KL_Comp_enable 0 "Disable" 1 "Enable" ;
VAL_ 959 KL_StartStopp_Info 0 "Motorlauf_nicht_notwendig_(Stoppfreigabe)" 1 "Motoranlauf_nicht_zwingend_notwendig_(Stoppverbot,keine_Startanforderung)" 2 "Motoranlauf_zwingend_notwendig_(Startanforderung)" 3 "Systemfehler" ;
VAL_ 959 KL_el_Zuheizer_Stufe 0 "Aus" 1 "Stufe_1" 2 "Stufe_2" 3 "Stufe_3" ;
VAL_ 959 KL_Diag_Absperrvent 0 "kein_Fehler" 1 "KS-" 2 "KS+" 3 "OC" 4 "OOR+" 5 "OOR-" 6 "RC+" 7 "RC-" 8 "KS+/OC" 9 "KS-/OC" 10 "KS-/KS+" 11 "KS-/KS+/OC" ;
VAL_ 1636 KL_Stromsparmodus 0 "keine_Funktionsbeeintraechtigung_durch_BEM" 1 "Abschaltung_durch_BEM" ;
VAL_ 1636 KL_Spg_Hzg_aus 1 "Spiegelheizung_ausschalten" ;
VAL_ 1636 KL_AQS_Empfindlichkeit 0 "max__Empfindlichkeit" 1 "Empfindlichkeit" 2 "Standard_Empfindlichkeit" 3 "Unempfindlichkeit" 4 "max__Unempfindlichkeit" ;
VAL_ 1636 KL_SIH_Takt_li 0 "Aus" 1 "Ein" ;
VAL_ 1636 KL_LRH_aus 0 "Funktion_LRH_erlaubt" 1 "Funktion_LRH_nicht_erlaubt" ;
VAL_ 1636 KL_SIH_Takt_re 0 "Aus" 1 "Ein" ;
VAL_ 1636 KL_Beschlagsgefahr 0 "keine_Beschlagsgefahr" 1 "Beschlagsgefahr" ;
VAL_ 1636 KL_HSH_ein_Soll 0 "Fahrerwunsch_HSH_aus" 1 "Fahrerwunsch_HSH_ein" ;
VAL_ 1636 KL_HSH_Taktung 0 "Aus" 1 "Ein" ;
VAL_ 1636 KL_Zuheizer_Freigabe 0 "keine_Freigabe_Zuheizer" 1 "Zuheizerfreigabe" ;
VAL_ 1636 KL_ZHE_Status 0 "aus" 1 "eingeschaltet" ;
VAL_ 1636 KL_FSH_Status 0 "aus" 1 "ein" 2 "tbd" 3 "Fehler" ;
VAL_ 1636 KL_LRH_on_off 0 "Aus" 1 "Ein" ;
VAL_ 1636 KL_Umluftklappe_Status 0 "Frischluft" 1 "Teilumluft_10" 2 "Teilumluft_20" 3 "Teilumluft_30" 4 "Teilumluft_40" 5 "Teilumluft_50" 6 "Teilumluft_60" 7 "Teilumluft_70" 8 "Teilumluft_80" 9 "Teilumluft_90" 10 "Umluft" 15 "Fehler" ;
VAL_ 1636 KL_Geblaese_Status 0 "Geblaese_aus" 1 "Geblaesestufe_10" 2 "Geblaesestufe_20" 3 "Geblaesestufe_30" 4 "Geblaesestufe_40" 5 "Geblaesestufe_50" 6 "Geblaesestufe_60" 7 "Geblaesestufe_70" 8 "Geblaesestufe_80" 9 "Geblaesestufe_90" 10 "Geblaesestufe_100" 14 "Init" 15 "Fehler" ;
VAL_ 1636 KL_I_Geblaese 255 "Fehler" ;
VAL_ 1636 KL_Kompressorstrom_soll 1023 "Fehler" ;
VAL_ 1636 KL_FSH_P_Soll 63 "Fehler" ;
VAL_ 1646 KL_STL_aktiv 0 "Standlueftung_nicht_aktiv" 1 "Standlueftung_aktiv" ;
VAL_ 1646 KL_STH_aktiv 0 "Standheizung_nicht_aktiv" 1 "Standheizung_aktiv" ;
VAL_ 1646 KL_Solarluefter_aktiv 0 "Solarluefter_nicht_aktiv" 1 "Solarluefter_aktiv__auto" ;
VAL_ 1646 KL_Umluft_Taste 0 "Taste_nicht_gedrueckt" 1 "Taste_gedrueckt" ;
VAL_ 1646 KL_Geblaese_Fond_Status 0 "Geblaese_aus" 1 "Geblaesestufe_10" 2 "Geblaesestufe_20" 3 "Geblaesestufe_30" 4 "Geblaesestufe_40" 5 "Geblaesestufe_50" 6 "Geblaesestufe_60" 7 "Geblaesestufe_70" 8 "Geblaesestufe_80" 9 "Geblaesestufe_90" 10 "Geblaesestufe_100" 14 "Init" 15 "Fehler" ;
VAL_ 1646 KL_STH_Ansteuerung 0 "Aus" 1 "Ein" 2 "Ein_mit_Motorvorwaermung" 3 "Heizleistung_reduziert" ;
VAL_ 1646 KL_Magnetventil 0 "Aus" 1 "Ein" ;
VAL_ 1646 KL_WaPu 0 "Wasserpumpe_aus" 1 "Wasserpumpe_aktiv" ;
VAL_ 1646 KL_Freigabe_KRH_li 0 "aus" 1 "Stufe_1" 2 "Stufe_2" 3 "Stufe_3" 7 "nicht_verfuegbar" ;
VAL_ 1646 KL_Freigabe_KRH_re 0 "aus" 1 "Stufe_1" 2 "Stufe_2" 3 "Stufe_3" 7 "nicht_verfuegbar" ;
VAL_ 1646 KL_BCmE_Livetip_Freigabe 0 "Anzeige_Livetip_nicht_zulaessig" 1 "Anzeige_Livetip_zulaessig" ;
VAL_ 1646 KL_HYB_ASV_hinten_schliessen_Anf 0 "keine_Anforderung" 1 "Ventil_schliessen" ;
VAL_ 1646 KL_HYB_ASV_vorne_schliessen_Anf 0 "keine_Anforderung" 1 "Ventil_schliessen" ;
VAL_ 1646 KL_HYB_Spuelbetrieb_Freigabe 0 "kein_Spuelbetrieb" 1 "Spuelbetrieb_moeglich" ;
VAL_ 1646 KL_Fehler_ElWaPu 0 "kein_Fehler" 1 "Fehler" ;
VAL_ 1646 KL_Innen_Temp 253 "nicht_verbaut" 254 "nicht_verfuegbar" 255 "Fehler" ;
VAL_ 1646 KL_AussenTemp_WK 253 "nicht_verbaut" 254 "Init_Wert__nicht_verfuegbar" 255 "Fehler" ;
VAL_ 1655 KL_T_PSM_off 0 "Taste nicht betaetigt" 1 "Taste betaetigt" ;
VAL_ 1655 KL_T_HSpoiler 0 "Taste nicht betaetigt" 1 "Taste betaetigt" ;
VAL_ 1655 KL_T_PASM_1 0 "Taster nicht betaetigt" 1 "Taster betaetigt" ;
VAL_ 1655 KL_T_PASM_2 0 "Taster nicht betaetigt" 1 "Taster betaetigt" ;
VAL_ 1655 KL_T_FSH 0 "Taster_nicht_betaetigt" 1 "Taster_betaetigt" ;
VAL_ 1655 KL_T_ZV 0 "Taster nicht betaetigt" 1 "Taster betaetigt" ;
VAL_ 1655 KL_T_Abgasklappe 0 "Taster nicht betaetigt" 1 "Taster betaetigt" ;
VAL_ 1655 KL_T_Rollo_kurz 0 "Taster nicht betaetigt" 1 "Taster betaetigt" ;
VAL_ 1655 KL_T_Rollo_lang 0 "Taster nicht betaetigt" 1 "Taster betaetigt" ;
VAL_ 1655 KL_T_STH 0 "Taster nicht betaetigt" 1 "Taster betaetigt" ;
VAL_ 1655 KL_Sportmodus 0 "Normal" 1 "Sport 1" 2 "Sport 2" 3 "Reserve" 4 "Reserve" 5 "Reserve" 6 "Reserve" 7 "Reserve" ;
VAL_ 1655 KL_T_TC_off 0 "nicht_betaetigt" 1 "betaetigt" ;
VAL_ 1655 KL_T_LeVerstFond 0 "keine Betaetigung" 1 "vor" 2 "zurueck" 3 "Fehler" ;
VAL_ 1655 KL_T_SitzLVerstFond 0 "keine Betaetigung" 1 "vor" 2 "zurueck" 3 "Fehler" ;
VAL_ 1655 KL_Charisma_Anzeige 0 "keine_Anzeige" 1 "Anzeige_1_8" 2 "Anzeige_2_9" 3 "Anzeige_3_10" 4 "Anzeige_4_11" 5 "Anzeige_5_12" 6 "Anzeige_6_13" 7 "Anzeige_7_14" ;
VAL_ 1655 KL_Charisma_Anzeige_Umschaltung 0 "Anzeige_Tabelle_1" 1 "Anzeige_Tabelle_2" ;
VAL_ 1655 KL_Segeln_Anf_deaktivieren 0 "Segeln nicht deaktiveren " 1 "Segeln deaktvieren" ;
VAL_ 1655 KL_T_HDC 0 "Taster nicht betaetigt" 1 "Taster betaetigt" ;
VAL_ 1655 HYB_Anf_E_Mode 0 "Taster_nicht_betaetigt" 1 "Taster_betaetigt" ;
VAL_ 1655 FSM_Status 0 "Inaktiv" 1 "Aktiv" ;
VAL_ 1655 KL_Niv_up 0 "aus" 1 "ein" ;
VAL_ 1655 KL_Niv_down 0 "aus" 1 "ein" ;
VAL_ 1655 KL_T_PASM_3 0 "Taster nicht betaetigt" 1 "Taster betaetigt" ;
VAL_ 1655 KL_T_VD 0 "keine_Betaetigung" 1 "oeffnen" 2 "schliessen" 3 "Fehler" ;
VAL_ 1655 KL_T_Windschott 0 "keine_Betaetigung" 1 "oeffnen" 2 "schliessen" 3 "Fehler" ;
VAL_ 1655 KL_St_Atemp 0 "kein Fehler" 1 "Kurzschluss nach Masse" 2 "Kurzschluss gegen Spg > 5V" 3 "Unterbrechung" 4 "Sensorsignal unplausibel" ;
VAL_ 1655 Statusbit_Offroad_aktiv 0 "Offroad nicht aktiv" 1 "Offroad aktiv" ;
VAL_ 1655 KL_T_StSt_deaktiv 0 "Taster_aus" 1 "Taster_ein" ;
VAL_ 1655 KL_T_LDW 0 "nicht_betaetigt" 1 "betaetigt" ;
VAL_ 1655 KL_Atemp_ungef 255 "Fehler" ;
VAL_ 1656 Schalter_MD1Vorne_Vorwahl_3 0 "zu             | nicht_betaetigt" 1 "Position 1   | (m) Schiebelage Zu" 2 "Position 2   | (a) Schiebelage Zu" 3 "Position 3   | (m) Schiebelage Auf" 4 "Position 4   | (a) Schiebelage Auf" 5 "Position 5   | (m) Ausstellage Auf" 6 "Position 6   | (a) Ausstellage Auf" 7 "Position 7   | (m) Ausstellage Zu" 8 "Position 8   | (a) Ausstellage Zu" 9 "Position 9  |" 10 "Position 10 |" 13 "                 | nicht_verfuegbar" 14 "                 | Init" 15 "defekt         | Fehler" ;
VAL_ 1656 Schalter_MD1Vorne_Fehler_3 0 "normal" 1 "Fehler" ;
VAL_ 1656 Schalter_MRolloVorne_zu_3 0 "nicht_betaetigt" 1 "betaetigt" ;
VAL_ 1656 Schalter_MRolloVorne_Fehler_3 0 "normal" 1 "Fehler" ;
VAL_ 1656 Schalter_MRolloVorne_auf_3 0 "nicht_betaetigt" 1 "betaetigt" ;
VAL_ 1656 Schalter_MRolloHinten_zu_3 0 "nicht_betaetigt" 1 "betaetigt" ;
VAL_ 1656 Schalter_MRolloHinten_Fehler_3 0 "normal" 1 "Fehler" ;
VAL_ 1656 Schalter_MRolloHinten_auf_3 0 "nicht_betaetigt" 1 "betaetigt" ;
VAL_ 1656 DK_T_Multi_1 0 "nicht_betaetigt" 1 "betaetigt" ;
VAL_ 1656 DK_F_T_Multi_1 0 "normal" 1 "Fehler" ;
VAL_ 895 KL_AC_LED_an 0 "AC nicht aktiv" 1 "AC aktiv" ;
VAL_ 895 KL_ACmax_LED_an 0 "ACmax nicht aktiv" 1 "ACmax aktiv" ;
VAL_ 895 KL_LVT_O_LED_an 0 "Luftverteilung oben nicht aktiv" 1 "Luftverteilung oben aktiv" ;
VAL_ 895 KL_LVT_M_LED_an 0 "Luftverteilung Mitte nicht aktiv" 1 "Luftverteilung Mitte aktiv" ;
VAL_ 895 KL_LVT_U_LED_an 0 "Luftverteilung unten nicht aktiv" 1 "Luftverteilung unten aktiv" ;
VAL_ 895 KL_Umluft_LED_an 0 "Umluft nicht aktiv" 1 "Umluft aktiv" ;
VAL_ 895 KL_Auto_LED_an 0 "Auto nicht aktiv" 1 "Auto aktiv" ;
VAL_ 1483 KL_WunschStrom_HV 254 "Init" 255 "Fehler" ;
VAL_ 1483 KL_BattKond_WaPu_DZMax 62 "Init" 63 "Fehler" ;
VAL_ 1483 KBT_Defrost_aktiv 0 "inaktiv" 1 "aktiv" ;
VAL_ 1483 KL_T_Charge 0 "Taster nicht betaetigt" 1 "Taster betaetigt" ;
VAL_ 1483 KL_Standklima_Status 0 "Standklimatisierung_aus" 1 "Standklimatisierung_ein" 2 "Nicht_moeglich_Aussenhuelle_offen" 3 "Abbruch_Aussenhuelle_geoeffnet" 4 "Nicht_moeglich_Keine_Aktivierung_HV_Bordnetz" 5 "Abbruch_HV_Bordnetz_deaktiviert" 6 "Nicht_moeglich_Batterie_Prio" 7 "On_hold_Keine_Freigabe_HV_Komponenten" ;
VAL_ 1483 PTC_Wasserauslasstemp 254 "Init" 255 "Fehler" ;
VAL_ 1483 PTC_Wassereinlasstemp 254 "Init" 255 "Fehler" ;
VAL_ 1483 PTC_HV_I_ist 254 "Init" 255 "Fehler" ;
VAL_ 1532 KL_Autobetrieb_HL 0 "kein_Autobetrieb" 1 "Autobetrieb" ;
VAL_ 1532 KL_Autobetrieb_HR 0 "kein_Autobetrieb" 1 "Autobetrieb" ;
VAL_ 1532 KL_Autobetrieb_VL 0 "kein_Autobetrieb" 1 "Autobetrieb" ;
VAL_ 1532 KL_Autobetrieb_VR 0 "kein_Autobetrieb" 1 "Autobetrieb" ;
VAL_ 1532 KL_Zieltemperatur_HL 0 "Lo" 29 "Hi" 30 "Init" 31 "Fehler" ;
VAL_ 1532 KL_Zieltemperatur_HR 0 "Lo" 29 "Hi" 30 "Init" 31 "Fehler" ;
VAL_ 1532 KL_Zieltemperatur_VL 0 "Lo" 29 "Hi" 30 "Init" 31 "Fehler" ;
VAL_ 1532 KL_Zieltemperatur_VR 0 "Lo" 29 "Hi" 30 "Init" 31 "Fehler" ;
VAL_ 1712 FS_Taupunkt 0 "nicht verfuegbar" 1023 "Fehler" ;
VAL_ 1712 FS_ResponseError 0 "normal" 1 "Fehler" ;
VAL_ 1712 FS_Temp_Scheibe 0 "nicht verfuegbar" 1023 "Fehler" ;
VAL_ 1712 FS_Temp_Sensor 0 "nicht verfuegbar" 255 "Fehler" ;
VAL_ 1712 FS_Luftfeuchte_rel 0 "nicht verfuegbar" 255 "Fehler" ;
VAL_ 1625 EKL_KD_Fehler 0 "kein_KD_Fehler" 1 "KD_Fehler" ;
VAL_ 1625 EKL_Comp_SCI_com_stat 0 "normal" 1 "CAN_error" 2 "Inverter_error" 3 "CAN_and_Inverter_error" ;
VAL_ 1625 EKL_Comp_output_stat 0 "normal" 1 "output_line_short" 2 "output_line_cut_out" 3 "abnormal_current_detection" ;
VAL_ 1625 EKL_Comp_main_stat 0 "Comp_not_enabled" 1 "Comp_enabled" ;
VAL_ 1625 EKL_Comp_ovld_stat 0 "normal" 1 "voltage_restriction" 2 "current_restriction" 3 "software_over_current" 4 "over_load" 6 "over_input_current" ;
VAL_ 1625 EKL_Comp_Inv_stat 0 "normal" 1 "start_fail" 2 "temperature_protection" 3 "system_abnormal_stop" ;
VAL_ 1625 EKL_Comp_photo_temp_stat 0 "normal" 1 "over_heat_L" 2 "over_heat_S" 3 "sermister_abnormal" ;
VAL_ 1625 EKL_Comp_photo_temp 255 "Fehler" ;
VAL_ 1625 EKL_Comp_current 255 "Init_not_avail" ;
VAL_ 1625 EKL_Comp_rev_stat 255 "Fehler" ;
VAL_ 779 KBI_ABS_Lampe 0 "ABS Lampe aus" 1 "ABS Lampe ein" ;
VAL_ 779 KBI_ESP_Lampe 0 "ESP Lampe aus" 1 "ESP Lampe ein" ;
VAL_ 779 KBI_BKL_Lampe 0 "BKL aus" 1 "BKL ein" ;
VAL_ 779 KBI_Airbag_Lampe 0 "Airbag Lampe aus" 1 "Airbag Lampe ein" ;
VAL_ 779 KBI_SILA_gueltig 0 "ungueltig" 1 "gueltig" ;
VAL_ 779 KBI_Vorglueh_System_Lampe 0 "Lampe aus" 1 "Lampe ein" ;
VAL_ 779 KBI_NV_in_Anzeige 0 "NV_nicht_in_Anzeige" 1 "NV_in_Anzeige" ;
VAL_ 779 KBI_Anzeigestatus_ACC 0 "keine_ACC_Anzeige" 1 "ACC_Anzeige_aktiv" ;
VAL_ 779 KBI_Tankwarnung 0 "Lampe aus" 1 "Lampe ein" ;
VAL_ 779 KBI_MFA_v_Einheit_01 0 "kmh" 1 "mph" ;
VAL_ 779 KBI_im_Stellgliedtest 0 "kein Stellgliedtest" 1 "Kombi im Stellgliedtest" ;
VAL_ 779 KBI_Anzeigefehler_LDW 0 "nicht vorhanden bzw. unterstützt" 1 "Anzeige iO" 2 "Anzeigefehler" 3 "nicht definiert" ;
VAL_ 779 KBI_Variante_USA 0 "keine USA-Variante" 1 "USA-Variante" ;
VAL_ 779 KBI_Oeldruckwarnung 0 "inaktiv" 1 "aktiv" ;
VAL_ 779 KBI_Handbremse 0 "nicht_angezogen" 1 "angezogen" ;
VAL_ 779 KBI_PLA_in_Anzeige 0 "PLA_nicht_in_Anzeige" 1 "PLA_in_Anzeige" ;
VAL_ 779 KBI_Anzeigefehler_NV 0 "kein_Anzeigefehler" 1 "Anzeigefehler" ;
VAL_ 779 KBI_Einheit_Tacho 0 "km/h" 1 "mph" ;
VAL_ 779 KBI_Konsistenz_ACC 0 "ACC Botschaft konsistent" 1 "ACC Botschaft inkonsistent    " ;
VAL_ 779 KBI_Fehler_Anzeige_ACC 0 " iO" 1 "Anzeigefehler ACC" ;
VAL_ 779 KBI_Anzeigefehler_SWA 0 "nicht vorhanden bzw. unterstützt" 1 "Anzeige iO" 2 "Anzeigefehler" 3 "nicht definiert" ;
VAL_ 779 KBI_KD_Fehler 0 "kein_KD_Fehler" 1 "KD_Fehler" ;
VAL_ 1719 KBI_Kilometerstand 1048574 "Init" 1048575 "Fehler" ;
VAL_ 1719 KBI_Reset_Standzeit 0 "Standzeit iO" 1 "KL30 war weg" ;
VAL_ 1719 KBI_Inhalt_Tank 127 "Fehler" ;
VAL_ 1719 KBI_FStatus_Tank 0 "Tankfüllstand i.O." 1 "Tankfüllstand n.i.O" ;
VAL_ 1719 KBI_Oelwechsel_durchgefuehrt 0 "Oelwechsel_nicht_durchgefuehrt" 1 "Oelwechsel_durchgefuehrt" ;
VAL_ 1719 KBI_QBit_Aussen_Temp_gef 0 "gueltiger_Wert" 1 "Ersatz_Init_oder_Fehlerwert" ;
VAL_ 1719 KBI_Aussen_Temp_gef 253 "nicht verbaut" 254 "Init" 255 "Fehler" ;
VAL_ 1720 KBI_BCmE_aktiv 0 "Anzeige_nicht_aktiv" 1 "Anzeige_aktiv" ;
VAL_ 1720 KBI_Sparhinweis_quittiert 0 "nicht_quittiert" 1 "quittiert" ;
VAL_ 1720 KBI_Tankfuellstand_Prozent 127 "Fehler" ;
VAL_ 1720 KBI_Nachtanken_erkannt 0 "Geberbetrieb" 1 "Nachtankmodus" ;
VAL_ 1720 KBI_Tankinhalt_hochaufl 16382 "Init" 16383 "Fehler" ;
VAL_ 1638 KBI_RDK_Solldruck_neu 0 "Inaktiv" 1 "Aktiv" ;
VAL_ 1638 KBI_RDK_DDAnz_akt 0 "Inaktiv" 1 "Aktiv" ;
VAL_ 1638 KBI_RDK_Beladung_neu 0 "Inaktiv" 1 "Aktiv" ;
VAL_ 1638 ActiveSafe_HMI_Vorwarnung 0 "Vorwarnung ActiveSafe_Stufe2 aus" 1 "Vorwarnung ActiveSafe_Stufe2 ein" ;
VAL_ 1638 ActiveSafe_HMI_FStatus 0 "ActiveSafe_Stufe2 AUS" 1 "1=ActiveSafe_Stufe2 EIN" ;
VAL_ 1638 KBI_KomfortDruck_V_Warnschwelle 0 "Schwelle 160 km/h" 1 "reserviert" 2 "reserviert" 3 "Schwelle 270 km/h" ;
VAL_ 1638 KBI_Rundstreckenmodus 0 "Rundstreckenmodus_nicht_aktiv" 1 "Rundstreckenmodus_aktiv" ;
VAL_ 1638 KBI_RS_Druck_uebernehmen 0 " Druck für Rundstreckenmodue nicht uebernehmen" 1 " Druck für Rundstreckenmodus uebernehmen" ;
VAL_ 794 KBI_Weg_Zaehler_F 0 "kein Fehler" 1 "Fehler" ;
VAL_ 1725 KBI_Fotosensor 254 "Init" 255 "Fehler" ;
VAL_ 1725 KBI_KL58d 255 "Fehler" ;
VAL_ 1725 KBI_KL58s 126 "Init" 127 "Fehler" ;
VAL_ 1725 KBI_Uhr_Verstellung 1 "sofortige Synchronisation der Uhrzeit im Gateway" ;
